[part 11 of 12: package /ComponentTypes]
AUTOSAR XML (schema 4-3-0)
package /ComponentTypes  (continued)
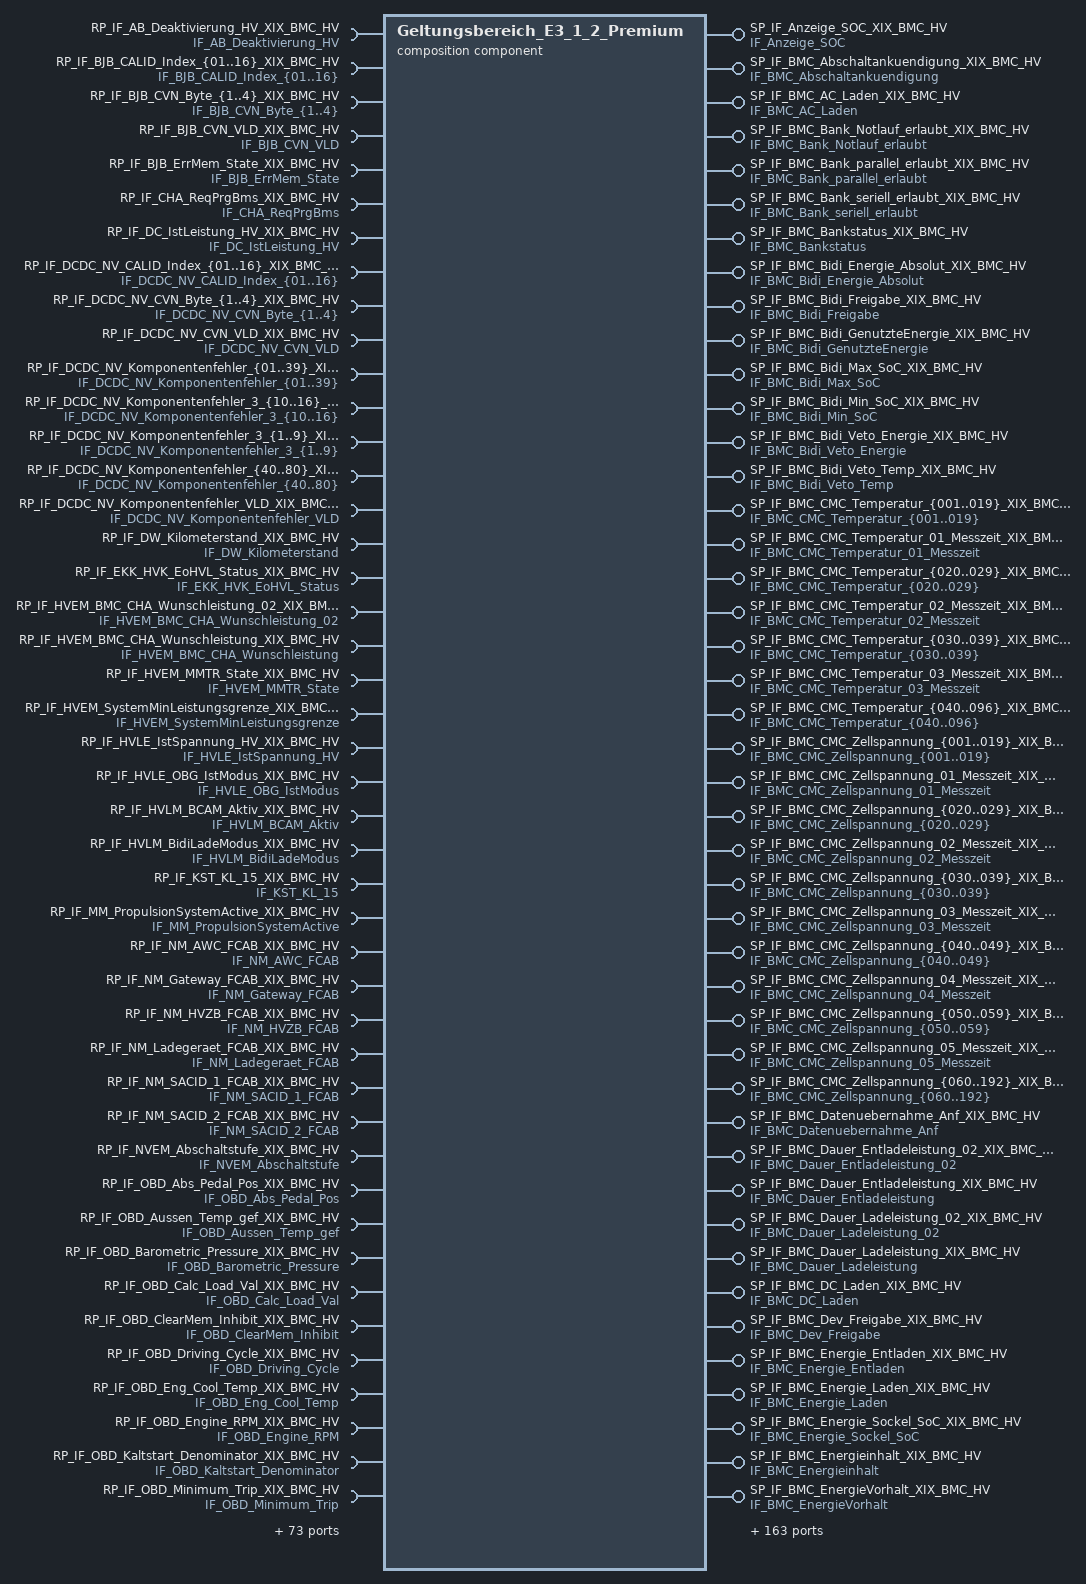
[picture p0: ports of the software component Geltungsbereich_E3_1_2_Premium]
  composition sw component type Geltungsbereich_E3_1_2_Premium
    519 x provide port:
      SP_IF_Anzeige_SOC_XIX_BMC_HV: provided-interface=IF_Anzeige_SOC
      SP_IF_BMC_Abschaltankuendigung_XIX_BMC_HV: provided-interface=IF_BMC_Abschaltankuendigung
      SP_IF_BMC_AC_Laden_XIX_BMC_HV: provided-interface=IF_BMC_AC_Laden
      SP_IF_BMC_Bank_Notlauf_erlaubt_XIX_BMC_HV: provided-interface=IF_BMC_Bank_Notlauf_erlaubt
      SP_IF_BMC_Bank_parallel_erlaubt_XIX_BMC_HV: provided-interface=IF_BMC_Bank_parallel_erlaubt
      SP_IF_BMC_Bank_seriell_erlaubt_XIX_BMC_HV: provided-interface=IF_BMC_Bank_seriell_erlaubt
      SP_IF_BMC_Bankstatus_XIX_BMC_HV: provided-interface=IF_BMC_Bankstatus
      SP_IF_BMC_Bidi_Energie_Absolut_XIX_BMC_HV: provided-interface=IF_BMC_Bidi_Energie_Absolut
      SP_IF_BMC_Bidi_Freigabe_XIX_BMC_HV: provided-interface=IF_BMC_Bidi_Freigabe
      SP_IF_BMC_Bidi_GenutzteEnergie_XIX_BMC_HV: provided-interface=IF_BMC_Bidi_GenutzteEnergie
      SP_IF_BMC_Bidi_Max_SoC_XIX_BMC_HV: provided-interface=IF_BMC_Bidi_Max_SoC
      SP_IF_BMC_Bidi_Min_SoC_XIX_BMC_HV: provided-interface=IF_BMC_Bidi_Min_SoC
      SP_IF_BMC_Bidi_Veto_Energie_XIX_BMC_HV: provided-interface=IF_BMC_Bidi_Veto_Energie
      SP_IF_BMC_Bidi_Veto_Temp_XIX_BMC_HV: provided-interface=IF_BMC_Bidi_Veto_Temp
      SP_IF_BMC_CMC_Temperatur_{001..019}_XIX_BMC_HV: provided-interface=IF_BMC_CMC_Temperatur_{001..019}
      SP_IF_BMC_CMC_Temperatur_01_Messzeit_XIX_BMC_HV: provided-interface=IF_BMC_CMC_Temperatur_01_Messzeit
      SP_IF_BMC_CMC_Temperatur_{020..029}_XIX_BMC_HV: provided-interface=IF_BMC_CMC_Temperatur_{020..029}
      SP_IF_BMC_CMC_Temperatur_02_Messzeit_XIX_BMC_HV: provided-interface=IF_BMC_CMC_Temperatur_02_Messzeit
      SP_IF_BMC_CMC_Temperatur_{030..039}_XIX_BMC_HV: provided-interface=IF_BMC_CMC_Temperatur_{030..039}
      SP_IF_BMC_CMC_Temperatur_03_Messzeit_XIX_BMC_HV: provided-interface=IF_BMC_CMC_Temperatur_03_Messzeit
      SP_IF_BMC_CMC_Temperatur_{040..096}_XIX_BMC_HV: provided-interface=IF_BMC_CMC_Temperatur_{040..096}
      SP_IF_BMC_CMC_Zellspannung_{001..019}_XIX_BMC_HV: provided-interface=IF_BMC_CMC_Zellspannung_{001..019}
      SP_IF_BMC_CMC_Zellspannung_01_Messzeit_XIX_BMC_HV: provided-interface=IF_BMC_CMC_Zellspannung_01_Messzeit
      SP_IF_BMC_CMC_Zellspannung_{020..029}_XIX_BMC_HV: provided-interface=IF_BMC_CMC_Zellspannung_{020..029}
      SP_IF_BMC_CMC_Zellspannung_02_Messzeit_XIX_BMC_HV: provided-interface=IF_BMC_CMC_Zellspannung_02_Messzeit
      SP_IF_BMC_CMC_Zellspannung_{030..039}_XIX_BMC_HV: provided-interface=IF_BMC_CMC_Zellspannung_{030..039}
      SP_IF_BMC_CMC_Zellspannung_03_Messzeit_XIX_BMC_HV: provided-interface=IF_BMC_CMC_Zellspannung_03_Messzeit
      SP_IF_BMC_CMC_Zellspannung_{040..049}_XIX_BMC_HV: provided-interface=IF_BMC_CMC_Zellspannung_{040..049}
      SP_IF_BMC_CMC_Zellspannung_04_Messzeit_XIX_BMC_HV: provided-interface=IF_BMC_CMC_Zellspannung_04_Messzeit
      SP_IF_BMC_CMC_Zellspannung_{050..059}_XIX_BMC_HV: provided-interface=IF_BMC_CMC_Zellspannung_{050..059}
      SP_IF_BMC_CMC_Zellspannung_05_Messzeit_XIX_BMC_HV: provided-interface=IF_BMC_CMC_Zellspannung_05_Messzeit
      SP_IF_BMC_CMC_Zellspannung_{060..192}_XIX_BMC_HV: provided-interface=IF_BMC_CMC_Zellspannung_{060..192}
      SP_IF_BMC_Datenuebernahme_Anf_XIX_BMC_HV: provided-interface=IF_BMC_Datenuebernahme_Anf
      SP_IF_BMC_Dauer_Entladeleistung_02_XIX_BMC_HV: provided-interface=IF_BMC_Dauer_Entladeleistung_02
      SP_IF_BMC_Dauer_Entladeleistung_XIX_BMC_HV: provided-interface=IF_BMC_Dauer_Entladeleistung
      SP_IF_BMC_Dauer_Ladeleistung_02_XIX_BMC_HV: provided-interface=IF_BMC_Dauer_Ladeleistung_02
      SP_IF_BMC_Dauer_Ladeleistung_XIX_BMC_HV: provided-interface=IF_BMC_Dauer_Ladeleistung
      SP_IF_BMC_DC_Laden_XIX_BMC_HV: provided-interface=IF_BMC_DC_Laden
      SP_IF_BMC_Dev_Freigabe_XIX_BMC_HV: provided-interface=IF_BMC_Dev_Freigabe
      SP_IF_BMC_Energie_Entladen_XIX_BMC_HV: provided-interface=IF_BMC_Energie_Entladen
      SP_IF_BMC_Energie_Laden_XIX_BMC_HV: provided-interface=IF_BMC_Energie_Laden
      SP_IF_BMC_Energie_Sockel_SoC_XIX_BMC_HV: provided-interface=IF_BMC_Energie_Sockel_SoC
      SP_IF_BMC_Energieinhalt_XIX_BMC_HV: provided-interface=IF_BMC_Energieinhalt
      SP_IF_BMC_EnergieVorhalt_XIX_BMC_HV: provided-interface=IF_BMC_EnergieVorhalt
      SP_IF_BMC_ExtLadeleistung_XIX_BMC_HV: provided-interface=IF_BMC_ExtLadeleistung
      SP_IF_BMC_Fehler_Leistungsred_XIX_BMC_HV: provided-interface=IF_BMC_Fehler_Leistungsred
      SP_IF_BMC_Fehler_Warnung_XIX_BMC_HV: provided-interface=IF_BMC_Fehler_Warnung
      SP_IF_BMC_Flash_Freigabe_XIX_BMC_HV: provided-interface=IF_BMC_Flash_Freigabe
      SP_IF_BMC_HV_01_BZ_XIX_BMC_HV: provided-interface=IF_BMC_HV_01_BZ
      SP_IF_BMC_HV_01_CRC_XIX_BMC_HV: provided-interface=IF_BMC_HV_01_CRC
      SP_IF_BMC_HV_02_BZ_XIX_BMC_HV: provided-interface=IF_BMC_HV_02_BZ
      SP_IF_BMC_HV_02_CRC_XIX_BMC_HV: provided-interface=IF_BMC_HV_02_CRC
      SP_IF_BMC_HV_04_BZ_XIX_BMC_HV: provided-interface=IF_BMC_HV_04_BZ
      SP_IF_BMC_HV_04_CRC_XIX_BMC_HV: provided-interface=IF_BMC_HV_04_CRC
      SP_IF_BMC_HV_10_BZ_XIX_BMC_HV: provided-interface=IF_BMC_HV_10_BZ
      SP_IF_BMC_HV_10_CRC_XIX_BMC_HV: provided-interface=IF_BMC_HV_10_CRC
      SP_IF_BMC_HV_11_BZ_XIX_BMC_HV: provided-interface=IF_BMC_HV_11_BZ
      SP_IF_BMC_HV_11_CRC_XIX_BMC_HV: provided-interface=IF_BMC_HV_11_CRC
      SP_IF_BMC_HV_12_BZ_XIX_BMC_HV: provided-interface=IF_BMC_HV_12_BZ
      SP_IF_BMC_HV_12_CRC_XIX_BMC_HV: provided-interface=IF_BMC_HV_12_CRC
      SP_IF_BMC_HV_13_BZ_XIX_BMC_HV: provided-interface=IF_BMC_HV_13_BZ
      SP_IF_BMC_HV_13_CRC_XIX_BMC_HV: provided-interface=IF_BMC_HV_13_CRC
      SP_IF_BMC_HVK_EoHVL_Status_XIX_BMC_HV: provided-interface=IF_BMC_HVK_EoHVL_Status
      SP_IF_BMC_HVK_Fehler_HVIL_XIX_BMC_HV: provided-interface=IF_BMC_HVK_Fehler_HVIL
      SP_IF_BMC_HVK_Fehler_Intern_XIX_BMC_HV: provided-interface=IF_BMC_HVK_Fehler_Intern
      SP_IF_BMC_HVK_Fehler_SD_XIX_BMC_HV: provided-interface=IF_BMC_HVK_Fehler_SD
      SP_IF_BMC_Iso_Mode_Anf_XIX_BMC_HV: provided-interface=IF_BMC_Iso_Mode_Anf
      SP_IF_BMC_IstTemperaturMax_Modul_ID_XIX_BMC_HV: provided-interface=IF_BMC_IstTemperaturMax_Modul_ID
      SP_IF_BMC_IstTemperaturMax_Sensor_ID_XIX_BMC_HV: provided-interface=IF_BMC_IstTemperaturMax_Sensor_ID
      SP_IF_BMC_IstTemperaturMin_Modul_ID_XIX_BMC_HV: provided-interface=IF_BMC_IstTemperaturMin_Modul_ID
      SP_IF_BMC_IstTemperaturMin_Sensor_ID_XIX_BMC_HV: provided-interface=IF_BMC_IstTemperaturMin_Sensor_ID
      SP_IF_BMC_IstZellSpannungMax_Modul_ID_XIX_BMC_HV: provided-interface=IF_BMC_IstZellSpannungMax_Modul_ID
      SP_IF_BMC_IstZellspannungMax_XIX_BMC_HV: provided-interface=IF_BMC_IstZellspannungMax
      SP_IF_BMC_IstZellSpannungMax_Zell_ID_XIX_BMC_HV: provided-interface=IF_BMC_IstZellSpannungMax_Zell_ID
      SP_IF_BMC_IstZellSpannungMin_Modul_ID_XIX_BMC_HV: provided-interface=IF_BMC_IstZellSpannungMin_Modul_ID
      SP_IF_BMC_IstZellspannungMin_XIX_BMC_HV: provided-interface=IF_BMC_IstZellspannungMin
      SP_IF_BMC_IstZellSpannungMin_Zell_ID_XIX_BMC_HV: provided-interface=IF_BMC_IstZellSpannungMin_Zell_ID
      SP_IF_BMC_IWU_Status_XIX_BMC_HV: provided-interface=IF_BMC_IWU_Status
      SP_IF_BMC_IWU_Wert_neg_XIX_BMC_HV: provided-interface=IF_BMC_IWU_Wert_neg
      SP_IF_BMC_IWU_Wert_pos_XIX_BMC_HV: provided-interface=IF_BMC_IWU_Wert_pos
      SP_IF_BMC_Konditionierung_Anf_XIX_BMC_HV: provided-interface=IF_BMC_Konditionierung_Anf
      SP_IF_BMC_KundenWarnung_XIX_BMC_HV: provided-interface=IF_BMC_KundenWarnung
      SP_IF_BMC_Lebensdauer_Trennelemente_XIX_BMC_HV: provided-interface=IF_BMC_Lebensdauer_Trennelemente
      SP_IF_BMC_Leerlaufspannung_XIX_BMC_HV: provided-interface=IF_BMC_Leerlaufspannung
      SP_IF_BMC_Max_Entladeleistung_02_XIX_BMC_HV: provided-interface=IF_BMC_Max_Entladeleistung_02
      SP_IF_BMC_Max_Entladeleistung_XIX_BMC_HV: provided-interface=IF_BMC_Max_Entladeleistung
      SP_IF_BMC_Max_Entladestrom_02_XIX_BMC_HV: provided-interface=IF_BMC_Max_Entladestrom_02
      SP_IF_BMC_Max_Entladestrom_XIX_BMC_HV: provided-interface=IF_BMC_Max_Entladestrom
      SP_IF_BMC_Max_Ladeleistung_02_XIX_BMC_HV: provided-interface=IF_BMC_Max_Ladeleistung_02
      SP_IF_BMC_Max_Ladeleistung_XIX_BMC_HV: provided-interface=IF_BMC_Max_Ladeleistung
      SP_IF_BMC_Max_Ladestrom_02_XIX_BMC_HV: provided-interface=IF_BMC_Max_Ladestrom_02
      SP_IF_BMC_Max_Ladestrom_XIX_BMC_HV: provided-interface=IF_BMC_Max_Ladestrom
      SP_IF_BMC_Max_Spannung_XIX_BMC_HV: provided-interface=IF_BMC_Max_Spannung
      SP_IF_BMC_MaxEnergieinhalt_XIX_BMC_HV: provided-interface=IF_BMC_MaxEnergieinhalt
      SP_IF_BMC_Min_Spannung_XIX_BMC_HV: provided-interface=IF_BMC_Min_Spannung
      SP_IF_BMC_MinDyn_Entladespannung_XIX_BMC_HV: provided-interface=IF_BMC_MinDyn_Entladespannung
      SP_IF_BMC_MinDyn_Ladespannung_XIX_BMC_HV: provided-interface=IF_BMC_MinDyn_Ladespannung
      SP_IF_BMC_MMTR_Status_XIX_BMC_HV: provided-interface=IF_BMC_MMTR_Status
      SP_IF_BMC_Modus_XIX_BMC_HV: provided-interface=IF_BMC_Modus
      SP_IF_BMC_NutzbareKapazitaet_XIX_BMC_HV: provided-interface=IF_BMC_NutzbareKapazitaet
      SP_IF_BMC_NutzbarerSOC_XIX_BMC_HV: provided-interface=IF_BMC_NutzbarerSOC
      SP_IF_BMC_Pack_SN_{01..26}_XIX_BMC_HV: provided-interface=IF_BMC_Pack_SN_{01..26}
      SP_IF_BMC_PCM_VTD_Freeze_Req_XIX_BMC_HV: provided-interface=IF_BMC_PCM_VTD_Freeze_Req
      SP_IF_BMC_PCM_VTD_LifeTimeReset_Req_XIX_BMC_HV: provided-interface=IF_BMC_PCM_VTD_LifeTimeReset_Req
      SP_IF_BMC_PCM_VTD_LifeTimeReset_Resp_XIX_BMC_HV: provided-interface=IF_BMC_PCM_VTD_LifeTimeReset_Resp
      SP_IF_BMC_PCM_VTD_RecentReset_Req_XIX_BMC_HV: provided-interface=IF_BMC_PCM_VTD_RecentReset_Req
      SP_IF_BMC_PerfInd_Entladen_XIX_BMC_HV: provided-interface=IF_BMC_PerfInd_Entladen
      SP_IF_BMC_PerfInd_Laden_XIX_BMC_HV: provided-interface=IF_BMC_PerfInd_Laden
      SP_IF_BMC_PredLeistung_StuetzungNV_XIX_BMC_HV: provided-interface=IF_BMC_PredLeistung_StuetzungNV
      SP_IF_BMC_Range_Indikator_XIX_BMC_HV: provided-interface=IF_BMC_Range_Indikator
      SP_IF_BMC_Rekuperation_Ueberlauf_XIX_BMC_HV: provided-interface=IF_BMC_Rekuperation_Ueberlauf
      SP_IF_BMC_Rekuperation_XIX_BMC_HV: provided-interface=IF_BMC_Rekuperation
      SP_IF_BMC_RtmWarnBattUnautorisiert_XIX_BMC_HV: provided-interface=IF_BMC_RtmWarnBattUnautorisiert
      SP_IF_BMC_RtmWarnPackKommunikation_XIX_BMC_HV: provided-interface=IF_BMC_RtmWarnPackKommunikation
      SP_IF_BMC_RtmWarnPackUeberladen_XIX_BMC_HV: provided-interface=IF_BMC_RtmWarnPackUeberladen
      SP_IF_BMC_RtmWarnSocHoch_XIX_BMC_HV: provided-interface=IF_BMC_RtmWarnSocHoch
      SP_IF_BMC_RtmWarnSocNiedrig_XIX_BMC_HV: provided-interface=IF_BMC_RtmWarnSocNiedrig
      SP_IF_BMC_RtmWarnSocSprung_XIX_BMC_HV: provided-interface=IF_BMC_RtmWarnSocSprung
      SP_IF_BMC_RtmWarnTZelleDiff_XIX_BMC_HV: provided-interface=IF_BMC_RtmWarnTZelleDiff
      SP_IF_BMC_RtmWarnTZelleMax_XIX_BMC_HV: provided-interface=IF_BMC_RtmWarnTZelleMax
      SP_IF_BMC_RtmWarnTZelleMin_XIX_BMC_HV: provided-interface=IF_BMC_RtmWarnTZelleMin
      SP_IF_BMC_RtmWarnUeberstrom_XIX_BMC_HV: provided-interface=IF_BMC_RtmWarnUeberstrom
      SP_IF_BMC_RtmWarnUPackMax_XIX_BMC_HV: provided-interface=IF_BMC_RtmWarnUPackMax
      SP_IF_BMC_RtmWarnUPackMin_XIX_BMC_HV: provided-interface=IF_BMC_RtmWarnUPackMin
      SP_IF_BMC_RtmWarnUZelleMax_XIX_BMC_HV: provided-interface=IF_BMC_RtmWarnUZelleMax
      SP_IF_BMC_RtmWarnUZelleMin_XIX_BMC_HV: provided-interface=IF_BMC_RtmWarnUZelleMin
      SP_IF_BMC_RtmWarnZelleZustand_XIX_BMC_HV: provided-interface=IF_BMC_RtmWarnZelleZustand
      SP_IF_BMC_RuecklaufTemperatur_XIX_BMC_HV: provided-interface=IF_BMC_RuecklaufTemperatur
      SP_IF_BMC_Spannung_DC_Ladesaeule_XIX_BMC_HV: provided-interface=IF_BMC_Spannung_DC_Ladesaeule
      SP_IF_BMC_Spannung_Messzeit_XIX_BMC_HV: provided-interface=IF_BMC_Spannung_Messzeit
      SP_IF_BMC_Spannung_XIX_BMC_HV: provided-interface=IF_BMC_Spannung
      SP_IF_BMC_Spannung_ZwischenKreis_2_XIX_BMC_HV: provided-interface=IF_BMC_Spannung_ZwischenKreis_2
      SP_IF_BMC_Spannung_ZwischenKreis_XIX_BMC_HV: provided-interface=IF_BMC_Spannung_ZwischenKreis
      SP_IF_BMC_Sperrung_Ueberspannung_XIX_BMC_HV: provided-interface=IF_BMC_Sperrung_Ueberspannung
      SP_IF_BMC_Sperrung_Uebertemperatur_XIX_BMC_HV: provided-interface=IF_BMC_Sperrung_Uebertemperatur
      SP_IF_BMC_Sperrung_Unterspannung_XIX_BMC_HV: provided-interface=IF_BMC_Sperrung_Unterspannung
      SP_IF_BMC_Status_DCLS_XIX_BMC_HV: provided-interface=IF_BMC_Status_DCLS
      SP_IF_BMC_Status_HV_Spannungssensorik_XIX_BMC_HV: provided-interface=IF_BMC_Status_HV_Spannungssensorik
      SP_IF_BMC_Status_Spgfreiheit_XIX_BMC_HV: provided-interface=IF_BMC_Status_Spgfreiheit
      SP_IF_BMC_Status_Trennelemente_XIX_BMC_HV: provided-interface=IF_BMC_Status_Trennelemente
      SP_IF_BMC_Strom_02_XIX_BMC_HV: provided-interface=IF_BMC_Strom_02
      SP_IF_BMC_Strom_Messzeit_XIX_BMC_HV: provided-interface=IF_BMC_Strom_Messzeit
      SP_IF_BMC_Strom_XIX_BMC_HV: provided-interface=IF_BMC_Strom
      SP_IF_BMC_TechnischerSOC_XIX_BMC_HV: provided-interface=IF_BMC_TechnischerSOC
      SP_IF_BMC_Temperatur_hoechste_XIX_BMC_HV: provided-interface=IF_BMC_Temperatur_hoechste
      SP_IF_BMC_Temperatur_niedrigste_XIX_BMC_HV: provided-interface=IF_BMC_Temperatur_niedrigste
      SP_IF_BMC_Temperatur_XIX_BMC_HV: provided-interface=IF_BMC_Temperatur
      SP_IF_BMC_ThermAuslastung_XIX_BMC_HV: provided-interface=IF_BMC_ThermAuslastung
      SP_IF_BMC_ThermSpreizung_XIX_BMC_HV: provided-interface=IF_BMC_ThermSpreizung
      SP_IF_BMC_UBE_Indik_last_update_km_XIX_BMC_HV: provided-interface=IF_BMC_UBE_Indik_last_update_km
      SP_IF_BMC_UBE_Indikator_XIX_BMC_HV: provided-interface=IF_BMC_UBE_Indikator
      SP_IF_BMC_Ueberspannungszaehler_CMC{01..04}_XIX_BMC_HV: provided-interface=IF_BMC_Ueberspannungszaehler_CMC{01..04}
      SP_IF_BMC_Uebertemperaturzaehler_CMC{01..04}_XIX_BMC_HV: provided-interface=IF_BMC_Uebertemperaturzaehler_CMC{01..04}
      SP_IF_BMC_UI1_Spannung1_Schalt_Anf_XIX_BMC_HV: provided-interface=IF_BMC_UI1_Spannung1_Schalt_Anf
      SP_IF_BMC_UI1_Spannung2_Schalt_Anf_XIX_BMC_HV: provided-interface=IF_BMC_UI1_Spannung2_Schalt_Anf
      SP_IF_BMC_UI2_Spannung1_Schalt_Anf_XIX_BMC_HV: provided-interface=IF_BMC_UI2_Spannung1_Schalt_Anf
      SP_IF_BMC_UI2_Spannung2_Schalt_Anf_XIX_BMC_HV: provided-interface=IF_BMC_UI2_Spannung2_Schalt_Anf
      SP_IF_BMC_Unterboden_Warnung_XIX_BMC_HV: provided-interface=IF_BMC_Unterboden_Warnung
      SP_IF_BMC_Unterspannungszaehler_CMC{01..04}_XIX_BMC_HV: provided-interface=IF_BMC_Unterspannungszaehler_CMC{01..04}
      SP_IF_BMC_Verbauinfo_ACSchuetz_XIX_BMC_HV: provided-interface=IF_BMC_Verbauinfo_ACSchuetz
      SP_IF_BMC_Verbauinfo_Bank_XIX_BMC_HV: provided-interface=IF_BMC_Verbauinfo_Bank
      SP_IF_BMC_Verbrauch_Ueberlauf_XIX_BMC_HV: provided-interface=IF_BMC_Verbrauch_Ueberlauf
      SP_IF_BMC_Verbrauch_XIX_BMC_HV: provided-interface=IF_BMC_Verbrauch
      SP_IF_BMC_VerlustEnergie_XIX_BMC_HV: provided-interface=IF_BMC_VerlustEnergie
      SP_IF_BMC_Vorlade_Zielspannung_XIX_BMC_HV: provided-interface=IF_BMC_Vorlade_Zielspannung
      SP_IF_BMC_VorlaufTemperatur_XIX_BMC_HV: provided-interface=IF_BMC_VorlaufTemperatur
      SP_IF_BMC_ZellTemp_virtuell_max_XIX_BMC_HV: provided-interface=IF_BMC_ZellTemp_virtuell_max
      SP_IF_BMC_ZellTemp_virtuell_min_XIX_BMC_HV: provided-interface=IF_BMC_ZellTemp_virtuell_min
      SP_IF_DS_Hybrid_01_ConfDTCChanged_XIX_BMC_HV: provided-interface=IF_DS_Hybrid_01_ConfDTCChanged
      SP_IF_DS_Hybrid_01_DiagAdr_XIX_BMC_HV: provided-interface=IF_DS_Hybrid_01_DiagAdr
      SP_IF_DS_Hybrid_01_IdentValid_XIX_BMC_HV: provided-interface=IF_DS_Hybrid_01_IdentValid
      SP_IF_DS_Hybrid_01_Lokalaktiv_XIX_BMC_HV: provided-interface=IF_DS_Hybrid_01_Lokalaktiv
      SP_IF_DS_Hybrid_01_MemSel10Changed_XIX_BMC_HV: provided-interface=IF_DS_Hybrid_01_MemSel10Changed
      SP_IF_DS_Hybrid_01_MemSelChanged_XIX_BMC_HV: provided-interface=IF_DS_Hybrid_01_MemSelChanged
      SP_IF_DS_Hybrid_01_StMemChanged_XIX_BMC_HV: provided-interface=IF_DS_Hybrid_01_StMemChanged
      SP_IF_DS_Hybrid_01_Subsystemaktiv_XIX_BMC_HV: provided-interface=IF_DS_Hybrid_01_Subsystemaktiv
      SP_IF_DS_Hybrid_01_TestFailedChanged_XIX_BMC_HV: provided-interface=IF_DS_Hybrid_01_TestFailedChanged
      SP_IF_DS_Hybrid_01_WIRChanged_XIX_BMC_HV: provided-interface=IF_DS_Hybrid_01_WIRChanged
      SP_IF_Hybrid_01_Indc_StChk_XIX_BMC_HV: provided-interface=IF_Hybrid_01_Indc_StChk
      SP_IF_Hybrid_01_Indc_StFail_XIX_BMC_HV: provided-interface=IF_Hybrid_01_Indc_StFail
      SP_IF_Hybrid_01_KD_Fehler_XIX_BMC_HV: provided-interface=IF_Hybrid_01_KD_Fehler
      SP_IF_Hybrid_01_Nachlauftyp_XIX_BMC_HV: provided-interface=IF_Hybrid_01_Nachlauftyp
      SP_IF_Hybrid_01_OBD_Lampe_Anf_XIX_BMC_HV: provided-interface=IF_Hybrid_01_OBD_Lampe_Anf
      SP_IF_Hybrid_01_SNI_10_XIX_BMC_HV: provided-interface=IF_Hybrid_01_SNI_10
      SP_IF_KN_Hybrid_01_DiagPfad_V12_XIX_BMC_HV: provided-interface=IF_KN_Hybrid_01_DiagPfad_V12
      SP_IF_KS_Hybrid_01_ChK_IKACtr_XIX_BMC_HV: provided-interface=IF_KS_Hybrid_01_ChK_IKACtr
      SP_IF_KS_Hybrid_01_ChK_SID_XIX_BMC_HV: provided-interface=IF_KS_Hybrid_01_ChK_SID
      SP_IF_KS_Hybrid_01_ChK_XIX_BMC_HV: provided-interface=IF_KS_Hybrid_01_ChK
      SP_IF_KS_Hybrid_01_ReK_IKACtr_XIX_BMC_HV: provided-interface=IF_KS_Hybrid_01_ReK_IKACtr
      SP_IF_KS_Hybrid_01_ReK_SID_XIX_BMC_HV: provided-interface=IF_KS_Hybrid_01_ReK_SID
      SP_IF_KS_Hybrid_01_ReK_XIX_BMC_HV: provided-interface=IF_KS_Hybrid_01_ReK
      SP_IF_KS_Hybrid_01_Req_ErrCtr_XIX_BMC_HV: provided-interface=IF_KS_Hybrid_01_Req_ErrCtr
      SP_IF_KS_Hybrid_01_Req_IKA_Retry_XIX_BMC_HV: provided-interface=IF_KS_Hybrid_01_Req_IKA_Retry
      SP_IF_KS_Hybrid_01_Req_Prio_XIX_BMC_HV: provided-interface=IF_KS_Hybrid_01_Req_Prio
      SP_IF_KS_Hybrid_01_Req_SID_XIX_BMC_HV: provided-interface=IF_KS_Hybrid_01_Req_SID
      SP_IF_KS_Hybrid_01_Req_SWMaj_XIX_BMC_HV: provided-interface=IF_KS_Hybrid_01_Req_SWMaj
      SP_IF_KS_Hybrid_01_Req_SWMin_XIX_BMC_HV: provided-interface=IF_KS_Hybrid_01_Req_SWMin
      SP_IF_KS_Hybrid_01_Req_SWPat_XIX_BMC_HV: provided-interface=IF_KS_Hybrid_01_Req_SWPat
      SP_IF_KS_Hybrid_01_Req_VKMS_Err_XIX_BMC_HV: provided-interface=IF_KS_Hybrid_01_Req_VKMS_Err
      SP_IF_NM_Hybrid_01_CAB_V12_XIX_BMC_HV: provided-interface=IF_NM_Hybrid_01_CAB_V12
      SP_IF_NM_Hybrid_01_CBV_AWB_XIX_BMC_HV: provided-interface=IF_NM_Hybrid_01_CBV_AWB
      SP_IF_NM_Hybrid_01_FCAB_XIX_BMC_HV: provided-interface=IF_NM_Hybrid_01_FCAB
      SP_IF_NM_Hybrid_01_FCIB_XIX_BMC_HV: provided-interface=IF_NM_Hybrid_01_FCIB
      SP_IF_NM_Hybrid_01_NM_State_XIX_BMC_HV: provided-interface=IF_NM_Hybrid_01_NM_State
      SP_IF_NM_Hybrid_01_SNI_10_XIX_BMC_HV: provided-interface=IF_NM_Hybrid_01_SNI_10
      SP_IF_OBDProtocol_Hybrid_01_XIX_BMC_HV: provided-interface=IF_OBDProtocol_Hybrid_01
      SP_IF_SOK_Zeit_Hybrid_01_Challenge_XIX_BMC_HV: provided-interface=IF_SOK_Zeit_Hybrid_01_Challenge
    383 x require port:
      RP_IF_AB_Deaktivierung_HV_XIX_BMC_HV: required-interface=IF_AB_Deaktivierung_HV
      RP_IF_BJB_CALID_Index_{01..16}_XIX_BMC_HV: required-interface=IF_BJB_CALID_Index_{01..16}
      RP_IF_BJB_CVN_Byte_{1..4}_XIX_BMC_HV: required-interface=IF_BJB_CVN_Byte_{1..4}
      RP_IF_BJB_CVN_VLD_XIX_BMC_HV: required-interface=IF_BJB_CVN_VLD
      RP_IF_BJB_ErrMem_State_XIX_BMC_HV: required-interface=IF_BJB_ErrMem_State
      RP_IF_CHA_ReqPrgBms_XIX_BMC_HV: required-interface=IF_CHA_ReqPrgBms
      RP_IF_DC_IstLeistung_HV_XIX_BMC_HV: required-interface=IF_DC_IstLeistung_HV
      RP_IF_DCDC_NV_CALID_Index_{01..16}_XIX_BMC_HV: required-interface=IF_DCDC_NV_CALID_Index_{01..16}
      RP_IF_DCDC_NV_CVN_Byte_{1..4}_XIX_BMC_HV: required-interface=IF_DCDC_NV_CVN_Byte_{1..4}
      RP_IF_DCDC_NV_CVN_VLD_XIX_BMC_HV: required-interface=IF_DCDC_NV_CVN_VLD
      RP_IF_DCDC_NV_Komponentenfehler_{01..39}_XIX_BMC_HV: required-interface=IF_DCDC_NV_Komponentenfehler_{01..39}
      RP_IF_DCDC_NV_Komponentenfehler_3_{10..16}_XIX_BMC_HV: required-interface=IF_DCDC_NV_Komponentenfehler_3_{10..16}
      RP_IF_DCDC_NV_Komponentenfehler_3_{1..9}_XIX_BMC_HV: required-interface=IF_DCDC_NV_Komponentenfehler_3_{1..9}
      RP_IF_DCDC_NV_Komponentenfehler_{40..80}_XIX_BMC_HV: required-interface=IF_DCDC_NV_Komponentenfehler_{40..80}
      RP_IF_DCDC_NV_Komponentenfehler_VLD_XIX_BMC_HV: required-interface=IF_DCDC_NV_Komponentenfehler_VLD
      RP_IF_DW_Kilometerstand_XIX_BMC_HV: required-interface=IF_DW_Kilometerstand
      RP_IF_EKK_HVK_EoHVL_Status_XIX_BMC_HV: required-interface=IF_EKK_HVK_EoHVL_Status
      RP_IF_HVEM_BMC_CHA_Wunschleistung_02_XIX_BMC_HV: required-interface=IF_HVEM_BMC_CHA_Wunschleistung_02
      RP_IF_HVEM_BMC_CHA_Wunschleistung_XIX_BMC_HV: required-interface=IF_HVEM_BMC_CHA_Wunschleistung
      RP_IF_HVEM_MMTR_State_XIX_BMC_HV: required-interface=IF_HVEM_MMTR_State
      RP_IF_HVEM_SystemMinLeistungsgrenze_XIX_BMC_HV: required-interface=IF_HVEM_SystemMinLeistungsgrenze
      RP_IF_HVLE_IstSpannung_HV_XIX_BMC_HV: required-interface=IF_HVLE_IstSpannung_HV
      RP_IF_HVLE_OBG_IstModus_XIX_BMC_HV: required-interface=IF_HVLE_OBG_IstModus
      RP_IF_HVLM_BCAM_Aktiv_XIX_BMC_HV: required-interface=IF_HVLM_BCAM_Aktiv
      RP_IF_HVLM_BidiLadeModus_XIX_BMC_HV: required-interface=IF_HVLM_BidiLadeModus
      RP_IF_KST_KL_15_XIX_BMC_HV: required-interface=IF_KST_KL_15
      RP_IF_MM_PropulsionSystemActive_XIX_BMC_HV: required-interface=IF_MM_PropulsionSystemActive
      RP_IF_NM_AWC_FCAB_XIX_BMC_HV: required-interface=IF_NM_AWC_FCAB
      RP_IF_NM_Gateway_FCAB_XIX_BMC_HV: required-interface=IF_NM_Gateway_FCAB
      RP_IF_NM_HVZB_FCAB_XIX_BMC_HV: required-interface=IF_NM_HVZB_FCAB
      RP_IF_NM_Ladegeraet_FCAB_XIX_BMC_HV: required-interface=IF_NM_Ladegeraet_FCAB
      RP_IF_NM_SACID_1_FCAB_XIX_BMC_HV: required-interface=IF_NM_SACID_1_FCAB
      RP_IF_NM_SACID_2_FCAB_XIX_BMC_HV: required-interface=IF_NM_SACID_2_FCAB
      RP_IF_NVEM_Abschaltstufe_XIX_BMC_HV: required-interface=IF_NVEM_Abschaltstufe
      RP_IF_OBD_Abs_Pedal_Pos_XIX_BMC_HV: required-interface=IF_OBD_Abs_Pedal_Pos
      RP_IF_OBD_Aussen_Temp_gef_XIX_BMC_HV: required-interface=IF_OBD_Aussen_Temp_gef
      RP_IF_OBD_Barometric_Pressure_XIX_BMC_HV: required-interface=IF_OBD_Barometric_Pressure
      RP_IF_OBD_Calc_Load_Val_XIX_BMC_HV: required-interface=IF_OBD_Calc_Load_Val
      RP_IF_OBD_ClearMem_Inhibit_XIX_BMC_HV: required-interface=IF_OBD_ClearMem_Inhibit
      RP_IF_OBD_Driving_Cycle_XIX_BMC_HV: required-interface=IF_OBD_Driving_Cycle
      RP_IF_OBD_Eng_Cool_Temp_XIX_BMC_HV: required-interface=IF_OBD_Eng_Cool_Temp
      RP_IF_OBD_Engine_RPM_XIX_BMC_HV: required-interface=IF_OBD_Engine_RPM
      RP_IF_OBD_Kaltstart_Denominator_XIX_BMC_HV: required-interface=IF_OBD_Kaltstart_Denominator
      RP_IF_OBD_Minimum_Trip_XIX_BMC_HV: required-interface=IF_OBD_Minimum_Trip
      RP_IF_OBD_Normed_Trip_XIX_BMC_HV: required-interface=IF_OBD_Normed_Trip
      RP_IF_OBD_NumDcyMilOnReq_XIX_BMC_HV: required-interface=IF_OBD_NumDcyMilOnReq
      RP_IF_OBD_QBit_Aussen_Temp_XIX_BMC_HV: required-interface=IF_OBD_QBit_Aussen_Temp
      RP_IF_OBD_Sperrung_IUMPR_XIX_BMC_HV: required-interface=IF_OBD_Sperrung_IUMPR
      RP_IF_OBD_Sperrung_Kaltstart_Denom_XIX_BMC_HV: required-interface=IF_OBD_Sperrung_Kaltstart_Denom
      RP_IF_OBD_Typ_XIX_BMC_HV: required-interface=IF_OBD_Typ
      RP_IF_OBD_Warm_Up_Cycle_XIX_BMC_HV: required-interface=IF_OBD_Warm_Up_Cycle
      RP_IF_OBDProtocol_req_XIX_BMC_HV: required-interface=IF_OBDProtocol_req
      RP_IF_ORU_Status_XIX_BMC_HV: required-interface=IF_ORU_Status
      RP_IF_OTP_Aussen_Temp_OBD_XIX_BMC_HV: required-interface=IF_OTP_Aussen_Temp_OBD
      RP_IF_OTP_Aussen_Temp_ungef_XIX_BMC_HV: required-interface=IF_OTP_Aussen_Temp_ungef
      RP_IF_PCM_BMC_VTD_Freeze_Req_XIX_BMC_HV: required-interface=IF_PCM_BMC_VTD_Freeze_Req
      RP_IF_PCM_BMC_VTD_LifeTimeReset_Req_XIX_BMC_HV: required-interface=IF_PCM_BMC_VTD_LifeTimeReset_Req
      RP_IF_PCM_BMC_VTD_LifeTimeReset_Resp_XIX_BMC_HV: required-interface=IF_PCM_BMC_VTD_LifeTimeReset_Resp
      RP_IF_PCM_BMC_VTD_RecentReset_Req_XIX_BMC_HV: required-interface=IF_PCM_BMC_VTD_RecentReset_Req
      RP_IF_SG_BJB_{10..13}_XIX_BMC_HV: required-interface=IF_SG_BJB_{10..13}
      RP_IF_SG_HVK_03_XIX_BMC_HV: required-interface=IF_SG_HVK_03
      RP_IF_SG_HVLM_14_XIX_BMC_HV: required-interface=IF_SG_HVLM_14
      RP_IF_SG_KS_Hybrid_01_Challenge_M_XIX_BMC_HV: required-interface=IF_SG_KS_Hybrid_01_Challenge_M
      RP_IF_SG_KS_Hybrid_01_Response_M_XIX_BMC_HV: required-interface=IF_SG_KS_Hybrid_01_Response_M
      RP_IF_SG_ORU_Control_A_01_XIX_BMC_HV: required-interface=IF_SG_ORU_Control_A_01
      RP_IF_SG_ORU_Control_D_01_XIX_BMC_HV: required-interface=IF_SG_ORU_Control_D_01
      RP_IF_SG_OTAMC_D_01_XIX_BMC_HV: required-interface=IF_SG_OTAMC_D_01
      RP_IF_SG_UI1_01_XIX_BMC_HV: required-interface=IF_SG_UI1_01
      RP_IF_SG_UI1_02_XIX_BMC_HV: required-interface=IF_SG_UI1_02
      RP_IF_SG_UI2_{01..03}_XIX_BMC_HV: required-interface=IF_SG_UI2_{01..03}
      RP_IF_SI_NWDF_30_XIX_BMC_HV: required-interface=IF_SI_NWDF_30
      RP_IF_SI_NWDF_XIX_BMC_HV: required-interface=IF_SI_NWDF
      RP_IF_SI_P_Mode_gueltig_XIX_BMC_HV: required-interface=IF_SI_P_Mode_gueltig
      RP_IF_SI_P_Mode_XIX_BMC_HV: required-interface=IF_SI_P_Mode
      RP_IF_SI_T_Mode_XIX_BMC_HV: required-interface=IF_SI_T_Mode
      RP_IF_SOK_ungeschuetzte_Zeit_XIX_BMC_HV: required-interface=IF_SOK_ungeschuetzte_Zeit
      RP_IF_SOK_Zeit_Hybrid_01_Zeit_XIX_BMC_HV: required-interface=IF_SOK_Zeit_Hybrid_01_Zeit
      RP_IF_TME_Batt_Kond_Verf_XIX_BMC_HV: required-interface=IF_TME_Batt_Kond_Verf
      RP_IF_TME_Therm_IstLeistung_HVBatterie_XIX_BMC_HV: required-interface=IF_TME_Therm_IstLeistung_HVBatterie
      RP_IF_UH_Jahr_XIX_BMC_HV: required-interface=IF_UH_Jahr
      RP_IF_UH_Minute_XIX_BMC_HV: required-interface=IF_UH_Minute
      RP_IF_UH_Monat_XIX_BMC_HV: required-interface=IF_UH_Monat
      RP_IF_UH_Sekunde_XIX_BMC_HV: required-interface=IF_UH_Sekunde
      RP_IF_UH_Stunde_XIX_BMC_HV: required-interface=IF_UH_Stunde
      RP_IF_UH_Tag_XIX_BMC_HV: required-interface=IF_UH_Tag
      RP_IF_UI1_Iso_Neg_XIX_BMC_HV: required-interface=IF_UI1_Iso_Neg
      RP_IF_UI1_Iso_Pos_XIX_BMC_HV: required-interface=IF_UI1_Iso_Pos
      RP_IF_UI1_Iso_Status_XIX_BMC_HV: required-interface=IF_UI1_Iso_Status
      RP_IF_UI1_KompFehlerModus2_{01..26}_XIX_BMC_HV: required-interface=IF_UI1_KompFehlerModus2_{01..26}
      RP_IF_UI1_KompFehlerModus4_{01..16}_XIX_BMC_HV: required-interface=IF_UI1_KompFehlerModus4_{01..16}
      RP_IF_UI1_Spannung{4..6}_XIX_BMC_HV: required-interface=IF_UI1_Spannung{4..6}
      RP_IF_UI1_Status_XIX_BMC_HV: required-interface=IF_UI1_Status
      RP_IF_UI1_Stromintegral_Entladen_XIX_BMC_HV: required-interface=IF_UI1_Stromintegral_Entladen
      RP_IF_UI1_Stromintegral_Laden_XIX_BMC_HV: required-interface=IF_UI1_Stromintegral_Laden
      RP_IF_UI1_Temperatur_1_XIX_BMC_HV: required-interface=IF_UI1_Temperatur_1
      RP_IF_UI1_Temperatur_2_XIX_BMC_HV: required-interface=IF_UI1_Temperatur_2
      RP_IF_UI2_KompFehlerModus2_{01..26}_XIX_BMC_HV: required-interface=IF_UI2_KompFehlerModus2_{01..26}
      RP_IF_UI2_KompFehlerModus4_{01..16}_XIX_BMC_HV: required-interface=IF_UI2_KompFehlerModus4_{01..16}
      RP_IF_UI2_Status_XIX_BMC_HV: required-interface=IF_UI2_Status
      RP_IF_UI2_Stromintegral_Entladen_XIX_BMC_HV: required-interface=IF_UI2_Stromintegral_Entladen
      RP_IF_UI2_Stromintegral_Laden_XIX_BMC_HV: required-interface=IF_UI2_Stromintegral_Laden
      RP_IF_UI2_Temperatur_1_XIX_BMC_HV: required-interface=IF_UI2_Temperatur_1
      RP_IF_UI2_Temperatur_2_XIX_BMC_HV: required-interface=IF_UI2_Temperatur_2
      RP_IF_UI2Sens01_CALID_Index_{01..16}_XIX_BMC_HV: required-interface=IF_UI2Sens01_CALID_Index_{01..16}
      RP_IF_UI2Sens01_CVN_Byte_{1..4}_XIX_BMC_HV: required-interface=IF_UI2Sens01_CVN_Byte_{1..4}
      RP_IF_UI2Sens01_CVN_VLD_XIX_BMC_HV: required-interface=IF_UI2Sens01_CVN_VLD
      RP_IF_UI2Sens01_ErrMem_State_XIX_BMC_HV: required-interface=IF_UI2Sens01_ErrMem_State
      RP_IF_UI2Sens02_CALID_Index_{01..16}_XIX_BMC_HV: required-interface=IF_UI2Sens02_CALID_Index_{01..16}
      RP_IF_UI2Sens02_CVN_Byte_{1..4}_XIX_BMC_HV: required-interface=IF_UI2Sens02_CVN_Byte_{1..4}
      RP_IF_UI2Sens02_CVN_VLD_XIX_BMC_HV: required-interface=IF_UI2Sens02_CVN_VLD
      RP_IF_UI2Sens02_ErrMem_State_XIX_BMC_HV: required-interface=IF_UI2Sens02_ErrMem_State
      RP_IF_VDSO_Vx3d_XIX_BMC_HV: required-interface=IF_VDSO_Vx3d
      RP_IF_VIN_{10..17}_XIX_BMC_HV: required-interface=IF_VIN_{10..17}
      RP_IF_VIN_{1..9}_XIX_BMC_HV: required-interface=IF_VIN_{1..9}
      RP_IF_ZM_HV_Auszeit_HiRes_XIX_BMC_HV: required-interface=IF_ZM_HV_Auszeit_HiRes
      RP_IF_ZM_HV_Auszeit_Status_XIX_BMC_HV: required-interface=IF_ZM_HV_Auszeit_Status
      RP_IF_ZM_HV_Auszeit_XIX_BMC_HV: required-interface=IF_ZM_HV_Auszeit
    15 x component:
      BMC_Berechnung_SOC_XIX_SoC_XIX_BMC_HV: type=BMC_Berechnung_SOC_XIX_SoC_XIX_BMC_HV
      BMC_HVS_Slave_XIX_SoC_XIX_BMC_HV: type=BMC_HVS_Slave_XIX_SoC_XIX_BMC_HV
      BMC_HV_Netzsteuerung_XIX_NV_SD_XIX_BMC_HV: type=BMC_HV_Netzsteuerung_XIX_NV_SD_XIX_BMC_HV
      BMC_SafetyDataStorage_XIX_SoC_XIX_BMC_HV: type=BMC_SafetyDataStorage_XIX_SoC_XIX_BMC_HV
      DaapServer_BMC_HV_XIX_GDC_DAAP_XIX_BMC_HV: type=DaapServer_BMC_HV_XIX_GDC_DAAP_XIX_BMC_HV
      HVB_Fehlerausgabe_SecondaryOBDECU_XIX_SoC_XIX_BMC_HV: type=HVB_Fehlerausgabe_SecondaryOBDECU_XIX_SoC_XIX_BMC_HV
      HV_Batterie_RTM_XIX_RTM_XIX_BMC_HV: type=HV_Batterie_RTM_XIX_RTM_XIX_BMC_HV
      HochvoltBatterieManagement_XIX_SoC_XIX_BMC_HV: type=HochvoltBatterieManagement_XIX_SoC_XIX_BMC_HV
      Infrastructure_Hybrid_01_XIX_network_infrastructure_XIX_BMC_HV: type=Infrastructure_Hybrid_01_XIX_network_infrastructure_XIX_BMC_HV
      KS_BMC_HV_XIX_KSGen3_XIX_BMC_HV: type=KS_BMC_HV_XIX_KSGen3_XIX_BMC_HV
      ORU_Infrastructure_Hybrid_01_XIX_ORU6_XIX_BMC_HV: type=ORU_Infrastructure_Hybrid_01_XIX_ORU6_XIX_BMC_HV
      OTA_Infrastructure_Hybrid_01_XIX_ORU6_XIX_BMC_HV: type=OTA_Infrastructure_Hybrid_01_XIX_ORU6_XIX_BMC_HV
      SOK_Participant_BMC_HV_XIX_SOK_XIX_BMC_HV: type=SOK_Participant_BMC_HV_XIX_SOK_XIX_BMC_HV
      VKMS_Participant_BMC_HV_XIX_VKMS_XIX_BMC_HV: type=VKMS_Participant_BMC_HV_XIX_VKMS_XIX_BMC_HV
      diagnosis_infrastructure_Hybrid_01_XIX_diagnosis_infrastructure_XIX_BMC_HV: type=diagnosis_infrastructure_Hybrid_01_XIX_diagnosis_infrastructure_XIX_BMC_HV
    delegate HochvoltBatterieManagement_XIX_SoC_XIX_BMC_HV.RP_IF_AB_Deaktivierung_HV_XIX_HochvoltBatterieManagement_XIX_SoC_XIX_BMC_HV <-> outer port RP_IF_AB_Deaktivierung_HV_XIX_BMC_HV  # _XIX_AirbagFunctions_XIX_AirbagBasisFunktionen_XIX_Airbag_6D_XIX_HochvoltBatterieManagement_XIX_SoC_XIX_BMC_HV_XIX_AB_Deaktivierung_HV
    delegate BMC_Berechnung_SOC_XIX_SoC_XIX_BMC_HV.SP_IF_Anzeige_SOC_XIX_BMC_Berechnung_SOC_XIX_SoC_XIX_BMC_HV <-> outer port SP_IF_Anzeige_SOC_XIX_BMC_HV
    delegate BMC_HVS_Slave_XIX_SoC_XIX_BMC_HV.SP_IF_BMC_HVK_EoHVL_Status_XIX_BMC_HVS_Slave_XIX_SoC_XIX_BMC_HV <-> outer port SP_IF_BMC_HVK_EoHVL_Status_XIX_BMC_HV
    delegate BMC_HVS_Slave_XIX_SoC_XIX_BMC_HV.SP_IF_BMC_HVK_Fehler_HVIL_XIX_BMC_HVS_Slave_XIX_SoC_XIX_BMC_HV <-> outer port SP_IF_BMC_HVK_Fehler_HVIL_XIX_BMC_HV
    delegate BMC_HVS_Slave_XIX_SoC_XIX_BMC_HV.SP_IF_BMC_HVK_Fehler_Intern_XIX_BMC_HVS_Slave_XIX_SoC_XIX_BMC_HV <-> outer port SP_IF_BMC_HVK_Fehler_Intern_XIX_BMC_HV
    delegate BMC_HVS_Slave_XIX_SoC_XIX_BMC_HV.SP_IF_BMC_HVK_Fehler_SD_XIX_BMC_HVS_Slave_XIX_SoC_XIX_BMC_HV <-> outer port SP_IF_BMC_HVK_Fehler_SD_XIX_BMC_HV
    delegate BMC_HVS_Slave_XIX_SoC_XIX_BMC_HV.SP_IF_BMC_IWU_Status_XIX_BMC_HVS_Slave_XIX_SoC_XIX_BMC_HV <-> outer port SP_IF_BMC_IWU_Status_XIX_BMC_HV
    delegate BMC_HVS_Slave_XIX_SoC_XIX_BMC_HV.SP_IF_BMC_IWU_Wert_neg_XIX_BMC_HVS_Slave_XIX_SoC_XIX_BMC_HV <-> outer port SP_IF_BMC_IWU_Wert_neg_XIX_BMC_HV
    delegate BMC_HVS_Slave_XIX_SoC_XIX_BMC_HV.SP_IF_BMC_IWU_Wert_pos_XIX_BMC_HVS_Slave_XIX_SoC_XIX_BMC_HV <-> outer port SP_IF_BMC_IWU_Wert_pos_XIX_BMC_HV
    delegate BMC_HVS_Slave_XIX_SoC_XIX_BMC_HV.SP_IF_BMC_Status_Spgfreiheit_XIX_BMC_HVS_Slave_XIX_SoC_XIX_BMC_HV <-> outer port SP_IF_BMC_Status_Spgfreiheit_XIX_BMC_HV
    delegate BMC_HV_Netzsteuerung_XIX_NV_SD_XIX_BMC_HV.SP_IF_BMC_Modus_XIX_BMC_HV_Netzsteuerung_XIX_NV_SD_XIX_BMC_HV <-> outer port SP_IF_BMC_Modus_XIX_BMC_HV
    delegate BMC_HV_Netzsteuerung_XIX_NV_SD_XIX_BMC_HV.SP_IF_BMC_Vorlade_Zielspannung_XIX_BMC_HV_Netzsteuerung_XIX_NV_SD_XIX_BMC_HV <-> outer port SP_IF_BMC_Vorlade_Zielspannung_XIX_BMC_HV
    delegate BMC_SafetyDataStorage_XIX_SoC_XIX_BMC_HV.SP_IF_BMC_Datenuebernahme_Anf_XIX_BMC_SafetyDataStorage_XIX_SoC_XIX_BMC_HV <-> outer port SP_IF_BMC_Datenuebernahme_Anf_XIX_BMC_HV
    delegate BMC_SafetyDataStorage_XIX_SoC_XIX_BMC_HV.SP_IF_BMC_HV_10_BZ_XIX_BMC_SafetyDataStorage_XIX_SoC_XIX_BMC_HV <-> outer port SP_IF_BMC_HV_10_BZ_XIX_BMC_HV
    delegate BMC_SafetyDataStorage_XIX_SoC_XIX_BMC_HV.SP_IF_BMC_HV_10_CRC_XIX_BMC_SafetyDataStorage_XIX_SoC_XIX_BMC_HV <-> outer port SP_IF_BMC_HV_10_CRC_XIX_BMC_HV
    delegate BMC_SafetyDataStorage_XIX_SoC_XIX_BMC_HV.SP_IF_BMC_HV_11_BZ_XIX_BMC_SafetyDataStorage_XIX_SoC_XIX_BMC_HV <-> outer port SP_IF_BMC_HV_11_BZ_XIX_BMC_HV
    delegate BMC_SafetyDataStorage_XIX_SoC_XIX_BMC_HV.SP_IF_BMC_HV_11_CRC_XIX_BMC_SafetyDataStorage_XIX_SoC_XIX_BMC_HV <-> outer port SP_IF_BMC_HV_11_CRC_XIX_BMC_HV
    delegate BMC_SafetyDataStorage_XIX_SoC_XIX_BMC_HV.SP_IF_BMC_HV_12_BZ_XIX_BMC_SafetyDataStorage_XIX_SoC_XIX_BMC_HV <-> outer port SP_IF_BMC_HV_12_BZ_XIX_BMC_HV
    delegate BMC_SafetyDataStorage_XIX_SoC_XIX_BMC_HV.SP_IF_BMC_HV_12_CRC_XIX_BMC_SafetyDataStorage_XIX_SoC_XIX_BMC_HV <-> outer port SP_IF_BMC_HV_12_CRC_XIX_BMC_HV
    delegate BMC_SafetyDataStorage_XIX_SoC_XIX_BMC_HV.SP_IF_BMC_HV_13_BZ_XIX_BMC_SafetyDataStorage_XIX_SoC_XIX_BMC_HV <-> outer port SP_IF_BMC_HV_13_BZ_XIX_BMC_HV
    delegate BMC_SafetyDataStorage_XIX_SoC_XIX_BMC_HV.SP_IF_BMC_HV_13_CRC_XIX_BMC_SafetyDataStorage_XIX_SoC_XIX_BMC_HV <-> outer port SP_IF_BMC_HV_13_CRC_XIX_BMC_HV
    delegate BMC_SafetyDataStorage_XIX_SoC_XIX_BMC_HV.SP_IF_BMC_Lebensdauer_Trennelemente_XIX_BMC_SafetyDataStorage_XIX_SoC_XIX_BMC_HV <-> outer port SP_IF_BMC_Lebensdauer_Trennelemente_XIX_BMC_HV
    delegate BMC_SafetyDataStorage_XIX_SoC_XIX_BMC_HV.SP_IF_BMC_Sperrung_Ueberspannung_XIX_BMC_SafetyDataStorage_XIX_SoC_XIX_BMC_HV <-> outer port SP_IF_BMC_Sperrung_Ueberspannung_XIX_BMC_HV
    delegate BMC_SafetyDataStorage_XIX_SoC_XIX_BMC_HV.SP_IF_BMC_Sperrung_Uebertemperatur_XIX_BMC_SafetyDataStorage_XIX_SoC_XIX_BMC_HV <-> outer port SP_IF_BMC_Sperrung_Uebertemperatur_XIX_BMC_HV
    delegate BMC_SafetyDataStorage_XIX_SoC_XIX_BMC_HV.SP_IF_BMC_Sperrung_Unterspannung_XIX_BMC_SafetyDataStorage_XIX_SoC_XIX_BMC_HV <-> outer port SP_IF_BMC_Sperrung_Unterspannung_XIX_BMC_HV
    delegate BMC_SafetyDataStorage_XIX_SoC_XIX_BMC_HV.SP_IF_BMC_Status_HV_Spannungssensorik_XIX_BMC_SafetyDataStorage_XIX_SoC_XIX_BMC_HV <-> outer port SP_IF_BMC_Status_HV_Spannungssensorik_XIX_BMC_HV
    delegate BMC_SafetyDataStorage_XIX_SoC_XIX_BMC_HV.SP_IF_BMC_Status_Trennelemente_XIX_BMC_SafetyDataStorage_XIX_SoC_XIX_BMC_HV <-> outer port SP_IF_BMC_Status_Trennelemente_XIX_BMC_HV
    delegate BMC_SafetyDataStorage_XIX_SoC_XIX_BMC_HV.SP_IF_BMC_Ueberspannungszaehler_CMC{01..04}_XIX_BMC_SafetyDataStorage_XIX_SoC_XIX_BMC_HV <-> outer port SP_IF_BMC_Ueberspannungszaehler_CMC{01..04}_XIX_BMC_HV
    delegate BMC_SafetyDataStorage_XIX_SoC_XIX_BMC_HV.SP_IF_BMC_Uebertemperaturzaehler_CMC{01..04}_XIX_BMC_SafetyDataStorage_XIX_SoC_XIX_BMC_HV <-> outer port SP_IF_BMC_Uebertemperaturzaehler_CMC{01..04}_XIX_BMC_HV
    delegate BMC_SafetyDataStorage_XIX_SoC_XIX_BMC_HV.SP_IF_BMC_Unterspannungszaehler_CMC{01..04}_XIX_BMC_SafetyDataStorage_XIX_SoC_XIX_BMC_HV <-> outer port SP_IF_BMC_Unterspannungszaehler_CMC{01..04}_XIX_BMC_HV
    delegate BMC_SafetyDataStorage_XIX_SoC_XIX_BMC_HV.RP_IF_SG_BJB_{10..13}_XIX_BMC_SafetyDataStorage_XIX_SoC_XIX_BMC_HV <-> outer port RP_IF_SG_BJB_{10..13}_XIX_BMC_HV
    delegate HochvoltBatterieManagement_XIX_SoC_XIX_BMC_HV.RP_IF_CHA_ReqPrgBms_XIX_HochvoltBatterieManagement_XIX_SoC_XIX_BMC_HV <-> outer port RP_IF_CHA_ReqPrgBms_XIX_BMC_HV
    delegate HochvoltBatterieManagement_XIX_SoC_XIX_BMC_HV.RP_IF_KST_KL_15_XIX_HochvoltBatterieManagement_XIX_SoC_XIX_BMC_HV <-> outer port RP_IF_KST_KL_15_XIX_BMC_HV
    delegate Infrastructure_Hybrid_01_XIX_network_infrastructure_XIX_BMC_HV.RP_IF_KST_KL_15_XIX_Infrastructure_Hybrid_01_XIX_network_infrastructure_XIX_BMC_HV <-> outer port RP_IF_KST_KL_15_XIX_BMC_HV  # _XIX_ClampControl_XIX_ClampControl_XIX_HCP4_uC1_1_XIX_Infrastructure_Hybrid_01_XIX_network_infrastructure_XIX_BMC_HV_XIX_KST_KL_15
    delegate KS_BMC_HV_XIX_KSGen3_XIX_BMC_HV.RP_IF_SG_KS_Hybrid_01_Challenge_M_XIX_KS_BMC_HV_XIX_KSGen3_XIX_BMC_HV <-> outer port RP_IF_SG_KS_Hybrid_01_Challenge_M_XIX_BMC_HV
    delegate KS_BMC_HV_XIX_KSGen3_XIX_BMC_HV.RP_IF_SG_KS_Hybrid_01_Response_M_XIX_KS_BMC_HV_XIX_KSGen3_XIX_BMC_HV <-> outer port RP_IF_SG_KS_Hybrid_01_Response_M_XIX_BMC_HV
    delegate HochvoltBatterieManagement_XIX_SoC_XIX_BMC_HV.RP_IF_DC_IstLeistung_HV_XIX_HochvoltBatterieManagement_XIX_SoC_XIX_BMC_HV <-> outer port RP_IF_DC_IstLeistung_HV_XIX_BMC_HV
    delegate HVB_Fehlerausgabe_SecondaryOBDECU_XIX_SoC_XIX_BMC_HV.RP_IF_DCDC_NV_Komponentenfehler_72_XIX_HVB_Fehlerausgabe_SecondaryOBDECU_XIX_SoC_XIX_BMC_HV <-> outer port RP_IF_DCDC_NV_Komponentenfehler_72_XIX_BMC_HV  # _XIX_DCDC_SystemControl_XIX_HV_Laden_XIX_DCDC_HV_XIX_HVB_Fehlerausgabe_SecondaryOBDECU_XIX_SoC_XIX_BMC_HV_XIX_DCDC_NV_Komponentenfehler_72
    delegate HVB_Fehlerausgabe_SecondaryOBDECU_XIX_SoC_XIX_BMC_HV.RP_IF_DCDC_NV_Komponentenfehler_3_13_XIX_HVB_Fehlerausgabe_SecondaryOBDECU_XIX_SoC_XIX_BMC_HV <-> outer port RP_IF_DCDC_NV_Komponentenfehler_3_13_XIX_BMC_HV  # _XIX_DCDC_SystemControl_XIX_HV_Laden_XIX_DCDC_HV_XIX_HVB_Fehlerausgabe_SecondaryOBDECU_XIX_SoC_XIX_BMC_HV_XIX_DCDC_NV_Komponentenfehler_3_13
    delegate HVB_Fehlerausgabe_SecondaryOBDECU_XIX_SoC_XIX_BMC_HV.RP_IF_DCDC_NV_Komponentenfehler_40_XIX_HVB_Fehlerausgabe_SecondaryOBDECU_XIX_SoC_XIX_BMC_HV <-> outer port RP_IF_DCDC_NV_Komponentenfehler_40_XIX_BMC_HV  # _XIX_DCDC_SystemControl_XIX_HV_Laden_XIX_DCDC_HV_XIX_HVB_Fehlerausgabe_SecondaryOBDECU_XIX_SoC_XIX_BMC_HV_XIX_DCDC_NV_Komponentenfehler_40
    delegate HVB_Fehlerausgabe_SecondaryOBDECU_XIX_SoC_XIX_BMC_HV.RP_IF_DCDC_NV_Komponentenfehler_VLD_XIX_HVB_Fehlerausgabe_SecondaryOBDECU_XIX_SoC_XIX_BMC_HV <-> outer port RP_IF_DCDC_NV_Komponentenfehler_VLD_XIX_BMC_HV  # _XIX_DCDC_SystemControl_XIX_HV_Laden_XIX_DCDC_HV_XIX_HVB_Fehlerausgabe_SecondaryOBDECU_XIX_SoC_XIX_BMC_HV_XIX_DCDC_NV_Komponentenfehler_VLD
    delegate HVB_Fehlerausgabe_SecondaryOBDECU_XIX_SoC_XIX_BMC_HV.RP_IF_DCDC_NV_Komponentenfehler_34_XIX_HVB_Fehlerausgabe_SecondaryOBDECU_XIX_SoC_XIX_BMC_HV <-> outer port RP_IF_DCDC_NV_Komponentenfehler_34_XIX_BMC_HV  # _XIX_DCDC_SystemControl_XIX_HV_Laden_XIX_DCDC_HV_XIX_HVB_Fehlerausgabe_SecondaryOBDECU_XIX_SoC_XIX_BMC_HV_XIX_DCDC_NV_Komponentenfehler_34
    delegate HVB_Fehlerausgabe_SecondaryOBDECU_XIX_SoC_XIX_BMC_HV.RP_IF_DCDC_NV_Komponentenfehler_65_XIX_HVB_Fehlerausgabe_SecondaryOBDECU_XIX_SoC_XIX_BMC_HV <-> outer port RP_IF_DCDC_NV_Komponentenfehler_65_XIX_BMC_HV  # _XIX_DCDC_SystemControl_XIX_HV_Laden_XIX_DCDC_HV_XIX_HVB_Fehlerausgabe_SecondaryOBDECU_XIX_SoC_XIX_BMC_HV_XIX_DCDC_NV_Komponentenfehler_65
    delegate HVB_Fehlerausgabe_SecondaryOBDECU_XIX_SoC_XIX_BMC_HV.RP_IF_DCDC_NV_Komponentenfehler_73_XIX_HVB_Fehlerausgabe_SecondaryOBDECU_XIX_SoC_XIX_BMC_HV <-> outer port RP_IF_DCDC_NV_Komponentenfehler_73_XIX_BMC_HV  # _XIX_DCDC_SystemControl_XIX_HV_Laden_XIX_DCDC_HV_XIX_HVB_Fehlerausgabe_SecondaryOBDECU_XIX_SoC_XIX_BMC_HV_XIX_DCDC_NV_Komponentenfehler_73
    delegate HVB_Fehlerausgabe_SecondaryOBDECU_XIX_SoC_XIX_BMC_HV.RP_IF_DCDC_NV_Komponentenfehler_3_7_XIX_HVB_Fehlerausgabe_SecondaryOBDECU_XIX_SoC_XIX_BMC_HV <-> outer port RP_IF_DCDC_NV_Komponentenfehler_3_7_XIX_BMC_HV  # _XIX_DCDC_SystemControl_XIX_HV_Laden_XIX_DCDC_HV_XIX_HVB_Fehlerausgabe_SecondaryOBDECU_XIX_SoC_XIX_BMC_HV_XIX_DCDC_NV_Komponentenfehler_3_7
    delegate HVB_Fehlerausgabe_SecondaryOBDECU_XIX_SoC_XIX_BMC_HV.RP_IF_DCDC_NV_Komponentenfehler_36_XIX_HVB_Fehlerausgabe_SecondaryOBDECU_XIX_SoC_XIX_BMC_HV <-> outer port RP_IF_DCDC_NV_Komponentenfehler_36_XIX_BMC_HV  # _XIX_DCDC_SystemControl_XIX_HV_Laden_XIX_DCDC_HV_XIX_HVB_Fehlerausgabe_SecondaryOBDECU_XIX_SoC_XIX_BMC_HV_XIX_DCDC_NV_Komponentenfehler_36
    delegate HVB_Fehlerausgabe_SecondaryOBDECU_XIX_SoC_XIX_BMC_HV.RP_IF_DCDC_NV_Komponentenfehler_3_1_XIX_HVB_Fehlerausgabe_SecondaryOBDECU_XIX_SoC_XIX_BMC_HV <-> outer port RP_IF_DCDC_NV_Komponentenfehler_3_1_XIX_BMC_HV  # _XIX_DCDC_SystemControl_XIX_HV_Laden_XIX_DCDC_HV_XIX_HVB_Fehlerausgabe_SecondaryOBDECU_XIX_SoC_XIX_BMC_HV_XIX_DCDC_NV_Komponentenfehler_3_1
    delegate HVB_Fehlerausgabe_SecondaryOBDECU_XIX_SoC_XIX_BMC_HV.RP_IF_DCDC_NV_Komponentenfehler_3_12_XIX_HVB_Fehlerausgabe_SecondaryOBDECU_XIX_SoC_XIX_BMC_HV <-> outer port RP_IF_DCDC_NV_Komponentenfehler_3_12_XIX_BMC_HV  # _XIX_DCDC_SystemControl_XIX_HV_Laden_XIX_DCDC_HV_XIX_HVB_Fehlerausgabe_SecondaryOBDECU_XIX_SoC_XIX_BMC_HV_XIX_DCDC_NV_Komponentenfehler_3_12
    delegate HVB_Fehlerausgabe_SecondaryOBDECU_XIX_SoC_XIX_BMC_HV.RP_IF_DCDC_NV_Komponentenfehler_22_XIX_HVB_Fehlerausgabe_SecondaryOBDECU_XIX_SoC_XIX_BMC_HV <-> outer port RP_IF_DCDC_NV_Komponentenfehler_22_XIX_BMC_HV  # _XIX_DCDC_SystemControl_XIX_HV_Laden_XIX_DCDC_HV_XIX_HVB_Fehlerausgabe_SecondaryOBDECU_XIX_SoC_XIX_BMC_HV_XIX_DCDC_NV_Komponentenfehler_22
    delegate HVB_Fehlerausgabe_SecondaryOBDECU_XIX_SoC_XIX_BMC_HV.RP_IF_DCDC_NV_Komponentenfehler_32_XIX_HVB_Fehlerausgabe_SecondaryOBDECU_XIX_SoC_XIX_BMC_HV <-> outer port RP_IF_DCDC_NV_Komponentenfehler_32_XIX_BMC_HV  # _XIX_DCDC_SystemControl_XIX_HV_Laden_XIX_DCDC_HV_XIX_HVB_Fehlerausgabe_SecondaryOBDECU_XIX_SoC_XIX_BMC_HV_XIX_DCDC_NV_Komponentenfehler_32
    delegate HVB_Fehlerausgabe_SecondaryOBDECU_XIX_SoC_XIX_BMC_HV.RP_IF_DCDC_NV_Komponentenfehler_47_XIX_HVB_Fehlerausgabe_SecondaryOBDECU_XIX_SoC_XIX_BMC_HV <-> outer port RP_IF_DCDC_NV_Komponentenfehler_47_XIX_BMC_HV  # _XIX_DCDC_SystemControl_XIX_HV_Laden_XIX_DCDC_HV_XIX_HVB_Fehlerausgabe_SecondaryOBDECU_XIX_SoC_XIX_BMC_HV_XIX_DCDC_NV_Komponentenfehler_47
    delegate HVB_Fehlerausgabe_SecondaryOBDECU_XIX_SoC_XIX_BMC_HV.RP_IF_DCDC_NV_Komponentenfehler_3_16_XIX_HVB_Fehlerausgabe_SecondaryOBDECU_XIX_SoC_XIX_BMC_HV <-> outer port RP_IF_DCDC_NV_Komponentenfehler_3_16_XIX_BMC_HV  # _XIX_DCDC_SystemControl_XIX_HV_Laden_XIX_DCDC_HV_XIX_HVB_Fehlerausgabe_SecondaryOBDECU_XIX_SoC_XIX_BMC_HV_XIX_DCDC_NV_Komponentenfehler_3_16
    delegate HVB_Fehlerausgabe_SecondaryOBDECU_XIX_SoC_XIX_BMC_HV.RP_IF_DCDC_NV_Komponentenfehler_38_XIX_HVB_Fehlerausgabe_SecondaryOBDECU_XIX_SoC_XIX_BMC_HV <-> outer port RP_IF_DCDC_NV_Komponentenfehler_38_XIX_BMC_HV  # _XIX_DCDC_SystemControl_XIX_HV_Laden_XIX_DCDC_HV_XIX_HVB_Fehlerausgabe_SecondaryOBDECU_XIX_SoC_XIX_BMC_HV_XIX_DCDC_NV_Komponentenfehler_38
    delegate HVB_Fehlerausgabe_SecondaryOBDECU_XIX_SoC_XIX_BMC_HV.RP_IF_DCDC_NV_Komponentenfehler_3_10_XIX_HVB_Fehlerausgabe_SecondaryOBDECU_XIX_SoC_XIX_BMC_HV <-> outer port RP_IF_DCDC_NV_Komponentenfehler_3_10_XIX_BMC_HV  # _XIX_DCDC_SystemControl_XIX_HV_Laden_XIX_DCDC_HV_XIX_HVB_Fehlerausgabe_SecondaryOBDECU_XIX_SoC_XIX_BMC_HV_XIX_DCDC_NV_Komponentenfehler_3_10
    delegate HVB_Fehlerausgabe_SecondaryOBDECU_XIX_SoC_XIX_BMC_HV.RP_IF_DCDC_NV_Komponentenfehler_55_XIX_HVB_Fehlerausgabe_SecondaryOBDECU_XIX_SoC_XIX_BMC_HV <-> outer port RP_IF_DCDC_NV_Komponentenfehler_55_XIX_BMC_HV  # _XIX_DCDC_SystemControl_XIX_HV_Laden_XIX_DCDC_HV_XIX_HVB_Fehlerausgabe_SecondaryOBDECU_XIX_SoC_XIX_BMC_HV_XIX_DCDC_NV_Komponentenfehler_55
    delegate HVB_Fehlerausgabe_SecondaryOBDECU_XIX_SoC_XIX_BMC_HV.RP_IF_DCDC_NV_Komponentenfehler_76_XIX_HVB_Fehlerausgabe_SecondaryOBDECU_XIX_SoC_XIX_BMC_HV <-> outer port RP_IF_DCDC_NV_Komponentenfehler_76_XIX_BMC_HV  # _XIX_DCDC_SystemControl_XIX_HV_Laden_XIX_DCDC_HV_XIX_HVB_Fehlerausgabe_SecondaryOBDECU_XIX_SoC_XIX_BMC_HV_XIX_DCDC_NV_Komponentenfehler_76
    delegate HVB_Fehlerausgabe_SecondaryOBDECU_XIX_SoC_XIX_BMC_HV.RP_IF_DCDC_NV_Komponentenfehler_43_XIX_HVB_Fehlerausgabe_SecondaryOBDECU_XIX_SoC_XIX_BMC_HV <-> outer port RP_IF_DCDC_NV_Komponentenfehler_43_XIX_BMC_HV  # _XIX_DCDC_SystemControl_XIX_HV_Laden_XIX_DCDC_HV_XIX_HVB_Fehlerausgabe_SecondaryOBDECU_XIX_SoC_XIX_BMC_HV_XIX_DCDC_NV_Komponentenfehler_43
    delegate HVB_Fehlerausgabe_SecondaryOBDECU_XIX_SoC_XIX_BMC_HV.RP_IF_DCDC_NV_Komponentenfehler_26_XIX_HVB_Fehlerausgabe_SecondaryOBDECU_XIX_SoC_XIX_BMC_HV <-> outer port RP_IF_DCDC_NV_Komponentenfehler_26_XIX_BMC_HV  # _XIX_DCDC_SystemControl_XIX_HV_Laden_XIX_DCDC_HV_XIX_HVB_Fehlerausgabe_SecondaryOBDECU_XIX_SoC_XIX_BMC_HV_XIX_DCDC_NV_Komponentenfehler_26
    delegate HVB_Fehlerausgabe_SecondaryOBDECU_XIX_SoC_XIX_BMC_HV.RP_IF_DCDC_NV_Komponentenfehler_05_XIX_HVB_Fehlerausgabe_SecondaryOBDECU_XIX_SoC_XIX_BMC_HV <-> outer port RP_IF_DCDC_NV_Komponentenfehler_05_XIX_BMC_HV  # _XIX_DCDC_SystemControl_XIX_HV_Laden_XIX_DCDC_HV_XIX_HVB_Fehlerausgabe_SecondaryOBDECU_XIX_SoC_XIX_BMC_HV_XIX_DCDC_NV_Komponentenfehler_05
    delegate HVB_Fehlerausgabe_SecondaryOBDECU_XIX_SoC_XIX_BMC_HV.RP_IF_DCDC_NV_Komponentenfehler_56_XIX_HVB_Fehlerausgabe_SecondaryOBDECU_XIX_SoC_XIX_BMC_HV <-> outer port RP_IF_DCDC_NV_Komponentenfehler_56_XIX_BMC_HV  # _XIX_DCDC_SystemControl_XIX_HV_Laden_XIX_DCDC_HV_XIX_HVB_Fehlerausgabe_SecondaryOBDECU_XIX_SoC_XIX_BMC_HV_XIX_DCDC_NV_Komponentenfehler_56
    delegate HVB_Fehlerausgabe_SecondaryOBDECU_XIX_SoC_XIX_BMC_HV.RP_IF_DCDC_NV_Komponentenfehler_11_XIX_HVB_Fehlerausgabe_SecondaryOBDECU_XIX_SoC_XIX_BMC_HV <-> outer port RP_IF_DCDC_NV_Komponentenfehler_11_XIX_BMC_HV  # _XIX_DCDC_SystemControl_XIX_HV_Laden_XIX_DCDC_HV_XIX_HVB_Fehlerausgabe_SecondaryOBDECU_XIX_SoC_XIX_BMC_HV_XIX_DCDC_NV_Komponentenfehler_11
    delegate HVB_Fehlerausgabe_SecondaryOBDECU_XIX_SoC_XIX_BMC_HV.RP_IF_DCDC_NV_Komponentenfehler_14_XIX_HVB_Fehlerausgabe_SecondaryOBDECU_XIX_SoC_XIX_BMC_HV <-> outer port RP_IF_DCDC_NV_Komponentenfehler_14_XIX_BMC_HV  # _XIX_DCDC_SystemControl_XIX_HV_Laden_XIX_DCDC_HV_XIX_HVB_Fehlerausgabe_SecondaryOBDECU_XIX_SoC_XIX_BMC_HV_XIX_DCDC_NV_Komponentenfehler_14
    delegate HVB_Fehlerausgabe_SecondaryOBDECU_XIX_SoC_XIX_BMC_HV.RP_IF_DCDC_NV_Komponentenfehler_77_XIX_HVB_Fehlerausgabe_SecondaryOBDECU_XIX_SoC_XIX_BMC_HV <-> outer port RP_IF_DCDC_NV_Komponentenfehler_77_XIX_BMC_HV  # _XIX_DCDC_SystemControl_XIX_HV_Laden_XIX_DCDC_HV_XIX_HVB_Fehlerausgabe_SecondaryOBDECU_XIX_SoC_XIX_BMC_HV_XIX_DCDC_NV_Komponentenfehler_77
    delegate HVB_Fehlerausgabe_SecondaryOBDECU_XIX_SoC_XIX_BMC_HV.RP_IF_DCDC_NV_Komponentenfehler_18_XIX_HVB_Fehlerausgabe_SecondaryOBDECU_XIX_SoC_XIX_BMC_HV <-> outer port RP_IF_DCDC_NV_Komponentenfehler_18_XIX_BMC_HV  # _XIX_DCDC_SystemControl_XIX_HV_Laden_XIX_DCDC_HV_XIX_HVB_Fehlerausgabe_SecondaryOBDECU_XIX_SoC_XIX_BMC_HV_XIX_DCDC_NV_Komponentenfehler_18
    delegate HVB_Fehlerausgabe_SecondaryOBDECU_XIX_SoC_XIX_BMC_HV.RP_IF_DCDC_NV_Komponentenfehler_59_XIX_HVB_Fehlerausgabe_SecondaryOBDECU_XIX_SoC_XIX_BMC_HV <-> outer port RP_IF_DCDC_NV_Komponentenfehler_59_XIX_BMC_HV  # _XIX_DCDC_SystemControl_XIX_HV_Laden_XIX_DCDC_HV_XIX_HVB_Fehlerausgabe_SecondaryOBDECU_XIX_SoC_XIX_BMC_HV_XIX_DCDC_NV_Komponentenfehler_59
    delegate HVB_Fehlerausgabe_SecondaryOBDECU_XIX_SoC_XIX_BMC_HV.RP_IF_DCDC_NV_Komponentenfehler_45_XIX_HVB_Fehlerausgabe_SecondaryOBDECU_XIX_SoC_XIX_BMC_HV <-> outer port RP_IF_DCDC_NV_Komponentenfehler_45_XIX_BMC_HV  # _XIX_DCDC_SystemControl_XIX_HV_Laden_XIX_DCDC_HV_XIX_HVB_Fehlerausgabe_SecondaryOBDECU_XIX_SoC_XIX_BMC_HV_XIX_DCDC_NV_Komponentenfehler_45
    delegate HVB_Fehlerausgabe_SecondaryOBDECU_XIX_SoC_XIX_BMC_HV.RP_IF_DCDC_NV_Komponentenfehler_30_XIX_HVB_Fehlerausgabe_SecondaryOBDECU_XIX_SoC_XIX_BMC_HV <-> outer port RP_IF_DCDC_NV_Komponentenfehler_30_XIX_BMC_HV  # _XIX_DCDC_SystemControl_XIX_HV_Laden_XIX_DCDC_HV_XIX_HVB_Fehlerausgabe_SecondaryOBDECU_XIX_SoC_XIX_BMC_HV_XIX_DCDC_NV_Komponentenfehler_30
    delegate HVB_Fehlerausgabe_SecondaryOBDECU_XIX_SoC_XIX_BMC_HV.RP_IF_DCDC_NV_Komponentenfehler_04_XIX_HVB_Fehlerausgabe_SecondaryOBDECU_XIX_SoC_XIX_BMC_HV <-> outer port RP_IF_DCDC_NV_Komponentenfehler_04_XIX_BMC_HV  # _XIX_DCDC_SystemControl_XIX_HV_Laden_XIX_DCDC_HV_XIX_HVB_Fehlerausgabe_SecondaryOBDECU_XIX_SoC_XIX_BMC_HV_XIX_DCDC_NV_Komponentenfehler_04
    delegate HVB_Fehlerausgabe_SecondaryOBDECU_XIX_SoC_XIX_BMC_HV.RP_IF_DCDC_NV_Komponentenfehler_09_XIX_HVB_Fehlerausgabe_SecondaryOBDECU_XIX_SoC_XIX_BMC_HV <-> outer port RP_IF_DCDC_NV_Komponentenfehler_09_XIX_BMC_HV  # _XIX_DCDC_SystemControl_XIX_HV_Laden_XIX_DCDC_HV_XIX_HVB_Fehlerausgabe_SecondaryOBDECU_XIX_SoC_XIX_BMC_HV_XIX_DCDC_NV_Komponentenfehler_09
    delegate HVB_Fehlerausgabe_SecondaryOBDECU_XIX_SoC_XIX_BMC_HV.RP_IF_DCDC_NV_Komponentenfehler_3_8_XIX_HVB_Fehlerausgabe_SecondaryOBDECU_XIX_SoC_XIX_BMC_HV <-> outer port RP_IF_DCDC_NV_Komponentenfehler_3_8_XIX_BMC_HV  # _XIX_DCDC_SystemControl_XIX_HV_Laden_XIX_DCDC_HV_XIX_HVB_Fehlerausgabe_SecondaryOBDECU_XIX_SoC_XIX_BMC_HV_XIX_DCDC_NV_Komponentenfehler_3_8
    delegate HVB_Fehlerausgabe_SecondaryOBDECU_XIX_SoC_XIX_BMC_HV.RP_IF_DCDC_NV_Komponentenfehler_02_XIX_HVB_Fehlerausgabe_SecondaryOBDECU_XIX_SoC_XIX_BMC_HV <-> outer port RP_IF_DCDC_NV_Komponentenfehler_02_XIX_BMC_HV  # _XIX_DCDC_SystemControl_XIX_HV_Laden_XIX_DCDC_HV_XIX_HVB_Fehlerausgabe_SecondaryOBDECU_XIX_SoC_XIX_BMC_HV_XIX_DCDC_NV_Komponentenfehler_02
    delegate HVB_Fehlerausgabe_SecondaryOBDECU_XIX_SoC_XIX_BMC_HV.RP_IF_DCDC_NV_Komponentenfehler_54_XIX_HVB_Fehlerausgabe_SecondaryOBDECU_XIX_SoC_XIX_BMC_HV <-> outer port RP_IF_DCDC_NV_Komponentenfehler_54_XIX_BMC_HV  # _XIX_DCDC_SystemControl_XIX_HV_Laden_XIX_DCDC_HV_XIX_HVB_Fehlerausgabe_SecondaryOBDECU_XIX_SoC_XIX_BMC_HV_XIX_DCDC_NV_Komponentenfehler_54
    delegate HVB_Fehlerausgabe_SecondaryOBDECU_XIX_SoC_XIX_BMC_HV.RP_IF_DCDC_NV_Komponentenfehler_53_XIX_HVB_Fehlerausgabe_SecondaryOBDECU_XIX_SoC_XIX_BMC_HV <-> outer port RP_IF_DCDC_NV_Komponentenfehler_53_XIX_BMC_HV  # _XIX_DCDC_SystemControl_XIX_HV_Laden_XIX_DCDC_HV_XIX_HVB_Fehlerausgabe_SecondaryOBDECU_XIX_SoC_XIX_BMC_HV_XIX_DCDC_NV_Komponentenfehler_53
    delegate HVB_Fehlerausgabe_SecondaryOBDECU_XIX_SoC_XIX_BMC_HV.RP_IF_DCDC_NV_Komponentenfehler_66_XIX_HVB_Fehlerausgabe_SecondaryOBDECU_XIX_SoC_XIX_BMC_HV <-> outer port RP_IF_DCDC_NV_Komponentenfehler_66_XIX_BMC_HV  # _XIX_DCDC_SystemControl_XIX_HV_Laden_XIX_DCDC_HV_XIX_HVB_Fehlerausgabe_SecondaryOBDECU_XIX_SoC_XIX_BMC_HV_XIX_DCDC_NV_Komponentenfehler_66
    delegate HVB_Fehlerausgabe_SecondaryOBDECU_XIX_SoC_XIX_BMC_HV.RP_IF_DCDC_NV_Komponentenfehler_68_XIX_HVB_Fehlerausgabe_SecondaryOBDECU_XIX_SoC_XIX_BMC_HV <-> outer port RP_IF_DCDC_NV_Komponentenfehler_68_XIX_BMC_HV  # _XIX_DCDC_SystemControl_XIX_HV_Laden_XIX_DCDC_HV_XIX_HVB_Fehlerausgabe_SecondaryOBDECU_XIX_SoC_XIX_BMC_HV_XIX_DCDC_NV_Komponentenfehler_68
    delegate HVB_Fehlerausgabe_SecondaryOBDECU_XIX_SoC_XIX_BMC_HV.RP_IF_DCDC_NV_Komponentenfehler_51_XIX_HVB_Fehlerausgabe_SecondaryOBDECU_XIX_SoC_XIX_BMC_HV <-> outer port RP_IF_DCDC_NV_Komponentenfehler_51_XIX_BMC_HV  # _XIX_DCDC_SystemControl_XIX_HV_Laden_XIX_DCDC_HV_XIX_HVB_Fehlerausgabe_SecondaryOBDECU_XIX_SoC_XIX_BMC_HV_XIX_DCDC_NV_Komponentenfehler_51
    delegate HVB_Fehlerausgabe_SecondaryOBDECU_XIX_SoC_XIX_BMC_HV.RP_IF_DCDC_NV_Komponentenfehler_35_XIX_HVB_Fehlerausgabe_SecondaryOBDECU_XIX_SoC_XIX_BMC_HV <-> outer port RP_IF_DCDC_NV_Komponentenfehler_35_XIX_BMC_HV  # _XIX_DCDC_SystemControl_XIX_HV_Laden_XIX_DCDC_HV_XIX_HVB_Fehlerausgabe_SecondaryOBDECU_XIX_SoC_XIX_BMC_HV_XIX_DCDC_NV_Komponentenfehler_35
    delegate HVB_Fehlerausgabe_SecondaryOBDECU_XIX_SoC_XIX_BMC_HV.RP_IF_DCDC_NV_Komponentenfehler_31_XIX_HVB_Fehlerausgabe_SecondaryOBDECU_XIX_SoC_XIX_BMC_HV <-> outer port RP_IF_DCDC_NV_Komponentenfehler_31_XIX_BMC_HV  # _XIX_DCDC_SystemControl_XIX_HV_Laden_XIX_DCDC_HV_XIX_HVB_Fehlerausgabe_SecondaryOBDECU_XIX_SoC_XIX_BMC_HV_XIX_DCDC_NV_Komponentenfehler_31
    delegate HVB_Fehlerausgabe_SecondaryOBDECU_XIX_SoC_XIX_BMC_HV.RP_IF_DCDC_NV_Komponentenfehler_48_XIX_HVB_Fehlerausgabe_SecondaryOBDECU_XIX_SoC_XIX_BMC_HV <-> outer port RP_IF_DCDC_NV_Komponentenfehler_48_XIX_BMC_HV  # _XIX_DCDC_SystemControl_XIX_HV_Laden_XIX_DCDC_HV_XIX_HVB_Fehlerausgabe_SecondaryOBDECU_XIX_SoC_XIX_BMC_HV_XIX_DCDC_NV_Komponentenfehler_48
    delegate HVB_Fehlerausgabe_SecondaryOBDECU_XIX_SoC_XIX_BMC_HV.RP_IF_DCDC_NV_Komponentenfehler_07_XIX_HVB_Fehlerausgabe_SecondaryOBDECU_XIX_SoC_XIX_BMC_HV <-> outer port RP_IF_DCDC_NV_Komponentenfehler_07_XIX_BMC_HV  # _XIX_DCDC_SystemControl_XIX_HV_Laden_XIX_DCDC_HV_XIX_HVB_Fehlerausgabe_SecondaryOBDECU_XIX_SoC_XIX_BMC_HV_XIX_DCDC_NV_Komponentenfehler_07
    delegate HVB_Fehlerausgabe_SecondaryOBDECU_XIX_SoC_XIX_BMC_HV.RP_IF_DCDC_NV_Komponentenfehler_67_XIX_HVB_Fehlerausgabe_SecondaryOBDECU_XIX_SoC_XIX_BMC_HV <-> outer port RP_IF_DCDC_NV_Komponentenfehler_67_XIX_BMC_HV  # _XIX_DCDC_SystemControl_XIX_HV_Laden_XIX_DCDC_HV_XIX_HVB_Fehlerausgabe_SecondaryOBDECU_XIX_SoC_XIX_BMC_HV_XIX_DCDC_NV_Komponentenfehler_67
    delegate HVB_Fehlerausgabe_SecondaryOBDECU_XIX_SoC_XIX_BMC_HV.RP_IF_DCDC_NV_Komponentenfehler_08_XIX_HVB_Fehlerausgabe_SecondaryOBDECU_XIX_SoC_XIX_BMC_HV <-> outer port RP_IF_DCDC_NV_Komponentenfehler_08_XIX_BMC_HV  # _XIX_DCDC_SystemControl_XIX_HV_Laden_XIX_DCDC_HV_XIX_HVB_Fehlerausgabe_SecondaryOBDECU_XIX_SoC_XIX_BMC_HV_XIX_DCDC_NV_Komponentenfehler_08
    delegate HVB_Fehlerausgabe_SecondaryOBDECU_XIX_SoC_XIX_BMC_HV.RP_IF_DCDC_NV_Komponentenfehler_27_XIX_HVB_Fehlerausgabe_SecondaryOBDECU_XIX_SoC_XIX_BMC_HV <-> outer port RP_IF_DCDC_NV_Komponentenfehler_27_XIX_BMC_HV  # _XIX_DCDC_SystemControl_XIX_HV_Laden_XIX_DCDC_HV_XIX_HVB_Fehlerausgabe_SecondaryOBDECU_XIX_SoC_XIX_BMC_HV_XIX_DCDC_NV_Komponentenfehler_27
    delegate HVB_Fehlerausgabe_SecondaryOBDECU_XIX_SoC_XIX_BMC_HV.RP_IF_DCDC_NV_Komponentenfehler_69_XIX_HVB_Fehlerausgabe_SecondaryOBDECU_XIX_SoC_XIX_BMC_HV <-> outer port RP_IF_DCDC_NV_Komponentenfehler_69_XIX_BMC_HV  # _XIX_DCDC_SystemControl_XIX_HV_Laden_XIX_DCDC_HV_XIX_HVB_Fehlerausgabe_SecondaryOBDECU_XIX_SoC_XIX_BMC_HV_XIX_DCDC_NV_Komponentenfehler_69
    delegate HVB_Fehlerausgabe_SecondaryOBDECU_XIX_SoC_XIX_BMC_HV.RP_IF_DCDC_NV_Komponentenfehler_13_XIX_HVB_Fehlerausgabe_SecondaryOBDECU_XIX_SoC_XIX_BMC_HV <-> outer port RP_IF_DCDC_NV_Komponentenfehler_13_XIX_BMC_HV  # _XIX_DCDC_SystemControl_XIX_HV_Laden_XIX_DCDC_HV_XIX_HVB_Fehlerausgabe_SecondaryOBDECU_XIX_SoC_XIX_BMC_HV_XIX_DCDC_NV_Komponentenfehler_13
    delegate HVB_Fehlerausgabe_SecondaryOBDECU_XIX_SoC_XIX_BMC_HV.RP_IF_DCDC_NV_Komponentenfehler_20_XIX_HVB_Fehlerausgabe_SecondaryOBDECU_XIX_SoC_XIX_BMC_HV <-> outer port RP_IF_DCDC_NV_Komponentenfehler_20_XIX_BMC_HV  # _XIX_DCDC_SystemControl_XIX_HV_Laden_XIX_DCDC_HV_XIX_HVB_Fehlerausgabe_SecondaryOBDECU_XIX_SoC_XIX_BMC_HV_XIX_DCDC_NV_Komponentenfehler_20
    delegate HVB_Fehlerausgabe_SecondaryOBDECU_XIX_SoC_XIX_BMC_HV.RP_IF_DCDC_NV_Komponentenfehler_15_XIX_HVB_Fehlerausgabe_SecondaryOBDECU_XIX_SoC_XIX_BMC_HV <-> outer port RP_IF_DCDC_NV_Komponentenfehler_15_XIX_BMC_HV  # _XIX_DCDC_SystemControl_XIX_HV_Laden_XIX_DCDC_HV_XIX_HVB_Fehlerausgabe_SecondaryOBDECU_XIX_SoC_XIX_BMC_HV_XIX_DCDC_NV_Komponentenfehler_15
    delegate HVB_Fehlerausgabe_SecondaryOBDECU_XIX_SoC_XIX_BMC_HV.RP_IF_DCDC_NV_Komponentenfehler_44_XIX_HVB_Fehlerausgabe_SecondaryOBDECU_XIX_SoC_XIX_BMC_HV <-> outer port RP_IF_DCDC_NV_Komponentenfehler_44_XIX_BMC_HV  # _XIX_DCDC_SystemControl_XIX_HV_Laden_XIX_DCDC_HV_XIX_HVB_Fehlerausgabe_SecondaryOBDECU_XIX_SoC_XIX_BMC_HV_XIX_DCDC_NV_Komponentenfehler_44
    delegate HVB_Fehlerausgabe_SecondaryOBDECU_XIX_SoC_XIX_BMC_HV.RP_IF_DCDC_NV_Komponentenfehler_03_XIX_HVB_Fehlerausgabe_SecondaryOBDECU_XIX_SoC_XIX_BMC_HV <-> outer port RP_IF_DCDC_NV_Komponentenfehler_03_XIX_BMC_HV  # _XIX_DCDC_SystemControl_XIX_HV_Laden_XIX_DCDC_HV_XIX_HVB_Fehlerausgabe_SecondaryOBDECU_XIX_SoC_XIX_BMC_HV_XIX_DCDC_NV_Komponentenfehler_03
    delegate HVB_Fehlerausgabe_SecondaryOBDECU_XIX_SoC_XIX_BMC_HV.RP_IF_DCDC_NV_Komponentenfehler_3_5_XIX_HVB_Fehlerausgabe_SecondaryOBDECU_XIX_SoC_XIX_BMC_HV <-> outer port RP_IF_DCDC_NV_Komponentenfehler_3_5_XIX_BMC_HV  # _XIX_DCDC_SystemControl_XIX_HV_Laden_XIX_DCDC_HV_XIX_HVB_Fehlerausgabe_SecondaryOBDECU_XIX_SoC_XIX_BMC_HV_XIX_DCDC_NV_Komponentenfehler_3_5
    delegate HVB_Fehlerausgabe_SecondaryOBDECU_XIX_SoC_XIX_BMC_HV.RP_IF_DCDC_NV_Komponentenfehler_79_XIX_HVB_Fehlerausgabe_SecondaryOBDECU_XIX_SoC_XIX_BMC_HV <-> outer port RP_IF_DCDC_NV_Komponentenfehler_79_XIX_BMC_HV  # _XIX_DCDC_SystemControl_XIX_HV_Laden_XIX_DCDC_HV_XIX_HVB_Fehlerausgabe_SecondaryOBDECU_XIX_SoC_XIX_BMC_HV_XIX_DCDC_NV_Komponentenfehler_79
    delegate HVB_Fehlerausgabe_SecondaryOBDECU_XIX_SoC_XIX_BMC_HV.RP_IF_DCDC_NV_Komponentenfehler_52_XIX_HVB_Fehlerausgabe_SecondaryOBDECU_XIX_SoC_XIX_BMC_HV <-> outer port RP_IF_DCDC_NV_Komponentenfehler_52_XIX_BMC_HV  # _XIX_DCDC_SystemControl_XIX_HV_Laden_XIX_DCDC_HV_XIX_HVB_Fehlerausgabe_SecondaryOBDECU_XIX_SoC_XIX_BMC_HV_XIX_DCDC_NV_Komponentenfehler_52
    delegate HVB_Fehlerausgabe_SecondaryOBDECU_XIX_SoC_XIX_BMC_HV.RP_IF_DCDC_NV_Komponentenfehler_3_14_XIX_HVB_Fehlerausgabe_SecondaryOBDECU_XIX_SoC_XIX_BMC_HV <-> outer port RP_IF_DCDC_NV_Komponentenfehler_3_14_XIX_BMC_HV  # _XIX_DCDC_SystemControl_XIX_HV_Laden_XIX_DCDC_HV_XIX_HVB_Fehlerausgabe_SecondaryOBDECU_XIX_SoC_XIX_BMC_HV_XIX_DCDC_NV_Komponentenfehler_3_14
    delegate HVB_Fehlerausgabe_SecondaryOBDECU_XIX_SoC_XIX_BMC_HV.RP_IF_DCDC_NV_Komponentenfehler_3_3_XIX_HVB_Fehlerausgabe_SecondaryOBDECU_XIX_SoC_XIX_BMC_HV <-> outer port RP_IF_DCDC_NV_Komponentenfehler_3_3_XIX_BMC_HV  # _XIX_DCDC_SystemControl_XIX_HV_Laden_XIX_DCDC_HV_XIX_HVB_Fehlerausgabe_SecondaryOBDECU_XIX_SoC_XIX_BMC_HV_XIX_DCDC_NV_Komponentenfehler_3_3
    delegate HVB_Fehlerausgabe_SecondaryOBDECU_XIX_SoC_XIX_BMC_HV.RP_IF_DCDC_NV_Komponentenfehler_58_XIX_HVB_Fehlerausgabe_SecondaryOBDECU_XIX_SoC_XIX_BMC_HV <-> outer port RP_IF_DCDC_NV_Komponentenfehler_58_XIX_BMC_HV  # _XIX_DCDC_SystemControl_XIX_HV_Laden_XIX_DCDC_HV_XIX_HVB_Fehlerausgabe_SecondaryOBDECU_XIX_SoC_XIX_BMC_HV_XIX_DCDC_NV_Komponentenfehler_58
    delegate HVB_Fehlerausgabe_SecondaryOBDECU_XIX_SoC_XIX_BMC_HV.RP_IF_DCDC_NV_Komponentenfehler_25_XIX_HVB_Fehlerausgabe_SecondaryOBDECU_XIX_SoC_XIX_BMC_HV <-> outer port RP_IF_DCDC_NV_Komponentenfehler_25_XIX_BMC_HV  # _XIX_DCDC_SystemControl_XIX_HV_Laden_XIX_DCDC_HV_XIX_HVB_Fehlerausgabe_SecondaryOBDECU_XIX_SoC_XIX_BMC_HV_XIX_DCDC_NV_Komponentenfehler_25
    delegate HVB_Fehlerausgabe_SecondaryOBDECU_XIX_SoC_XIX_BMC_HV.RP_IF_DCDC_NV_Komponentenfehler_33_XIX_HVB_Fehlerausgabe_SecondaryOBDECU_XIX_SoC_XIX_BMC_HV <-> outer port RP_IF_DCDC_NV_Komponentenfehler_33_XIX_BMC_HV  # _XIX_DCDC_SystemControl_XIX_HV_Laden_XIX_DCDC_HV_XIX_HVB_Fehlerausgabe_SecondaryOBDECU_XIX_SoC_XIX_BMC_HV_XIX_DCDC_NV_Komponentenfehler_33
    delegate HVB_Fehlerausgabe_SecondaryOBDECU_XIX_SoC_XIX_BMC_HV.RP_IF_DCDC_NV_Komponentenfehler_16_XIX_HVB_Fehlerausgabe_SecondaryOBDECU_XIX_SoC_XIX_BMC_HV <-> outer port RP_IF_DCDC_NV_Komponentenfehler_16_XIX_BMC_HV  # _XIX_DCDC_SystemControl_XIX_HV_Laden_XIX_DCDC_HV_XIX_HVB_Fehlerausgabe_SecondaryOBDECU_XIX_SoC_XIX_BMC_HV_XIX_DCDC_NV_Komponentenfehler_16
    delegate HVB_Fehlerausgabe_SecondaryOBDECU_XIX_SoC_XIX_BMC_HV.RP_IF_DCDC_NV_Komponentenfehler_74_XIX_HVB_Fehlerausgabe_SecondaryOBDECU_XIX_SoC_XIX_BMC_HV <-> outer port RP_IF_DCDC_NV_Komponentenfehler_74_XIX_BMC_HV  # _XIX_DCDC_SystemControl_XIX_HV_Laden_XIX_DCDC_HV_XIX_HVB_Fehlerausgabe_SecondaryOBDECU_XIX_SoC_XIX_BMC_HV_XIX_DCDC_NV_Komponentenfehler_74
    delegate HVB_Fehlerausgabe_SecondaryOBDECU_XIX_SoC_XIX_BMC_HV.RP_IF_DCDC_NV_Komponentenfehler_46_XIX_HVB_Fehlerausgabe_SecondaryOBDECU_XIX_SoC_XIX_BMC_HV <-> outer port RP_IF_DCDC_NV_Komponentenfehler_46_XIX_BMC_HV  # _XIX_DCDC_SystemControl_XIX_HV_Laden_XIX_DCDC_HV_XIX_HVB_Fehlerausgabe_SecondaryOBDECU_XIX_SoC_XIX_BMC_HV_XIX_DCDC_NV_Komponentenfehler_46
    delegate HVB_Fehlerausgabe_SecondaryOBDECU_XIX_SoC_XIX_BMC_HV.RP_IF_DCDC_NV_Komponentenfehler_50_XIX_HVB_Fehlerausgabe_SecondaryOBDECU_XIX_SoC_XIX_BMC_HV <-> outer port RP_IF_DCDC_NV_Komponentenfehler_50_XIX_BMC_HV  # _XIX_DCDC_SystemControl_XIX_HV_Laden_XIX_DCDC_HV_XIX_HVB_Fehlerausgabe_SecondaryOBDECU_XIX_SoC_XIX_BMC_HV_XIX_DCDC_NV_Komponentenfehler_50
    delegate HVB_Fehlerausgabe_SecondaryOBDECU_XIX_SoC_XIX_BMC_HV.RP_IF_DCDC_NV_Komponentenfehler_3_6_XIX_HVB_Fehlerausgabe_SecondaryOBDECU_XIX_SoC_XIX_BMC_HV <-> outer port RP_IF_DCDC_NV_Komponentenfehler_3_6_XIX_BMC_HV  # _XIX_DCDC_SystemControl_XIX_HV_Laden_XIX_DCDC_HV_XIX_HVB_Fehlerausgabe_SecondaryOBDECU_XIX_SoC_XIX_BMC_HV_XIX_DCDC_NV_Komponentenfehler_3_6
    delegate HVB_Fehlerausgabe_SecondaryOBDECU_XIX_SoC_XIX_BMC_HV.RP_IF_DCDC_NV_Komponentenfehler_3_2_XIX_HVB_Fehlerausgabe_SecondaryOBDECU_XIX_SoC_XIX_BMC_HV <-> outer port RP_IF_DCDC_NV_Komponentenfehler_3_2_XIX_BMC_HV  # _XIX_DCDC_SystemControl_XIX_HV_Laden_XIX_DCDC_HV_XIX_HVB_Fehlerausgabe_SecondaryOBDECU_XIX_SoC_XIX_BMC_HV_XIX_DCDC_NV_Komponentenfehler_3_2
    delegate HVB_Fehlerausgabe_SecondaryOBDECU_XIX_SoC_XIX_BMC_HV.RP_IF_DCDC_NV_Komponentenfehler_70_XIX_HVB_Fehlerausgabe_SecondaryOBDECU_XIX_SoC_XIX_BMC_HV <-> outer port RP_IF_DCDC_NV_Komponentenfehler_70_XIX_BMC_HV  # _XIX_DCDC_SystemControl_XIX_HV_Laden_XIX_DCDC_HV_XIX_HVB_Fehlerausgabe_SecondaryOBDECU_XIX_SoC_XIX_BMC_HV_XIX_DCDC_NV_Komponentenfehler_70
    delegate HVB_Fehlerausgabe_SecondaryOBDECU_XIX_SoC_XIX_BMC_HV.RP_IF_DCDC_NV_Komponentenfehler_17_XIX_HVB_Fehlerausgabe_SecondaryOBDECU_XIX_SoC_XIX_BMC_HV <-> outer port RP_IF_DCDC_NV_Komponentenfehler_17_XIX_BMC_HV  # _XIX_DCDC_SystemControl_XIX_HV_Laden_XIX_DCDC_HV_XIX_HVB_Fehlerausgabe_SecondaryOBDECU_XIX_SoC_XIX_BMC_HV_XIX_DCDC_NV_Komponentenfehler_17
    delegate HVB_Fehlerausgabe_SecondaryOBDECU_XIX_SoC_XIX_BMC_HV.RP_IF_DCDC_NV_Komponentenfehler_3_15_XIX_HVB_Fehlerausgabe_SecondaryOBDECU_XIX_SoC_XIX_BMC_HV <-> outer port RP_IF_DCDC_NV_Komponentenfehler_3_15_XIX_BMC_HV  # _XIX_DCDC_SystemControl_XIX_HV_Laden_XIX_DCDC_HV_XIX_HVB_Fehlerausgabe_SecondaryOBDECU_XIX_SoC_XIX_BMC_HV_XIX_DCDC_NV_Komponentenfehler_3_15
    delegate HVB_Fehlerausgabe_SecondaryOBDECU_XIX_SoC_XIX_BMC_HV.RP_IF_DCDC_NV_Komponentenfehler_06_XIX_HVB_Fehlerausgabe_SecondaryOBDECU_XIX_SoC_XIX_BMC_HV <-> outer port RP_IF_DCDC_NV_Komponentenfehler_06_XIX_BMC_HV  # _XIX_DCDC_SystemControl_XIX_HV_Laden_XIX_DCDC_HV_XIX_HVB_Fehlerausgabe_SecondaryOBDECU_XIX_SoC_XIX_BMC_HV_XIX_DCDC_NV_Komponentenfehler_06
    delegate HVB_Fehlerausgabe_SecondaryOBDECU_XIX_SoC_XIX_BMC_HV.RP_IF_DCDC_NV_Komponentenfehler_49_XIX_HVB_Fehlerausgabe_SecondaryOBDECU_XIX_SoC_XIX_BMC_HV <-> outer port RP_IF_DCDC_NV_Komponentenfehler_49_XIX_BMC_HV  # _XIX_DCDC_SystemControl_XIX_HV_Laden_XIX_DCDC_HV_XIX_HVB_Fehlerausgabe_SecondaryOBDECU_XIX_SoC_XIX_BMC_HV_XIX_DCDC_NV_Komponentenfehler_49
    delegate HVB_Fehlerausgabe_SecondaryOBDECU_XIX_SoC_XIX_BMC_HV.RP_IF_DCDC_NV_Komponentenfehler_12_XIX_HVB_Fehlerausgabe_SecondaryOBDECU_XIX_SoC_XIX_BMC_HV <-> outer port RP_IF_DCDC_NV_Komponentenfehler_12_XIX_BMC_HV  # _XIX_DCDC_SystemControl_XIX_HV_Laden_XIX_DCDC_HV_XIX_HVB_Fehlerausgabe_SecondaryOBDECU_XIX_SoC_XIX_BMC_HV_XIX_DCDC_NV_Komponentenfehler_12
    delegate HVB_Fehlerausgabe_SecondaryOBDECU_XIX_SoC_XIX_BMC_HV.RP_IF_DCDC_NV_Komponentenfehler_42_XIX_HVB_Fehlerausgabe_SecondaryOBDECU_XIX_SoC_XIX_BMC_HV <-> outer port RP_IF_DCDC_NV_Komponentenfehler_42_XIX_BMC_HV  # _XIX_DCDC_SystemControl_XIX_HV_Laden_XIX_DCDC_HV_XIX_HVB_Fehlerausgabe_SecondaryOBDECU_XIX_SoC_XIX_BMC_HV_XIX_DCDC_NV_Komponentenfehler_42
    delegate HVB_Fehlerausgabe_SecondaryOBDECU_XIX_SoC_XIX_BMC_HV.RP_IF_DCDC_NV_Komponentenfehler_3_4_XIX_HVB_Fehlerausgabe_SecondaryOBDECU_XIX_SoC_XIX_BMC_HV <-> outer port RP_IF_DCDC_NV_Komponentenfehler_3_4_XIX_BMC_HV  # _XIX_DCDC_SystemControl_XIX_HV_Laden_XIX_DCDC_HV_XIX_HVB_Fehlerausgabe_SecondaryOBDECU_XIX_SoC_XIX_BMC_HV_XIX_DCDC_NV_Komponentenfehler_3_4
    delegate HVB_Fehlerausgabe_SecondaryOBDECU_XIX_SoC_XIX_BMC_HV.RP_IF_DCDC_NV_Komponentenfehler_71_XIX_HVB_Fehlerausgabe_SecondaryOBDECU_XIX_SoC_XIX_BMC_HV <-> outer port RP_IF_DCDC_NV_Komponentenfehler_71_XIX_BMC_HV  # _XIX_DCDC_SystemControl_XIX_HV_Laden_XIX_DCDC_HV_XIX_HVB_Fehlerausgabe_SecondaryOBDECU_XIX_SoC_XIX_BMC_HV_XIX_DCDC_NV_Komponentenfehler_71
    delegate HVB_Fehlerausgabe_SecondaryOBDECU_XIX_SoC_XIX_BMC_HV.RP_IF_DCDC_NV_Komponentenfehler_29_XIX_HVB_Fehlerausgabe_SecondaryOBDECU_XIX_SoC_XIX_BMC_HV <-> outer port RP_IF_DCDC_NV_Komponentenfehler_29_XIX_BMC_HV  # _XIX_DCDC_SystemControl_XIX_HV_Laden_XIX_DCDC_HV_XIX_HVB_Fehlerausgabe_SecondaryOBDECU_XIX_SoC_XIX_BMC_HV_XIX_DCDC_NV_Komponentenfehler_29
    delegate HVB_Fehlerausgabe_SecondaryOBDECU_XIX_SoC_XIX_BMC_HV.RP_IF_DCDC_NV_Komponentenfehler_21_XIX_HVB_Fehlerausgabe_SecondaryOBDECU_XIX_SoC_XIX_BMC_HV <-> outer port RP_IF_DCDC_NV_Komponentenfehler_21_XIX_BMC_HV  # _XIX_DCDC_SystemControl_XIX_HV_Laden_XIX_DCDC_HV_XIX_HVB_Fehlerausgabe_SecondaryOBDECU_XIX_SoC_XIX_BMC_HV_XIX_DCDC_NV_Komponentenfehler_21
    delegate HVB_Fehlerausgabe_SecondaryOBDECU_XIX_SoC_XIX_BMC_HV.RP_IF_DCDC_NV_Komponentenfehler_78_XIX_HVB_Fehlerausgabe_SecondaryOBDECU_XIX_SoC_XIX_BMC_HV <-> outer port RP_IF_DCDC_NV_Komponentenfehler_78_XIX_BMC_HV  # _XIX_DCDC_SystemControl_XIX_HV_Laden_XIX_DCDC_HV_XIX_HVB_Fehlerausgabe_SecondaryOBDECU_XIX_SoC_XIX_BMC_HV_XIX_DCDC_NV_Komponentenfehler_78
    delegate HVB_Fehlerausgabe_SecondaryOBDECU_XIX_SoC_XIX_BMC_HV.RP_IF_DCDC_NV_Komponentenfehler_23_XIX_HVB_Fehlerausgabe_SecondaryOBDECU_XIX_SoC_XIX_BMC_HV <-> outer port RP_IF_DCDC_NV_Komponentenfehler_23_XIX_BMC_HV  # _XIX_DCDC_SystemControl_XIX_HV_Laden_XIX_DCDC_HV_XIX_HVB_Fehlerausgabe_SecondaryOBDECU_XIX_SoC_XIX_BMC_HV_XIX_DCDC_NV_Komponentenfehler_23
    delegate HVB_Fehlerausgabe_SecondaryOBDECU_XIX_SoC_XIX_BMC_HV.RP_IF_DCDC_NV_Komponentenfehler_80_XIX_HVB_Fehlerausgabe_SecondaryOBDECU_XIX_SoC_XIX_BMC_HV <-> outer port RP_IF_DCDC_NV_Komponentenfehler_80_XIX_BMC_HV  # _XIX_DCDC_SystemControl_XIX_HV_Laden_XIX_DCDC_HV_XIX_HVB_Fehlerausgabe_SecondaryOBDECU_XIX_SoC_XIX_BMC_HV_XIX_DCDC_NV_Komponentenfehler_80
    delegate HVB_Fehlerausgabe_SecondaryOBDECU_XIX_SoC_XIX_BMC_HV.RP_IF_DCDC_NV_Komponentenfehler_75_XIX_HVB_Fehlerausgabe_SecondaryOBDECU_XIX_SoC_XIX_BMC_HV <-> outer port RP_IF_DCDC_NV_Komponentenfehler_75_XIX_BMC_HV  # _XIX_DCDC_SystemControl_XIX_HV_Laden_XIX_DCDC_HV_XIX_HVB_Fehlerausgabe_SecondaryOBDECU_XIX_SoC_XIX_BMC_HV_XIX_DCDC_NV_Komponentenfehler_75
    delegate HVB_Fehlerausgabe_SecondaryOBDECU_XIX_SoC_XIX_BMC_HV.RP_IF_DCDC_NV_Komponentenfehler_57_XIX_HVB_Fehlerausgabe_SecondaryOBDECU_XIX_SoC_XIX_BMC_HV <-> outer port RP_IF_DCDC_NV_Komponentenfehler_57_XIX_BMC_HV  # _XIX_DCDC_SystemControl_XIX_HV_Laden_XIX_DCDC_HV_XIX_HVB_Fehlerausgabe_SecondaryOBDECU_XIX_SoC_XIX_BMC_HV_XIX_DCDC_NV_Komponentenfehler_57
    delegate HVB_Fehlerausgabe_SecondaryOBDECU_XIX_SoC_XIX_BMC_HV.RP_IF_DCDC_NV_Komponentenfehler_39_XIX_HVB_Fehlerausgabe_SecondaryOBDECU_XIX_SoC_XIX_BMC_HV <-> outer port RP_IF_DCDC_NV_Komponentenfehler_39_XIX_BMC_HV  # _XIX_DCDC_SystemControl_XIX_HV_Laden_XIX_DCDC_HV_XIX_HVB_Fehlerausgabe_SecondaryOBDECU_XIX_SoC_XIX_BMC_HV_XIX_DCDC_NV_Komponentenfehler_39
    delegate HVB_Fehlerausgabe_SecondaryOBDECU_XIX_SoC_XIX_BMC_HV.RP_IF_DCDC_NV_Komponentenfehler_63_XIX_HVB_Fehlerausgabe_SecondaryOBDECU_XIX_SoC_XIX_BMC_HV <-> outer port RP_IF_DCDC_NV_Komponentenfehler_63_XIX_BMC_HV  # _XIX_DCDC_SystemControl_XIX_HV_Laden_XIX_DCDC_HV_XIX_HVB_Fehlerausgabe_SecondaryOBDECU_XIX_SoC_XIX_BMC_HV_XIX_DCDC_NV_Komponentenfehler_63
    delegate HVB_Fehlerausgabe_SecondaryOBDECU_XIX_SoC_XIX_BMC_HV.RP_IF_DCDC_NV_Komponentenfehler_28_XIX_HVB_Fehlerausgabe_SecondaryOBDECU_XIX_SoC_XIX_BMC_HV <-> outer port RP_IF_DCDC_NV_Komponentenfehler_28_XIX_BMC_HV  # _XIX_DCDC_SystemControl_XIX_HV_Laden_XIX_DCDC_HV_XIX_HVB_Fehlerausgabe_SecondaryOBDECU_XIX_SoC_XIX_BMC_HV_XIX_DCDC_NV_Komponentenfehler_28
    delegate HVB_Fehlerausgabe_SecondaryOBDECU_XIX_SoC_XIX_BMC_HV.RP_IF_DCDC_NV_Komponentenfehler_19_XIX_HVB_Fehlerausgabe_SecondaryOBDECU_XIX_SoC_XIX_BMC_HV <-> outer port RP_IF_DCDC_NV_Komponentenfehler_19_XIX_BMC_HV  # _XIX_DCDC_SystemControl_XIX_HV_Laden_XIX_DCDC_HV_XIX_HVB_Fehlerausgabe_SecondaryOBDECU_XIX_SoC_XIX_BMC_HV_XIX_DCDC_NV_Komponentenfehler_19
    delegate HVB_Fehlerausgabe_SecondaryOBDECU_XIX_SoC_XIX_BMC_HV.RP_IF_DCDC_NV_Komponentenfehler_60_XIX_HVB_Fehlerausgabe_SecondaryOBDECU_XIX_SoC_XIX_BMC_HV <-> outer port RP_IF_DCDC_NV_Komponentenfehler_60_XIX_BMC_HV  # _XIX_DCDC_SystemControl_XIX_HV_Laden_XIX_DCDC_HV_XIX_HVB_Fehlerausgabe_SecondaryOBDECU_XIX_SoC_XIX_BMC_HV_XIX_DCDC_NV_Komponentenfehler_60
    delegate HVB_Fehlerausgabe_SecondaryOBDECU_XIX_SoC_XIX_BMC_HV.RP_IF_DCDC_NV_Komponentenfehler_3_11_XIX_HVB_Fehlerausgabe_SecondaryOBDECU_XIX_SoC_XIX_BMC_HV <-> outer port RP_IF_DCDC_NV_Komponentenfehler_3_11_XIX_BMC_HV  # _XIX_DCDC_SystemControl_XIX_HV_Laden_XIX_DCDC_HV_XIX_HVB_Fehlerausgabe_SecondaryOBDECU_XIX_SoC_XIX_BMC_HV_XIX_DCDC_NV_Komponentenfehler_3_11
    delegate HVB_Fehlerausgabe_SecondaryOBDECU_XIX_SoC_XIX_BMC_HV.RP_IF_DCDC_NV_Komponentenfehler_41_XIX_HVB_Fehlerausgabe_SecondaryOBDECU_XIX_SoC_XIX_BMC_HV <-> outer port RP_IF_DCDC_NV_Komponentenfehler_41_XIX_BMC_HV  # _XIX_DCDC_SystemControl_XIX_HV_Laden_XIX_DCDC_HV_XIX_HVB_Fehlerausgabe_SecondaryOBDECU_XIX_SoC_XIX_BMC_HV_XIX_DCDC_NV_Komponentenfehler_41
    delegate HVB_Fehlerausgabe_SecondaryOBDECU_XIX_SoC_XIX_BMC_HV.RP_IF_DCDC_NV_Komponentenfehler_37_XIX_HVB_Fehlerausgabe_SecondaryOBDECU_XIX_SoC_XIX_BMC_HV <-> outer port RP_IF_DCDC_NV_Komponentenfehler_37_XIX_BMC_HV  # _XIX_DCDC_SystemControl_XIX_HV_Laden_XIX_DCDC_HV_XIX_HVB_Fehlerausgabe_SecondaryOBDECU_XIX_SoC_XIX_BMC_HV_XIX_DCDC_NV_Komponentenfehler_37
    delegate HVB_Fehlerausgabe_SecondaryOBDECU_XIX_SoC_XIX_BMC_HV.RP_IF_DCDC_NV_Komponentenfehler_3_9_XIX_HVB_Fehlerausgabe_SecondaryOBDECU_XIX_SoC_XIX_BMC_HV <-> outer port RP_IF_DCDC_NV_Komponentenfehler_3_9_XIX_BMC_HV  # _XIX_DCDC_SystemControl_XIX_HV_Laden_XIX_DCDC_HV_XIX_HVB_Fehlerausgabe_SecondaryOBDECU_XIX_SoC_XIX_BMC_HV_XIX_DCDC_NV_Komponentenfehler_3_9
    delegate HVB_Fehlerausgabe_SecondaryOBDECU_XIX_SoC_XIX_BMC_HV.RP_IF_DCDC_NV_Komponentenfehler_01_XIX_HVB_Fehlerausgabe_SecondaryOBDECU_XIX_SoC_XIX_BMC_HV <-> outer port RP_IF_DCDC_NV_Komponentenfehler_01_XIX_BMC_HV  # _XIX_DCDC_SystemControl_XIX_HV_Laden_XIX_DCDC_HV_XIX_HVB_Fehlerausgabe_SecondaryOBDECU_XIX_SoC_XIX_BMC_HV_XIX_DCDC_NV_Komponentenfehler_01
    delegate HVB_Fehlerausgabe_SecondaryOBDECU_XIX_SoC_XIX_BMC_HV.RP_IF_DCDC_NV_Komponentenfehler_61_XIX_HVB_Fehlerausgabe_SecondaryOBDECU_XIX_SoC_XIX_BMC_HV <-> outer port RP_IF_DCDC_NV_Komponentenfehler_61_XIX_BMC_HV  # _XIX_DCDC_SystemControl_XIX_HV_Laden_XIX_DCDC_HV_XIX_HVB_Fehlerausgabe_SecondaryOBDECU_XIX_SoC_XIX_BMC_HV_XIX_DCDC_NV_Komponentenfehler_61
    delegate HVB_Fehlerausgabe_SecondaryOBDECU_XIX_SoC_XIX_BMC_HV.RP_IF_DCDC_NV_Komponentenfehler_64_XIX_HVB_Fehlerausgabe_SecondaryOBDECU_XIX_SoC_XIX_BMC_HV <-> outer port RP_IF_DCDC_NV_Komponentenfehler_64_XIX_BMC_HV  # _XIX_DCDC_SystemControl_XIX_HV_Laden_XIX_DCDC_HV_XIX_HVB_Fehlerausgabe_SecondaryOBDECU_XIX_SoC_XIX_BMC_HV_XIX_DCDC_NV_Komponentenfehler_64
    delegate HVB_Fehlerausgabe_SecondaryOBDECU_XIX_SoC_XIX_BMC_HV.RP_IF_DCDC_NV_Komponentenfehler_62_XIX_HVB_Fehlerausgabe_SecondaryOBDECU_XIX_SoC_XIX_BMC_HV <-> outer port RP_IF_DCDC_NV_Komponentenfehler_62_XIX_BMC_HV  # _XIX_DCDC_SystemControl_XIX_HV_Laden_XIX_DCDC_HV_XIX_HVB_Fehlerausgabe_SecondaryOBDECU_XIX_SoC_XIX_BMC_HV_XIX_DCDC_NV_Komponentenfehler_62
    delegate HVB_Fehlerausgabe_SecondaryOBDECU_XIX_SoC_XIX_BMC_HV.RP_IF_DCDC_NV_Komponentenfehler_10_XIX_HVB_Fehlerausgabe_SecondaryOBDECU_XIX_SoC_XIX_BMC_HV <-> outer port RP_IF_DCDC_NV_Komponentenfehler_10_XIX_BMC_HV  # _XIX_DCDC_SystemControl_XIX_HV_Laden_XIX_DCDC_HV_XIX_HVB_Fehlerausgabe_SecondaryOBDECU_XIX_SoC_XIX_BMC_HV_XIX_DCDC_NV_Komponentenfehler_10
    delegate HVB_Fehlerausgabe_SecondaryOBDECU_XIX_SoC_XIX_BMC_HV.RP_IF_DCDC_NV_Komponentenfehler_24_XIX_HVB_Fehlerausgabe_SecondaryOBDECU_XIX_SoC_XIX_BMC_HV <-> outer port RP_IF_DCDC_NV_Komponentenfehler_24_XIX_BMC_HV  # _XIX_DCDC_SystemControl_XIX_HV_Laden_XIX_DCDC_HV_XIX_HVB_Fehlerausgabe_SecondaryOBDECU_XIX_SoC_XIX_BMC_HV_XIX_DCDC_NV_Komponentenfehler_24
    delegate diagnosis_infrastructure_Hybrid_01_XIX_diagnosis_infrastructure_XIX_BMC_HV.RP_IF_DW_Kilometerstand_XIX_diagnosis_infrastructure_Hybrid_01_XIX_diagnosis_infrastructure_XIX_BMC_HV <-> outer port RP_IF_DW_Kilometerstand_XIX_BMC_HV  # _XIX_DiagnoseWegstrecke_XIX_DiagBasis_XIX_HCP5_P1_Gateway_XIX_diagnosis_infrastructure_Hybrid_01_XIX_diagnosis_infrastructure_XIX_BMC_HV_XIX_DW_Kilometerstand
    delegate HochvoltBatterieManagement_XIX_SoC_XIX_BMC_HV.RP_IF_SG_HVLM_14_XIX_HochvoltBatterieManagement_XIX_SoC_XIX_BMC_HV <-> outer port RP_IF_SG_HVLM_14_XIX_BMC_HV
    delegate HochvoltBatterieManagement_XIX_SoC_XIX_BMC_HV.RP_IF_HVLM_BCAM_Aktiv_XIX_HochvoltBatterieManagement_XIX_SoC_XIX_BMC_HV <-> outer port RP_IF_HVLM_BCAM_Aktiv_XIX_BMC_HV
    delegate HochvoltBatterieManagement_XIX_SoC_XIX_BMC_HV.RP_IF_HVLM_BidiLadeModus_XIX_HochvoltBatterieManagement_XIX_SoC_XIX_BMC_HV <-> outer port RP_IF_HVLM_BidiLadeModus_XIX_BMC_HV
    delegate HV_Batterie_RTM_XIX_RTM_XIX_BMC_HV.SP_IF_BMC_CMC_Temperatur_{001..019}_XIX_HV_Batterie_RTM_XIX_RTM_XIX_BMC_HV <-> outer port SP_IF_BMC_CMC_Temperatur_{001..019}_XIX_BMC_HV
    delegate HV_Batterie_RTM_XIX_RTM_XIX_BMC_HV.SP_IF_BMC_CMC_Temperatur_01_Messzeit_XIX_HV_Batterie_RTM_XIX_RTM_XIX_BMC_HV <-> outer port SP_IF_BMC_CMC_Temperatur_01_Messzeit_XIX_BMC_HV
    delegate HV_Batterie_RTM_XIX_RTM_XIX_BMC_HV.SP_IF_BMC_CMC_Temperatur_{020..029}_XIX_HV_Batterie_RTM_XIX_RTM_XIX_BMC_HV <-> outer port SP_IF_BMC_CMC_Temperatur_{020..029}_XIX_BMC_HV
    delegate HV_Batterie_RTM_XIX_RTM_XIX_BMC_HV.SP_IF_BMC_CMC_Temperatur_02_Messzeit_XIX_HV_Batterie_RTM_XIX_RTM_XIX_BMC_HV <-> outer port SP_IF_BMC_CMC_Temperatur_02_Messzeit_XIX_BMC_HV
    delegate HV_Batterie_RTM_XIX_RTM_XIX_BMC_HV.SP_IF_BMC_CMC_Temperatur_{030..039}_XIX_HV_Batterie_RTM_XIX_RTM_XIX_BMC_HV <-> outer port SP_IF_BMC_CMC_Temperatur_{030..039}_XIX_BMC_HV
    delegate HV_Batterie_RTM_XIX_RTM_XIX_BMC_HV.SP_IF_BMC_CMC_Temperatur_03_Messzeit_XIX_HV_Batterie_RTM_XIX_RTM_XIX_BMC_HV <-> outer port SP_IF_BMC_CMC_Temperatur_03_Messzeit_XIX_BMC_HV
    delegate HV_Batterie_RTM_XIX_RTM_XIX_BMC_HV.SP_IF_BMC_CMC_Temperatur_{040..096}_XIX_HV_Batterie_RTM_XIX_RTM_XIX_BMC_HV <-> outer port SP_IF_BMC_CMC_Temperatur_{040..096}_XIX_BMC_HV
    delegate HV_Batterie_RTM_XIX_RTM_XIX_BMC_HV.SP_IF_BMC_CMC_Zellspannung_{001..019}_XIX_HV_Batterie_RTM_XIX_RTM_XIX_BMC_HV <-> outer port SP_IF_BMC_CMC_Zellspannung_{001..019}_XIX_BMC_HV
    delegate HV_Batterie_RTM_XIX_RTM_XIX_BMC_HV.SP_IF_BMC_CMC_Zellspannung_01_Messzeit_XIX_HV_Batterie_RTM_XIX_RTM_XIX_BMC_HV <-> outer port SP_IF_BMC_CMC_Zellspannung_01_Messzeit_XIX_BMC_HV
    delegate HV_Batterie_RTM_XIX_RTM_XIX_BMC_HV.SP_IF_BMC_CMC_Zellspannung_{020..029}_XIX_HV_Batterie_RTM_XIX_RTM_XIX_BMC_HV <-> outer port SP_IF_BMC_CMC_Zellspannung_{020..029}_XIX_BMC_HV
    delegate HV_Batterie_RTM_XIX_RTM_XIX_BMC_HV.SP_IF_BMC_CMC_Zellspannung_02_Messzeit_XIX_HV_Batterie_RTM_XIX_RTM_XIX_BMC_HV <-> outer port SP_IF_BMC_CMC_Zellspannung_02_Messzeit_XIX_BMC_HV
    delegate HV_Batterie_RTM_XIX_RTM_XIX_BMC_HV.SP_IF_BMC_CMC_Zellspannung_{030..039}_XIX_HV_Batterie_RTM_XIX_RTM_XIX_BMC_HV <-> outer port SP_IF_BMC_CMC_Zellspannung_{030..039}_XIX_BMC_HV
    delegate HV_Batterie_RTM_XIX_RTM_XIX_BMC_HV.SP_IF_BMC_CMC_Zellspannung_03_Messzeit_XIX_HV_Batterie_RTM_XIX_RTM_XIX_BMC_HV <-> outer port SP_IF_BMC_CMC_Zellspannung_03_Messzeit_XIX_BMC_HV
    delegate HV_Batterie_RTM_XIX_RTM_XIX_BMC_HV.SP_IF_BMC_CMC_Zellspannung_{040..049}_XIX_HV_Batterie_RTM_XIX_RTM_XIX_BMC_HV <-> outer port SP_IF_BMC_CMC_Zellspannung_{040..049}_XIX_BMC_HV
    delegate HV_Batterie_RTM_XIX_RTM_XIX_BMC_HV.SP_IF_BMC_CMC_Zellspannung_04_Messzeit_XIX_HV_Batterie_RTM_XIX_RTM_XIX_BMC_HV <-> outer port SP_IF_BMC_CMC_Zellspannung_04_Messzeit_XIX_BMC_HV
    delegate HV_Batterie_RTM_XIX_RTM_XIX_BMC_HV.SP_IF_BMC_CMC_Zellspannung_{050..059}_XIX_HV_Batterie_RTM_XIX_RTM_XIX_BMC_HV <-> outer port SP_IF_BMC_CMC_Zellspannung_{050..059}_XIX_BMC_HV
    delegate HV_Batterie_RTM_XIX_RTM_XIX_BMC_HV.SP_IF_BMC_CMC_Zellspannung_05_Messzeit_XIX_HV_Batterie_RTM_XIX_RTM_XIX_BMC_HV <-> outer port SP_IF_BMC_CMC_Zellspannung_05_Messzeit_XIX_BMC_HV
    delegate HV_Batterie_RTM_XIX_RTM_XIX_BMC_HV.SP_IF_BMC_CMC_Zellspannung_{060..192}_XIX_HV_Batterie_RTM_XIX_RTM_XIX_BMC_HV <-> outer port SP_IF_BMC_CMC_Zellspannung_{060..192}_XIX_BMC_HV
    delegate HV_Batterie_RTM_XIX_RTM_XIX_BMC_HV.SP_IF_BMC_IstTemperaturMax_Modul_ID_XIX_HV_Batterie_RTM_XIX_RTM_XIX_BMC_HV <-> outer port SP_IF_BMC_IstTemperaturMax_Modul_ID_XIX_BMC_HV
    delegate HV_Batterie_RTM_XIX_RTM_XIX_BMC_HV.SP_IF_BMC_IstTemperaturMax_Sensor_ID_XIX_HV_Batterie_RTM_XIX_RTM_XIX_BMC_HV <-> outer port SP_IF_BMC_IstTemperaturMax_Sensor_ID_XIX_BMC_HV
    delegate HV_Batterie_RTM_XIX_RTM_XIX_BMC_HV.SP_IF_BMC_IstTemperaturMin_Modul_ID_XIX_HV_Batterie_RTM_XIX_RTM_XIX_BMC_HV <-> outer port SP_IF_BMC_IstTemperaturMin_Modul_ID_XIX_BMC_HV
    delegate HV_Batterie_RTM_XIX_RTM_XIX_BMC_HV.SP_IF_BMC_IstTemperaturMin_Sensor_ID_XIX_HV_Batterie_RTM_XIX_RTM_XIX_BMC_HV <-> outer port SP_IF_BMC_IstTemperaturMin_Sensor_ID_XIX_BMC_HV
    delegate HV_Batterie_RTM_XIX_RTM_XIX_BMC_HV.SP_IF_BMC_IstZellSpannungMax_Modul_ID_XIX_HV_Batterie_RTM_XIX_RTM_XIX_BMC_HV <-> outer port SP_IF_BMC_IstZellSpannungMax_Modul_ID_XIX_BMC_HV
    delegate HV_Batterie_RTM_XIX_RTM_XIX_BMC_HV.SP_IF_BMC_IstZellSpannungMax_Zell_ID_XIX_HV_Batterie_RTM_XIX_RTM_XIX_BMC_HV <-> outer port SP_IF_BMC_IstZellSpannungMax_Zell_ID_XIX_BMC_HV
    delegate HV_Batterie_RTM_XIX_RTM_XIX_BMC_HV.SP_IF_BMC_IstZellSpannungMin_Modul_ID_XIX_HV_Batterie_RTM_XIX_RTM_XIX_BMC_HV <-> outer port SP_IF_BMC_IstZellSpannungMin_Modul_ID_XIX_BMC_HV
    delegate HV_Batterie_RTM_XIX_RTM_XIX_BMC_HV.SP_IF_BMC_IstZellSpannungMin_Zell_ID_XIX_HV_Batterie_RTM_XIX_RTM_XIX_BMC_HV <-> outer port SP_IF_BMC_IstZellSpannungMin_Zell_ID_XIX_BMC_HV
    delegate HV_Batterie_RTM_XIX_RTM_XIX_BMC_HV.SP_IF_BMC_IstZellspannungMax_XIX_HV_Batterie_RTM_XIX_RTM_XIX_BMC_HV <-> outer port SP_IF_BMC_IstZellspannungMax_XIX_BMC_HV
    delegate HV_Batterie_RTM_XIX_RTM_XIX_BMC_HV.SP_IF_BMC_IstZellspannungMin_XIX_HV_Batterie_RTM_XIX_RTM_XIX_BMC_HV <-> outer port SP_IF_BMC_IstZellspannungMin_XIX_BMC_HV
    delegate HV_Batterie_RTM_XIX_RTM_XIX_BMC_HV.SP_IF_BMC_Pack_SN_{01..26}_XIX_HV_Batterie_RTM_XIX_RTM_XIX_BMC_HV <-> outer port SP_IF_BMC_Pack_SN_{01..26}_XIX_BMC_HV
    delegate HV_Batterie_RTM_XIX_RTM_XIX_BMC_HV.SP_IF_BMC_RtmWarnBattUnautorisiert_XIX_HV_Batterie_RTM_XIX_RTM_XIX_BMC_HV <-> outer port SP_IF_BMC_RtmWarnBattUnautorisiert_XIX_BMC_HV
    delegate HV_Batterie_RTM_XIX_RTM_XIX_BMC_HV.SP_IF_BMC_RtmWarnPackKommunikation_XIX_HV_Batterie_RTM_XIX_RTM_XIX_BMC_HV <-> outer port SP_IF_BMC_RtmWarnPackKommunikation_XIX_BMC_HV
    delegate HV_Batterie_RTM_XIX_RTM_XIX_BMC_HV.SP_IF_BMC_RtmWarnPackUeberladen_XIX_HV_Batterie_RTM_XIX_RTM_XIX_BMC_HV <-> outer port SP_IF_BMC_RtmWarnPackUeberladen_XIX_BMC_HV
    delegate HV_Batterie_RTM_XIX_RTM_XIX_BMC_HV.SP_IF_BMC_RtmWarnSocHoch_XIX_HV_Batterie_RTM_XIX_RTM_XIX_BMC_HV <-> outer port SP_IF_BMC_RtmWarnSocHoch_XIX_BMC_HV
    delegate HV_Batterie_RTM_XIX_RTM_XIX_BMC_HV.SP_IF_BMC_RtmWarnSocNiedrig_XIX_HV_Batterie_RTM_XIX_RTM_XIX_BMC_HV <-> outer port SP_IF_BMC_RtmWarnSocNiedrig_XIX_BMC_HV
    delegate HV_Batterie_RTM_XIX_RTM_XIX_BMC_HV.SP_IF_BMC_RtmWarnSocSprung_XIX_HV_Batterie_RTM_XIX_RTM_XIX_BMC_HV <-> outer port SP_IF_BMC_RtmWarnSocSprung_XIX_BMC_HV
    delegate HV_Batterie_RTM_XIX_RTM_XIX_BMC_HV.SP_IF_BMC_RtmWarnTZelleDiff_XIX_HV_Batterie_RTM_XIX_RTM_XIX_BMC_HV <-> outer port SP_IF_BMC_RtmWarnTZelleDiff_XIX_BMC_HV
    delegate HV_Batterie_RTM_XIX_RTM_XIX_BMC_HV.SP_IF_BMC_RtmWarnTZelleMax_XIX_HV_Batterie_RTM_XIX_RTM_XIX_BMC_HV <-> outer port SP_IF_BMC_RtmWarnTZelleMax_XIX_BMC_HV
    delegate HV_Batterie_RTM_XIX_RTM_XIX_BMC_HV.SP_IF_BMC_RtmWarnTZelleMin_XIX_HV_Batterie_RTM_XIX_RTM_XIX_BMC_HV <-> outer port SP_IF_BMC_RtmWarnTZelleMin_XIX_BMC_HV
    delegate HV_Batterie_RTM_XIX_RTM_XIX_BMC_HV.SP_IF_BMC_RtmWarnUPackMax_XIX_HV_Batterie_RTM_XIX_RTM_XIX_BMC_HV <-> outer port SP_IF_BMC_RtmWarnUPackMax_XIX_BMC_HV
    delegate HV_Batterie_RTM_XIX_RTM_XIX_BMC_HV.SP_IF_BMC_RtmWarnUPackMin_XIX_HV_Batterie_RTM_XIX_RTM_XIX_BMC_HV <-> outer port SP_IF_BMC_RtmWarnUPackMin_XIX_BMC_HV
    delegate HV_Batterie_RTM_XIX_RTM_XIX_BMC_HV.SP_IF_BMC_RtmWarnUZelleMax_XIX_HV_Batterie_RTM_XIX_RTM_XIX_BMC_HV <-> outer port SP_IF_BMC_RtmWarnUZelleMax_XIX_BMC_HV
    delegate HV_Batterie_RTM_XIX_RTM_XIX_BMC_HV.SP_IF_BMC_RtmWarnUZelleMin_XIX_HV_Batterie_RTM_XIX_RTM_XIX_BMC_HV <-> outer port SP_IF_BMC_RtmWarnUZelleMin_XIX_BMC_HV
    delegate HV_Batterie_RTM_XIX_RTM_XIX_BMC_HV.SP_IF_BMC_RtmWarnUeberstrom_XIX_HV_Batterie_RTM_XIX_RTM_XIX_BMC_HV <-> outer port SP_IF_BMC_RtmWarnUeberstrom_XIX_BMC_HV
    delegate HV_Batterie_RTM_XIX_RTM_XIX_BMC_HV.SP_IF_BMC_RtmWarnZelleZustand_XIX_HV_Batterie_RTM_XIX_RTM_XIX_BMC_HV <-> outer port SP_IF_BMC_RtmWarnZelleZustand_XIX_BMC_HV
    delegate HV_Batterie_RTM_XIX_RTM_XIX_BMC_HV.SP_IF_BMC_Spannung_Messzeit_XIX_HV_Batterie_RTM_XIX_RTM_XIX_BMC_HV <-> outer port SP_IF_BMC_Spannung_Messzeit_XIX_BMC_HV
    delegate HV_Batterie_RTM_XIX_RTM_XIX_BMC_HV.SP_IF_BMC_Strom_Messzeit_XIX_HV_Batterie_RTM_XIX_RTM_XIX_BMC_HV <-> outer port SP_IF_BMC_Strom_Messzeit_XIX_BMC_HV
    delegate HV_Batterie_RTM_XIX_RTM_XIX_BMC_HV.SP_IF_BMC_Temperatur_hoechste_XIX_HV_Batterie_RTM_XIX_RTM_XIX_BMC_HV <-> outer port SP_IF_BMC_Temperatur_hoechste_XIX_BMC_HV
    delegate HV_Batterie_RTM_XIX_RTM_XIX_BMC_HV.SP_IF_BMC_Temperatur_niedrigste_XIX_HV_Batterie_RTM_XIX_RTM_XIX_BMC_HV <-> outer port SP_IF_BMC_Temperatur_niedrigste_XIX_BMC_HV
    delegate BMC_HV_Netzsteuerung_XIX_NV_SD_XIX_BMC_HV.RP_IF_SG_HVK_03_XIX_BMC_HV_Netzsteuerung_XIX_NV_SD_XIX_BMC_HV <-> outer port RP_IF_SG_HVK_03_XIX_BMC_HV
    delegate HochvoltBatterieManagement_XIX_SoC_XIX_BMC_HV.RP_IF_SG_HVK_03_XIX_HochvoltBatterieManagement_XIX_SoC_XIX_BMC_HV <-> outer port RP_IF_SG_HVK_03_XIX_BMC_HV  # DCon_XIX_HighVoltageCoordinatorControl_XIX_HVK_XIX_HCP5_P2_OBD_Safety_XIX_HochvoltBatterieManagement_XIX_SoC_XIX_BMC_HV_XIX_SG_HVK_03
    delegate HochvoltBatterieManagement_XIX_SoC_XIX_BMC_HV.SP_IF_BMC_AC_Laden_XIX_HochvoltBatterieManagement_XIX_SoC_XIX_BMC_HV <-> outer port SP_IF_BMC_AC_Laden_XIX_BMC_HV
    delegate HochvoltBatterieManagement_XIX_SoC_XIX_BMC_HV.SP_IF_BMC_Abschaltankuendigung_XIX_HochvoltBatterieManagement_XIX_SoC_XIX_BMC_HV <-> outer port SP_IF_BMC_Abschaltankuendigung_XIX_BMC_HV
    delegate HochvoltBatterieManagement_XIX_SoC_XIX_BMC_HV.SP_IF_BMC_Bank_Notlauf_erlaubt_XIX_HochvoltBatterieManagement_XIX_SoC_XIX_BMC_HV <-> outer port SP_IF_BMC_Bank_Notlauf_erlaubt_XIX_BMC_HV  # _XIX_HochvoltBatterieManagement_XIX_SoC_XIX_BMC_HV_XIX_HighVoltageCoordinatorControl_XIX_HVK_XIX_HCP5_P2_OBD_Safety_XIX_BMC_Bank_Notlauf_erlaubt
    delegate HochvoltBatterieManagement_XIX_SoC_XIX_BMC_HV.SP_IF_BMC_Bank_parallel_erlaubt_XIX_HochvoltBatterieManagement_XIX_SoC_XIX_BMC_HV <-> outer port SP_IF_BMC_Bank_parallel_erlaubt_XIX_BMC_HV  # _XIX_HochvoltBatterieManagement_XIX_SoC_XIX_BMC_HV_XIX_HighVoltageCoordinatorControl_XIX_HVK_XIX_HCP5_P2_OBD_Safety_XIX_BMC_Bank_parallel_erlaubt
    delegate HochvoltBatterieManagement_XIX_SoC_XIX_BMC_HV.SP_IF_BMC_Bank_seriell_erlaubt_XIX_HochvoltBatterieManagement_XIX_SoC_XIX_BMC_HV <-> outer port SP_IF_BMC_Bank_seriell_erlaubt_XIX_BMC_HV  # _XIX_HochvoltBatterieManagement_XIX_SoC_XIX_BMC_HV_XIX_HighVoltageCoordinatorControl_XIX_HVK_XIX_HCP5_P2_OBD_Safety_XIX_BMC_Bank_seriell_erlaubt
    delegate HochvoltBatterieManagement_XIX_SoC_XIX_BMC_HV.SP_IF_BMC_Bankstatus_XIX_HochvoltBatterieManagement_XIX_SoC_XIX_BMC_HV <-> outer port SP_IF_BMC_Bankstatus_XIX_BMC_HV
    delegate HochvoltBatterieManagement_XIX_SoC_XIX_BMC_HV.SP_IF_BMC_Bidi_Energie_Absolut_XIX_HochvoltBatterieManagement_XIX_SoC_XIX_BMC_HV <-> outer port SP_IF_BMC_Bidi_Energie_Absolut_XIX_BMC_HV
    delegate HochvoltBatterieManagement_XIX_SoC_XIX_BMC_HV.SP_IF_BMC_Bidi_Freigabe_XIX_HochvoltBatterieManagement_XIX_SoC_XIX_BMC_HV <-> outer port SP_IF_BMC_Bidi_Freigabe_XIX_BMC_HV
    delegate HochvoltBatterieManagement_XIX_SoC_XIX_BMC_HV.SP_IF_BMC_Bidi_GenutzteEnergie_XIX_HochvoltBatterieManagement_XIX_SoC_XIX_BMC_HV <-> outer port SP_IF_BMC_Bidi_GenutzteEnergie_XIX_BMC_HV
    delegate HochvoltBatterieManagement_XIX_SoC_XIX_BMC_HV.SP_IF_BMC_Bidi_Max_SoC_XIX_HochvoltBatterieManagement_XIX_SoC_XIX_BMC_HV <-> outer port SP_IF_BMC_Bidi_Max_SoC_XIX_BMC_HV
    delegate HochvoltBatterieManagement_XIX_SoC_XIX_BMC_HV.SP_IF_BMC_Bidi_Min_SoC_XIX_HochvoltBatterieManagement_XIX_SoC_XIX_BMC_HV <-> outer port SP_IF_BMC_Bidi_Min_SoC_XIX_BMC_HV
    delegate HochvoltBatterieManagement_XIX_SoC_XIX_BMC_HV.SP_IF_BMC_Bidi_Veto_Energie_XIX_HochvoltBatterieManagement_XIX_SoC_XIX_BMC_HV <-> outer port SP_IF_BMC_Bidi_Veto_Energie_XIX_BMC_HV
    delegate HochvoltBatterieManagement_XIX_SoC_XIX_BMC_HV.SP_IF_BMC_Bidi_Veto_Temp_XIX_HochvoltBatterieManagement_XIX_SoC_XIX_BMC_HV <-> outer port SP_IF_BMC_Bidi_Veto_Temp_XIX_BMC_HV
    delegate HochvoltBatterieManagement_XIX_SoC_XIX_BMC_HV.SP_IF_BMC_DC_Laden_XIX_HochvoltBatterieManagement_XIX_SoC_XIX_BMC_HV <-> outer port SP_IF_BMC_DC_Laden_XIX_BMC_HV
    delegate HochvoltBatterieManagement_XIX_SoC_XIX_BMC_HV.SP_IF_BMC_Dauer_Entladeleistung_XIX_HochvoltBatterieManagement_XIX_SoC_XIX_BMC_HV <-> outer port SP_IF_BMC_Dauer_Entladeleistung_XIX_BMC_HV  # _XIX_HochvoltBatterieManagement_XIX_SoC_XIX_BMC_HV_XIX_ElectricTractionManagerReceive_XIX_FahrenBEV_XIX_HCP1_XIX_BMC_Dauer_Entladeleistung
    delegate HochvoltBatterieManagement_XIX_SoC_XIX_BMC_HV.SP_IF_BMC_Dauer_Entladeleistung_02_XIX_HochvoltBatterieManagement_XIX_SoC_XIX_BMC_HV <-> outer port SP_IF_BMC_Dauer_Entladeleistung_02_XIX_BMC_HV  # _XIX_HochvoltBatterieManagement_XIX_SoC_XIX_BMC_HV_XIX_ElectricTractionManagerReceive_XIX_FahrenBEV_XIX_HCP1_XIX_BMC_Dauer_Entladeleistung_02
    delegate HochvoltBatterieManagement_XIX_SoC_XIX_BMC_HV.SP_IF_BMC_Dauer_Ladeleistung_XIX_HochvoltBatterieManagement_XIX_SoC_XIX_BMC_HV <-> outer port SP_IF_BMC_Dauer_Ladeleistung_XIX_BMC_HV  # _XIX_HochvoltBatterieManagement_XIX_SoC_XIX_BMC_HV_XIX_ElectricTractionManagerReceive_XIX_FahrenBEV_XIX_HCP1_XIX_BMC_Dauer_Ladeleistung
    delegate HochvoltBatterieManagement_XIX_SoC_XIX_BMC_HV.SP_IF_BMC_Dauer_Ladeleistung_02_XIX_HochvoltBatterieManagement_XIX_SoC_XIX_BMC_HV <-> outer port SP_IF_BMC_Dauer_Ladeleistung_02_XIX_BMC_HV  # _XIX_HochvoltBatterieManagement_XIX_SoC_XIX_BMC_HV_XIX_ElectricTractionManagerReceive_XIX_FahrenBEV_XIX_HCP1_XIX_BMC_Dauer_Ladeleistung_02
    delegate HochvoltBatterieManagement_XIX_SoC_XIX_BMC_HV.SP_IF_BMC_Dev_Freigabe_XIX_HochvoltBatterieManagement_XIX_SoC_XIX_BMC_HV <-> outer port SP_IF_BMC_Dev_Freigabe_XIX_BMC_HV
    delegate HochvoltBatterieManagement_XIX_SoC_XIX_BMC_HV.SP_IF_BMC_EnergieVorhalt_XIX_HochvoltBatterieManagement_XIX_SoC_XIX_BMC_HV <-> outer port SP_IF_BMC_EnergieVorhalt_XIX_BMC_HV  # _XIX_HochvoltBatterieManagement_XIX_SoC_XIX_BMC_HV_XIX_CarMenues_XIX_UserInterface_XIX_HCP3_CN1_Systempartition_XIX_BMC_EnergieVorhalt
    delegate HochvoltBatterieManagement_XIX_SoC_XIX_BMC_HV.SP_IF_BMC_Energie_Entladen_XIX_HochvoltBatterieManagement_XIX_SoC_XIX_BMC_HV <-> outer port SP_IF_BMC_Energie_Entladen_XIX_BMC_HV
    delegate HochvoltBatterieManagement_XIX_SoC_XIX_BMC_HV.SP_IF_BMC_Energie_Laden_XIX_HochvoltBatterieManagement_XIX_SoC_XIX_BMC_HV <-> outer port SP_IF_BMC_Energie_Laden_XIX_BMC_HV
    delegate HochvoltBatterieManagement_XIX_SoC_XIX_BMC_HV.SP_IF_BMC_Energie_Sockel_SoC_XIX_HochvoltBatterieManagement_XIX_SoC_XIX_BMC_HV <-> outer port SP_IF_BMC_Energie_Sockel_SoC_XIX_BMC_HV  # _XIX_HochvoltBatterieManagement_XIX_SoC_XIX_BMC_HV_XIX_Reichweitenberechnung_XIX_RWB_30_XIX_HCP5_P1_Gateway_XIX_BMC_Energie_Sockel_SoC
    delegate HochvoltBatterieManagement_XIX_SoC_XIX_BMC_HV.SP_IF_BMC_Energieinhalt_XIX_HochvoltBatterieManagement_XIX_SoC_XIX_BMC_HV <-> outer port SP_IF_BMC_Energieinhalt_XIX_BMC_HV  # _XIX_HochvoltBatterieManagement_XIX_SoC_XIX_BMC_HV_XIX_ElectricTractionManagerReceive_XIX_FahrenBEV_XIX_HCP1_XIX_BMC_Energieinhalt
    delegate HochvoltBatterieManagement_XIX_SoC_XIX_BMC_HV.SP_IF_BMC_ExtLadeleistung_XIX_HochvoltBatterieManagement_XIX_SoC_XIX_BMC_HV <-> outer port SP_IF_BMC_ExtLadeleistung_XIX_BMC_HV
    delegate HochvoltBatterieManagement_XIX_SoC_XIX_BMC_HV.SP_IF_BMC_Fehler_Leistungsred_XIX_HochvoltBatterieManagement_XIX_SoC_XIX_BMC_HV <-> outer port SP_IF_BMC_Fehler_Leistungsred_XIX_BMC_HV  # _XIX_HochvoltBatterieManagement_XIX_SoC_XIX_BMC_HV_XIX_ElectricTractionManagerReceive_XIX_FahrenBEV_XIX_HCP1_XIX_BMC_Fehler_Leistungsred
    delegate HochvoltBatterieManagement_XIX_SoC_XIX_BMC_HV.SP_IF_BMC_Fehler_Warnung_XIX_HochvoltBatterieManagement_XIX_SoC_XIX_BMC_HV <-> outer port SP_IF_BMC_Fehler_Warnung_XIX_BMC_HV  # _XIX_HochvoltBatterieManagement_XIX_SoC_XIX_BMC_HV_XIX_HochvoltEnergiemanagement_XIX_HVEM_XIX_HCP5_P2_OBD_Safety_XIX_BMC_Fehler_Warnung
    delegate HochvoltBatterieManagement_XIX_SoC_XIX_BMC_HV.SP_IF_BMC_Flash_Freigabe_XIX_HochvoltBatterieManagement_XIX_SoC_XIX_BMC_HV <-> outer port SP_IF_BMC_Flash_Freigabe_XIX_BMC_HV
    delegate HochvoltBatterieManagement_XIX_SoC_XIX_BMC_HV.SP_IF_BMC_HV_01_BZ_XIX_HochvoltBatterieManagement_XIX_SoC_XIX_BMC_HV <-> outer port SP_IF_BMC_HV_01_BZ_XIX_BMC_HV
    delegate HochvoltBatterieManagement_XIX_SoC_XIX_BMC_HV.SP_IF_BMC_HV_01_CRC_XIX_HochvoltBatterieManagement_XIX_SoC_XIX_BMC_HV <-> outer port SP_IF_BMC_HV_01_CRC_XIX_BMC_HV
    delegate HochvoltBatterieManagement_XIX_SoC_XIX_BMC_HV.SP_IF_BMC_HV_02_BZ_XIX_HochvoltBatterieManagement_XIX_SoC_XIX_BMC_HV <-> outer port SP_IF_BMC_HV_02_BZ_XIX_BMC_HV
    delegate HochvoltBatterieManagement_XIX_SoC_XIX_BMC_HV.SP_IF_BMC_HV_02_CRC_XIX_HochvoltBatterieManagement_XIX_SoC_XIX_BMC_HV <-> outer port SP_IF_BMC_HV_02_CRC_XIX_BMC_HV  # _XIX_HochvoltBatterieManagement_XIX_SoC_XIX_BMC_HV_XIX_AnsteuerungSteckerverriegelung_VAS_XIX_HV_Laden_XIX_SACID_1_XIX_BMC_HV_02_CRC
    delegate HochvoltBatterieManagement_XIX_SoC_XIX_BMC_HV.SP_IF_BMC_HV_04_BZ_XIX_HochvoltBatterieManagement_XIX_SoC_XIX_BMC_HV <-> outer port SP_IF_BMC_HV_04_BZ_XIX_BMC_HV
    delegate HochvoltBatterieManagement_XIX_SoC_XIX_BMC_HV.SP_IF_BMC_HV_04_CRC_XIX_HochvoltBatterieManagement_XIX_SoC_XIX_BMC_HV <-> outer port SP_IF_BMC_HV_04_CRC_XIX_BMC_HV
    delegate HochvoltBatterieManagement_XIX_SoC_XIX_BMC_HV.SP_IF_BMC_Iso_Mode_Anf_XIX_HochvoltBatterieManagement_XIX_SoC_XIX_BMC_HV <-> outer port SP_IF_BMC_Iso_Mode_Anf_XIX_BMC_HV
    delegate HochvoltBatterieManagement_XIX_SoC_XIX_BMC_HV.SP_IF_BMC_Konditionierung_Anf_XIX_HochvoltBatterieManagement_XIX_SoC_XIX_BMC_HV <-> outer port SP_IF_BMC_Konditionierung_Anf_XIX_BMC_HV
    delegate HochvoltBatterieManagement_XIX_SoC_XIX_BMC_HV.SP_IF_BMC_KundenWarnung_XIX_HochvoltBatterieManagement_XIX_SoC_XIX_BMC_HV <-> outer port SP_IF_BMC_KundenWarnung_XIX_BMC_HV
    delegate HochvoltBatterieManagement_XIX_SoC_XIX_BMC_HV.SP_IF_BMC_Leerlaufspannung_XIX_HochvoltBatterieManagement_XIX_SoC_XIX_BMC_HV <-> outer port SP_IF_BMC_Leerlaufspannung_XIX_BMC_HV  # _XIX_HochvoltBatterieManagement_XIX_SoC_XIX_BMC_HV_XIX_ElectricTractionManagerReceive_XIX_FahrenBEV_XIX_HCP1_XIX_BMC_Leerlaufspannung
    delegate HochvoltBatterieManagement_XIX_SoC_XIX_BMC_HV.SP_IF_BMC_MMTR_Status_XIX_HochvoltBatterieManagement_XIX_SoC_XIX_BMC_HV <-> outer port SP_IF_BMC_MMTR_Status_XIX_BMC_HV  # _XIX_HochvoltBatterieManagement_XIX_SoC_XIX_BMC_HV_XIX_HochvoltEnergiemanagement_XIX_HVEM_XIX_HCP5_P2_OBD_Safety_XIX_BMC_MMTR_Status
    delegate HochvoltBatterieManagement_XIX_SoC_XIX_BMC_HV.SP_IF_BMC_MaxEnergieinhalt_XIX_HochvoltBatterieManagement_XIX_SoC_XIX_BMC_HV <-> outer port SP_IF_BMC_MaxEnergieinhalt_XIX_BMC_HV  # _XIX_HochvoltBatterieManagement_XIX_SoC_XIX_BMC_HV_XIX_ElectricTractionManagerReceive_XIX_FahrenBEV_XIX_HCP1_XIX_BMC_MaxEnergieinhalt
    delegate HochvoltBatterieManagement_XIX_SoC_XIX_BMC_HV.SP_IF_BMC_Max_Entladeleistung_XIX_HochvoltBatterieManagement_XIX_SoC_XIX_BMC_HV <-> outer port SP_IF_BMC_Max_Entladeleistung_XIX_BMC_HV  # _XIX_HochvoltBatterieManagement_XIX_SoC_XIX_BMC_HV_XIX_ElectricTractionManagerReceive_XIX_FahrenBEV_XIX_HCP1_XIX_BMC_Max_Entladeleistung
    delegate HochvoltBatterieManagement_XIX_SoC_XIX_BMC_HV.SP_IF_BMC_Max_Entladeleistung_02_XIX_HochvoltBatterieManagement_XIX_SoC_XIX_BMC_HV <-> outer port SP_IF_BMC_Max_Entladeleistung_02_XIX_BMC_HV  # _XIX_HochvoltBatterieManagement_XIX_SoC_XIX_BMC_HV_XIX_ElectricTractionManagerReceive_XIX_FahrenBEV_XIX_HCP1_XIX_BMC_Max_Entladeleistung_02
    delegate HochvoltBatterieManagement_XIX_SoC_XIX_BMC_HV.SP_IF_BMC_Max_Entladestrom_XIX_HochvoltBatterieManagement_XIX_SoC_XIX_BMC_HV <-> outer port SP_IF_BMC_Max_Entladestrom_XIX_BMC_HV  # _XIX_HochvoltBatterieManagement_XIX_SoC_XIX_BMC_HV_XIX_ElectricTractionManagerReceive_XIX_FahrenBEV_XIX_HCP1_XIX_BMC_Max_Entladestrom
    delegate HochvoltBatterieManagement_XIX_SoC_XIX_BMC_HV.SP_IF_BMC_Max_Entladestrom_02_XIX_HochvoltBatterieManagement_XIX_SoC_XIX_BMC_HV <-> outer port SP_IF_BMC_Max_Entladestrom_02_XIX_BMC_HV  # _XIX_HochvoltBatterieManagement_XIX_SoC_XIX_BMC_HV_XIX_ElectricTractionManagerReceive_XIX_FahrenBEV_XIX_HCP1_XIX_BMC_Max_Entladestrom_02
    delegate HochvoltBatterieManagement_XIX_SoC_XIX_BMC_HV.SP_IF_BMC_Max_Ladeleistung_XIX_HochvoltBatterieManagement_XIX_SoC_XIX_BMC_HV <-> outer port SP_IF_BMC_Max_Ladeleistung_XIX_BMC_HV  # _XIX_HochvoltBatterieManagement_XIX_SoC_XIX_BMC_HV_XIX_ElectricTractionManagerReceive_XIX_FahrenBEV_XIX_HCP1_XIX_BMC_Max_Ladeleistung
    delegate HochvoltBatterieManagement_XIX_SoC_XIX_BMC_HV.SP_IF_BMC_Max_Ladeleistung_02_XIX_HochvoltBatterieManagement_XIX_SoC_XIX_BMC_HV <-> outer port SP_IF_BMC_Max_Ladeleistung_02_XIX_BMC_HV  # _XIX_HochvoltBatterieManagement_XIX_SoC_XIX_BMC_HV_XIX_ElectricTractionManagerReceive_XIX_FahrenBEV_XIX_HCP1_XIX_BMC_Max_Ladeleistung_02
    delegate HochvoltBatterieManagement_XIX_SoC_XIX_BMC_HV.SP_IF_BMC_Max_Ladestrom_XIX_HochvoltBatterieManagement_XIX_SoC_XIX_BMC_HV <-> outer port SP_IF_BMC_Max_Ladestrom_XIX_BMC_HV  # _XIX_HochvoltBatterieManagement_XIX_SoC_XIX_BMC_HV_XIX_ElectricTractionManagerReceive_XIX_FahrenBEV_XIX_HCP1_XIX_BMC_Max_Ladestrom
    delegate HochvoltBatterieManagement_XIX_SoC_XIX_BMC_HV.SP_IF_BMC_Max_Ladestrom_02_XIX_HochvoltBatterieManagement_XIX_SoC_XIX_BMC_HV <-> outer port SP_IF_BMC_Max_Ladestrom_02_XIX_BMC_HV  # _XIX_HochvoltBatterieManagement_XIX_SoC_XIX_BMC_HV_XIX_ElectricTractionManagerReceive_XIX_FahrenBEV_XIX_HCP1_XIX_BMC_Max_Ladestrom_02
    delegate HochvoltBatterieManagement_XIX_SoC_XIX_BMC_HV.SP_IF_BMC_Max_Spannung_XIX_HochvoltBatterieManagement_XIX_SoC_XIX_BMC_HV <-> outer port SP_IF_BMC_Max_Spannung_XIX_BMC_HV  # _XIX_HochvoltBatterieManagement_XIX_SoC_XIX_BMC_HV_XIX_ElectricTractionManagerReceive_XIX_FahrenBEV_XIX_HCP1_XIX_BMC_Max_Spannung
    delegate HochvoltBatterieManagement_XIX_SoC_XIX_BMC_HV.SP_IF_BMC_MinDyn_Entladespannung_XIX_HochvoltBatterieManagement_XIX_SoC_XIX_BMC_HV <-> outer port SP_IF_BMC_MinDyn_Entladespannung_XIX_BMC_HV  # _XIX_HochvoltBatterieManagement_XIX_SoC_XIX_BMC_HV_XIX_ElectricTractionManagerReceive_XIX_FahrenBEV_XIX_HCP1_XIX_BMC_MinDyn_Entladespannung
    delegate HochvoltBatterieManagement_XIX_SoC_XIX_BMC_HV.SP_IF_BMC_MinDyn_Ladespannung_XIX_HochvoltBatterieManagement_XIX_SoC_XIX_BMC_HV <-> outer port SP_IF_BMC_MinDyn_Ladespannung_XIX_BMC_HV  # _XIX_HochvoltBatterieManagement_XIX_SoC_XIX_BMC_HV_XIX_ElectricTractionManagerReceive_XIX_FahrenBEV_XIX_HCP1_XIX_BMC_MinDyn_Ladespannung
    delegate HochvoltBatterieManagement_XIX_SoC_XIX_BMC_HV.SP_IF_BMC_Min_Spannung_XIX_HochvoltBatterieManagement_XIX_SoC_XIX_BMC_HV <-> outer port SP_IF_BMC_Min_Spannung_XIX_BMC_HV  # _XIX_HochvoltBatterieManagement_XIX_SoC_XIX_BMC_HV_XIX_ElectricTractionManagerReceive_XIX_FahrenBEV_XIX_HCP1_XIX_BMC_Min_Spannung
    delegate HochvoltBatterieManagement_XIX_SoC_XIX_BMC_HV.SP_IF_BMC_NutzbareKapazitaet_XIX_HochvoltBatterieManagement_XIX_SoC_XIX_BMC_HV <-> outer port SP_IF_BMC_NutzbareKapazitaet_XIX_BMC_HV  # _XIX_HochvoltBatterieManagement_XIX_SoC_XIX_BMC_HV_XIX_DrivingReflectionModule3p0_XIX_DRM_2_0_XIX_HCP5_P4_E3SWPAC_XIX_BMC_NutzbareKapazitaet
    delegate HochvoltBatterieManagement_XIX_SoC_XIX_BMC_HV.SP_IF_BMC_NutzbarerSOC_XIX_HochvoltBatterieManagement_XIX_SoC_XIX_BMC_HV <-> outer port SP_IF_BMC_NutzbarerSOC_XIX_BMC_HV
    delegate HochvoltBatterieManagement_XIX_SoC_XIX_BMC_HV.SP_IF_BMC_PCM_VTD_Freeze_Req_XIX_HochvoltBatterieManagement_XIX_SoC_XIX_BMC_HV <-> outer port SP_IF_BMC_PCM_VTD_Freeze_Req_XIX_BMC_HV
    delegate HochvoltBatterieManagement_XIX_SoC_XIX_BMC_HV.SP_IF_BMC_PCM_VTD_LifeTimeReset_Req_XIX_HochvoltBatterieManagement_XIX_SoC_XIX_BMC_HV <-> outer port SP_IF_BMC_PCM_VTD_LifeTimeReset_Req_XIX_BMC_HV
    delegate HochvoltBatterieManagement_XIX_SoC_XIX_BMC_HV.SP_IF_BMC_PCM_VTD_LifeTimeReset_Resp_XIX_HochvoltBatterieManagement_XIX_SoC_XIX_BMC_HV <-> outer port SP_IF_BMC_PCM_VTD_LifeTimeReset_Resp_XIX_BMC_HV
    delegate HochvoltBatterieManagement_XIX_SoC_XIX_BMC_HV.SP_IF_BMC_PCM_VTD_RecentReset_Req_XIX_HochvoltBatterieManagement_XIX_SoC_XIX_BMC_HV <-> outer port SP_IF_BMC_PCM_VTD_RecentReset_Req_XIX_BMC_HV
    delegate HochvoltBatterieManagement_XIX_SoC_XIX_BMC_HV.SP_IF_BMC_PerfInd_Entladen_XIX_HochvoltBatterieManagement_XIX_SoC_XIX_BMC_HV <-> outer port SP_IF_BMC_PerfInd_Entladen_XIX_BMC_HV  # _XIX_HochvoltBatterieManagement_XIX_SoC_XIX_BMC_HV_XIX_ElectricTractionManagerReceive_XIX_FahrenBEV_XIX_HCP1_XIX_BMC_PerfInd_Entladen
    delegate HochvoltBatterieManagement_XIX_SoC_XIX_BMC_HV.SP_IF_BMC_PerfInd_Laden_XIX_HochvoltBatterieManagement_XIX_SoC_XIX_BMC_HV <-> outer port SP_IF_BMC_PerfInd_Laden_XIX_BMC_HV  # _XIX_HochvoltBatterieManagement_XIX_SoC_XIX_BMC_HV_XIX_ElectricTractionManagerReceive_XIX_FahrenBEV_XIX_HCP1_XIX_BMC_PerfInd_Laden
    delegate HochvoltBatterieManagement_XIX_SoC_XIX_BMC_HV.SP_IF_BMC_PredLeistung_StuetzungNV_XIX_HochvoltBatterieManagement_XIX_SoC_XIX_BMC_HV <-> outer port SP_IF_BMC_PredLeistung_StuetzungNV_XIX_BMC_HV  # _XIX_HochvoltBatterieManagement_XIX_SoC_XIX_BMC_HV_XIX_HochvoltEnergiemanagement_XIX_HVEM_XIX_HCP5_P2_OBD_Safety_XIX_BMC_PredLeistung_StuetzungNV
    delegate HochvoltBatterieManagement_XIX_SoC_XIX_BMC_HV.SP_IF_BMC_Range_Indikator_XIX_HochvoltBatterieManagement_XIX_SoC_XIX_BMC_HV <-> outer port SP_IF_BMC_Range_Indikator_XIX_BMC_HV  # _XIX_HochvoltBatterieManagement_XIX_SoC_XIX_BMC_HV_XIX_CarMenues_XIX_UserInterface_XIX_HCP3_CN1_Systempartition_XIX_BMC_Range_Indikator
    delegate HochvoltBatterieManagement_XIX_SoC_XIX_BMC_HV.SP_IF_BMC_Rekuperation_XIX_HochvoltBatterieManagement_XIX_SoC_XIX_BMC_HV <-> outer port SP_IF_BMC_Rekuperation_XIX_BMC_HV  # _XIX_HochvoltBatterieManagement_XIX_SoC_XIX_BMC_HV_XIX_OnBoardComputerCalc_XIX_Bordcomputer_XIX_HCP3_CN1_Cluster_XIX_BMC_Rekuperation
    delegate HochvoltBatterieManagement_XIX_SoC_XIX_BMC_HV.SP_IF_BMC_Rekuperation_Ueberlauf_XIX_HochvoltBatterieManagement_XIX_SoC_XIX_BMC_HV <-> outer port SP_IF_BMC_Rekuperation_Ueberlauf_XIX_BMC_HV  # _XIX_HochvoltBatterieManagement_XIX_SoC_XIX_BMC_HV_XIX_OnBoardComputerCalc_XIX_Bordcomputer_XIX_HCP3_CN1_Cluster_XIX_BMC_Rekuperation_Ueberlauf
    delegate HochvoltBatterieManagement_XIX_SoC_XIX_BMC_HV.SP_IF_BMC_RuecklaufTemperatur_XIX_HochvoltBatterieManagement_XIX_SoC_XIX_BMC_HV <-> outer port SP_IF_BMC_RuecklaufTemperatur_XIX_BMC_HV
    delegate HochvoltBatterieManagement_XIX_SoC_XIX_BMC_HV.SP_IF_BMC_Spannung_XIX_HochvoltBatterieManagement_XIX_SoC_XIX_BMC_HV <-> outer port SP_IF_BMC_Spannung_XIX_BMC_HV
    delegate HochvoltBatterieManagement_XIX_SoC_XIX_BMC_HV.SP_IF_BMC_Spannung_DC_Ladesaeule_XIX_HochvoltBatterieManagement_XIX_SoC_XIX_BMC_HV <-> outer port SP_IF_BMC_Spannung_DC_Ladesaeule_XIX_BMC_HV
    delegate HochvoltBatterieManagement_XIX_SoC_XIX_BMC_HV.SP_IF_BMC_Spannung_ZwischenKreis_XIX_HochvoltBatterieManagement_XIX_SoC_XIX_BMC_HV <-> outer port SP_IF_BMC_Spannung_ZwischenKreis_XIX_BMC_HV  # _XIX_HochvoltBatterieManagement_XIX_SoC_XIX_BMC_HV_XIX_ElectricTractionManagerReceive_XIX_FahrenBEV_XIX_HCP1_XIX_BMC_Spannung_ZwischenKreis
    delegate HochvoltBatterieManagement_XIX_SoC_XIX_BMC_HV.SP_IF_BMC_Spannung_ZwischenKreis_2_XIX_HochvoltBatterieManagement_XIX_SoC_XIX_BMC_HV <-> outer port SP_IF_BMC_Spannung_ZwischenKreis_2_XIX_BMC_HV  # _XIX_HochvoltBatterieManagement_XIX_SoC_XIX_BMC_HV_XIX_ElectricTractionManagerReceive_XIX_FahrenBEV_XIX_HCP1_XIX_BMC_Spannung_ZwischenKreis_2
    delegate HochvoltBatterieManagement_XIX_SoC_XIX_BMC_HV.SP_IF_BMC_Status_DCLS_XIX_HochvoltBatterieManagement_XIX_SoC_XIX_BMC_HV <-> outer port SP_IF_BMC_Status_DCLS_XIX_BMC_HV
    delegate HochvoltBatterieManagement_XIX_SoC_XIX_BMC_HV.SP_IF_BMC_Strom_XIX_HochvoltBatterieManagement_XIX_SoC_XIX_BMC_HV <-> outer port SP_IF_BMC_Strom_XIX_BMC_HV
    delegate HochvoltBatterieManagement_XIX_SoC_XIX_BMC_HV.SP_IF_BMC_Strom_02_XIX_HochvoltBatterieManagement_XIX_SoC_XIX_BMC_HV <-> outer port SP_IF_BMC_Strom_02_XIX_BMC_HV
    delegate HochvoltBatterieManagement_XIX_SoC_XIX_BMC_HV.SP_IF_BMC_TechnischerSOC_XIX_HochvoltBatterieManagement_XIX_SoC_XIX_BMC_HV <-> outer port SP_IF_BMC_TechnischerSOC_XIX_BMC_HV
    delegate HochvoltBatterieManagement_XIX_SoC_XIX_BMC_HV.SP_IF_BMC_Temperatur_XIX_HochvoltBatterieManagement_XIX_SoC_XIX_BMC_HV <-> outer port SP_IF_BMC_Temperatur_XIX_BMC_HV  # _XIX_HochvoltBatterieManagement_XIX_SoC_XIX_BMC_HV_XIX_ChassisModeManager_XIX_Vertikaldynamikfunktionen_XIX_HCP1_XIX_BMC_Temperatur
    delegate HochvoltBatterieManagement_XIX_SoC_XIX_BMC_HV.SP_IF_BMC_ThermAuslastung_XIX_HochvoltBatterieManagement_XIX_SoC_XIX_BMC_HV <-> outer port SP_IF_BMC_ThermAuslastung_XIX_BMC_HV  # _XIX_HochvoltBatterieManagement_XIX_SoC_XIX_BMC_HV_XIX_ChassisModeManager_XIX_Vertikaldynamikfunktionen_XIX_HCP1_XIX_BMC_ThermAuslastung
    delegate HochvoltBatterieManagement_XIX_SoC_XIX_BMC_HV.SP_IF_BMC_ThermSpreizung_XIX_HochvoltBatterieManagement_XIX_SoC_XIX_BMC_HV <-> outer port SP_IF_BMC_ThermSpreizung_XIX_BMC_HV
    delegate HochvoltBatterieManagement_XIX_SoC_XIX_BMC_HV.SP_IF_BMC_UBE_Indik_last_update_km_XIX_HochvoltBatterieManagement_XIX_SoC_XIX_BMC_HV <-> outer port SP_IF_BMC_UBE_Indik_last_update_km_XIX_BMC_HV  # _XIX_HochvoltBatterieManagement_XIX_SoC_XIX_BMC_HV_XIX_CarMenues_XIX_UserInterface_XIX_HCP3_CN1_Systempartition_XIX_BMC_UBE_Indik_last_update_km
    delegate HochvoltBatterieManagement_XIX_SoC_XIX_BMC_HV.SP_IF_BMC_UBE_Indikator_XIX_HochvoltBatterieManagement_XIX_SoC_XIX_BMC_HV <-> outer port SP_IF_BMC_UBE_Indikator_XIX_BMC_HV  # _XIX_HochvoltBatterieManagement_XIX_SoC_XIX_BMC_HV_XIX_CarMenues_XIX_UserInterface_XIX_HCP3_CN1_Systempartition_XIX_BMC_UBE_Indikator
    delegate HochvoltBatterieManagement_XIX_SoC_XIX_BMC_HV.SP_IF_BMC_UI1_Spannung1_Schalt_Anf_XIX_HochvoltBatterieManagement_XIX_SoC_XIX_BMC_HV <-> outer port SP_IF_BMC_UI1_Spannung1_Schalt_Anf_XIX_BMC_HV
    delegate HochvoltBatterieManagement_XIX_SoC_XIX_BMC_HV.SP_IF_BMC_UI1_Spannung2_Schalt_Anf_XIX_HochvoltBatterieManagement_XIX_SoC_XIX_BMC_HV <-> outer port SP_IF_BMC_UI1_Spannung2_Schalt_Anf_XIX_BMC_HV
    delegate HochvoltBatterieManagement_XIX_SoC_XIX_BMC_HV.SP_IF_BMC_UI2_Spannung1_Schalt_Anf_XIX_HochvoltBatterieManagement_XIX_SoC_XIX_BMC_HV <-> outer port SP_IF_BMC_UI2_Spannung1_Schalt_Anf_XIX_BMC_HV
    delegate HochvoltBatterieManagement_XIX_SoC_XIX_BMC_HV.SP_IF_BMC_UI2_Spannung2_Schalt_Anf_XIX_HochvoltBatterieManagement_XIX_SoC_XIX_BMC_HV <-> outer port SP_IF_BMC_UI2_Spannung2_Schalt_Anf_XIX_BMC_HV
    delegate HochvoltBatterieManagement_XIX_SoC_XIX_BMC_HV.SP_IF_BMC_Unterboden_Warnung_XIX_HochvoltBatterieManagement_XIX_SoC_XIX_BMC_HV <-> outer port SP_IF_BMC_Unterboden_Warnung_XIX_BMC_HV  # _XIX_HochvoltBatterieManagement_XIX_SoC_XIX_BMC_HV_XIX_HighVoltageCoordinatorDiagnosis_XIX_HVFER_XIX_HCP5_P2_OBD_Safety_XIX_BMC_Unterboden_Warnung
    delegate HochvoltBatterieManagement_XIX_SoC_XIX_BMC_HV.SP_IF_BMC_Verbauinfo_ACSchuetz_XIX_HochvoltBatterieManagement_XIX_SoC_XIX_BMC_HV <-> outer port SP_IF_BMC_Verbauinfo_ACSchuetz_XIX_BMC_HV  # _XIX_HochvoltBatterieManagement_XIX_SoC_XIX_BMC_HV_XIX_HighVoltageCoordinatorControl_XIX_HVK_XIX_HCP5_P2_OBD_Safety_XIX_BMC_Verbauinfo_ACSchuetz
    delegate HochvoltBatterieManagement_XIX_SoC_XIX_BMC_HV.SP_IF_BMC_Verbauinfo_Bank_XIX_HochvoltBatterieManagement_XIX_SoC_XIX_BMC_HV <-> outer port SP_IF_BMC_Verbauinfo_Bank_XIX_BMC_HV  # _XIX_HochvoltBatterieManagement_XIX_SoC_XIX_BMC_HV_XIX_HighVoltageCoordinatorControl_XIX_HVK_XIX_HCP5_P2_OBD_Safety_XIX_BMC_Verbauinfo_Bank
    delegate HochvoltBatterieManagement_XIX_SoC_XIX_BMC_HV.SP_IF_BMC_Verbrauch_XIX_HochvoltBatterieManagement_XIX_SoC_XIX_BMC_HV <-> outer port SP_IF_BMC_Verbrauch_XIX_BMC_HV  # _XIX_HochvoltBatterieManagement_XIX_SoC_XIX_BMC_HV_XIX_OnBoardComputerCalc_XIX_Bordcomputer_XIX_HCP3_CN1_Cluster_XIX_BMC_Verbrauch
    delegate HochvoltBatterieManagement_XIX_SoC_XIX_BMC_HV.SP_IF_BMC_Verbrauch_Ueberlauf_XIX_HochvoltBatterieManagement_XIX_SoC_XIX_BMC_HV <-> outer port SP_IF_BMC_Verbrauch_Ueberlauf_XIX_BMC_HV  # _XIX_HochvoltBatterieManagement_XIX_SoC_XIX_BMC_HV_XIX_OnBoardComputerCalc_XIX_Bordcomputer_XIX_HCP3_CN1_Cluster_XIX_BMC_Verbrauch_Ueberlauf
    delegate HochvoltBatterieManagement_XIX_SoC_XIX_BMC_HV.SP_IF_BMC_VerlustEnergie_XIX_HochvoltBatterieManagement_XIX_SoC_XIX_BMC_HV <-> outer port SP_IF_BMC_VerlustEnergie_XIX_BMC_HV  # _XIX_HochvoltBatterieManagement_XIX_SoC_XIX_BMC_HV_XIX_ElectricTractionManagerReceive_XIX_FahrenBEV_XIX_HCP1_XIX_BMC_VerlustEnergie
    delegate HochvoltBatterieManagement_XIX_SoC_XIX_BMC_HV.SP_IF_BMC_VorlaufTemperatur_XIX_HochvoltBatterieManagement_XIX_SoC_XIX_BMC_HV <-> outer port SP_IF_BMC_VorlaufTemperatur_XIX_BMC_HV
    delegate HochvoltBatterieManagement_XIX_SoC_XIX_BMC_HV.SP_IF_BMC_ZellTemp_virtuell_max_XIX_HochvoltBatterieManagement_XIX_SoC_XIX_BMC_HV <-> outer port SP_IF_BMC_ZellTemp_virtuell_max_XIX_BMC_HV  # _XIX_HochvoltBatterieManagement_XIX_SoC_XIX_BMC_HV_XIX_HochvoltEnergiemanagement_XIX_HVEM_XIX_HCP5_P2_OBD_Safety_XIX_BMC_ZellTemp_virtuell_max
    delegate HochvoltBatterieManagement_XIX_SoC_XIX_BMC_HV.SP_IF_BMC_ZellTemp_virtuell_min_XIX_HochvoltBatterieManagement_XIX_SoC_XIX_BMC_HV <-> outer port SP_IF_BMC_ZellTemp_virtuell_min_XIX_BMC_HV  # _XIX_HochvoltBatterieManagement_XIX_SoC_XIX_BMC_HV_XIX_HochvoltEnergiemanagement_XIX_HVEM_XIX_HCP5_P2_OBD_Safety_XIX_BMC_ZellTemp_virtuell_min
    delegate HochvoltBatterieManagement_XIX_SoC_XIX_BMC_HV.RP_IF_HVEM_MMTR_State_XIX_HochvoltBatterieManagement_XIX_SoC_XIX_BMC_HV <-> outer port RP_IF_HVEM_MMTR_State_XIX_BMC_HV  # _XIX_HochvoltEnergiemanagement_XIX_HVEM_XIX_HCP5_P2_OBD_Safety_XIX_HochvoltBatterieManagement_XIX_SoC_XIX_BMC_HV_XIX_HVEM_MMTR_State
    delegate HochvoltBatterieManagement_XIX_SoC_XIX_BMC_HV.RP_IF_HVEM_BMC_CHA_Wunschleistung_XIX_HochvoltBatterieManagement_XIX_SoC_XIX_BMC_HV <-> outer port RP_IF_HVEM_BMC_CHA_Wunschleistung_XIX_BMC_HV  # _XIX_HochvoltEnergiemanagement_XIX_HVEM_XIX_HCP5_P2_OBD_Safety_XIX_HochvoltBatterieManagement_XIX_SoC_XIX_BMC_HV_XIX_HVEM_BMC_CHA_Wunschleistung
    delegate HochvoltBatterieManagement_XIX_SoC_XIX_BMC_HV.RP_IF_HVEM_BMC_CHA_Wunschleistung_02_XIX_HochvoltBatterieManagement_XIX_SoC_XIX_BMC_HV <-> outer port RP_IF_HVEM_BMC_CHA_Wunschleistung_02_XIX_BMC_HV  # _XIX_HochvoltEnergiemanagement_XIX_HVEM_XIX_HCP5_P2_OBD_Safety_XIX_HochvoltBatterieManagement_XIX_SoC_XIX_BMC_HV_XIX_HVEM_BMC_CHA_Wunschleistung_02
    delegate HochvoltBatterieManagement_XIX_SoC_XIX_BMC_HV.RP_IF_HVEM_SystemMinLeistungsgrenze_XIX_HochvoltBatterieManagement_XIX_SoC_XIX_BMC_HV <-> outer port RP_IF_HVEM_SystemMinLeistungsgrenze_XIX_BMC_HV  # _XIX_HochvoltEnergiemanagement_XIX_HVEM_XIX_HCP5_P2_OBD_Safety_XIX_HochvoltBatterieManagement_XIX_SoC_XIX_BMC_HV_XIX_HVEM_SystemMinLeistungsgrenze
    delegate BMC_HVS_Slave_XIX_SoC_XIX_BMC_HV.RP_IF_SG_HVK_03_XIX_BMC_HVS_Slave_XIX_SoC_XIX_BMC_HV <-> outer port RP_IF_SG_HVK_03_XIX_BMC_HV
    delegate HochvoltBatterieManagement_XIX_SoC_XIX_BMC_HV.RP_IF_SG_UI1_01_XIX_HochvoltBatterieManagement_XIX_SoC_XIX_BMC_HV <-> outer port RP_IF_SG_UI1_01_XIX_BMC_HV
    delegate HochvoltBatterieManagement_XIX_SoC_XIX_BMC_HV.RP_IF_SG_UI1_02_XIX_HochvoltBatterieManagement_XIX_SoC_XIX_BMC_HV <-> outer port RP_IF_SG_UI1_02_XIX_BMC_HV
    delegate HochvoltBatterieManagement_XIX_SoC_XIX_BMC_HV.RP_IF_UI1_Spannung{4..6}_XIX_HochvoltBatterieManagement_XIX_SoC_XIX_BMC_HV <-> outer port RP_IF_UI1_Spannung{4..6}_XIX_BMC_HV
    delegate HochvoltBatterieManagement_XIX_SoC_XIX_BMC_HV.RP_IF_UI1_Status_XIX_HochvoltBatterieManagement_XIX_SoC_XIX_BMC_HV <-> outer port RP_IF_UI1_Status_XIX_BMC_HV
    delegate HochvoltBatterieManagement_XIX_SoC_XIX_BMC_HV.RP_IF_UI1_Iso_Neg_XIX_HochvoltBatterieManagement_XIX_SoC_XIX_BMC_HV <-> outer port RP_IF_UI1_Iso_Neg_XIX_BMC_HV
    delegate HochvoltBatterieManagement_XIX_SoC_XIX_BMC_HV.RP_IF_UI1_Iso_Pos_XIX_HochvoltBatterieManagement_XIX_SoC_XIX_BMC_HV <-> outer port RP_IF_UI1_Iso_Pos_XIX_BMC_HV
    delegate HochvoltBatterieManagement_XIX_SoC_XIX_BMC_HV.RP_IF_UI1_Iso_Status_XIX_HochvoltBatterieManagement_XIX_SoC_XIX_BMC_HV <-> outer port RP_IF_UI1_Iso_Status_XIX_BMC_HV
    delegate HochvoltBatterieManagement_XIX_SoC_XIX_BMC_HV.RP_IF_UI1_KompFehlerModus2_{01..26}_XIX_HochvoltBatterieManagement_XIX_SoC_XIX_BMC_HV <-> outer port RP_IF_UI1_KompFehlerModus2_{01..26}_XIX_BMC_HV
    delegate HochvoltBatterieManagement_XIX_SoC_XIX_BMC_HV.RP_IF_UI1_KompFehlerModus4_{01..16}_XIX_HochvoltBatterieManagement_XIX_SoC_XIX_BMC_HV <-> outer port RP_IF_UI1_KompFehlerModus4_{01..16}_XIX_BMC_HV
    delegate HochvoltBatterieManagement_XIX_SoC_XIX_BMC_HV.RP_IF_UI1_Stromintegral_Entladen_XIX_HochvoltBatterieManagement_XIX_SoC_XIX_BMC_HV <-> outer port RP_IF_UI1_Stromintegral_Entladen_XIX_BMC_HV
    delegate HochvoltBatterieManagement_XIX_SoC_XIX_BMC_HV.RP_IF_UI1_Stromintegral_Laden_XIX_HochvoltBatterieManagement_XIX_SoC_XIX_BMC_HV <-> outer port RP_IF_UI1_Stromintegral_Laden_XIX_BMC_HV
    delegate HochvoltBatterieManagement_XIX_SoC_XIX_BMC_HV.RP_IF_UI1_Temperatur_1_XIX_HochvoltBatterieManagement_XIX_SoC_XIX_BMC_HV <-> outer port RP_IF_UI1_Temperatur_1_XIX_BMC_HV
    delegate HochvoltBatterieManagement_XIX_SoC_XIX_BMC_HV.RP_IF_UI1_Temperatur_2_XIX_HochvoltBatterieManagement_XIX_SoC_XIX_BMC_HV <-> outer port RP_IF_UI1_Temperatur_2_XIX_BMC_HV
    delegate HochvoltBatterieManagement_XIX_SoC_XIX_BMC_HV.RP_IF_SG_UI2_03_XIX_HochvoltBatterieManagement_XIX_SoC_XIX_BMC_HV <-> outer port RP_IF_SG_UI2_03_XIX_BMC_HV
    delegate HochvoltBatterieManagement_XIX_SoC_XIX_BMC_HV.RP_IF_SG_UI2_01_XIX_HochvoltBatterieManagement_XIX_SoC_XIX_BMC_HV <-> outer port RP_IF_SG_UI2_01_XIX_BMC_HV
    delegate HochvoltBatterieManagement_XIX_SoC_XIX_BMC_HV.RP_IF_UI2_KompFehlerModus2_{01..26}_XIX_HochvoltBatterieManagement_XIX_SoC_XIX_BMC_HV <-> outer port RP_IF_UI2_KompFehlerModus2_{01..26}_XIX_BMC_HV
    delegate HochvoltBatterieManagement_XIX_SoC_XIX_BMC_HV.RP_IF_UI2_KompFehlerModus4_{01..16}_XIX_HochvoltBatterieManagement_XIX_SoC_XIX_BMC_HV <-> outer port RP_IF_UI2_KompFehlerModus4_{01..16}_XIX_BMC_HV
    delegate HochvoltBatterieManagement_XIX_SoC_XIX_BMC_HV.RP_IF_SG_UI2_02_XIX_HochvoltBatterieManagement_XIX_SoC_XIX_BMC_HV <-> outer port RP_IF_SG_UI2_02_XIX_BMC_HV
    delegate HochvoltBatterieManagement_XIX_SoC_XIX_BMC_HV.RP_IF_UI2_Status_XIX_HochvoltBatterieManagement_XIX_SoC_XIX_BMC_HV <-> outer port RP_IF_UI2_Status_XIX_BMC_HV
    delegate HochvoltBatterieManagement_XIX_SoC_XIX_BMC_HV.RP_IF_UI2_Stromintegral_Entladen_XIX_HochvoltBatterieManagement_XIX_SoC_XIX_BMC_HV <-> outer port RP_IF_UI2_Stromintegral_Entladen_XIX_BMC_HV
    delegate HochvoltBatterieManagement_XIX_SoC_XIX_BMC_HV.RP_IF_UI2_Stromintegral_Laden_XIX_HochvoltBatterieManagement_XIX_SoC_XIX_BMC_HV <-> outer port RP_IF_UI2_Stromintegral_Laden_XIX_BMC_HV
    delegate HochvoltBatterieManagement_XIX_SoC_XIX_BMC_HV.RP_IF_UI2_Temperatur_1_XIX_HochvoltBatterieManagement_XIX_SoC_XIX_BMC_HV <-> outer port RP_IF_UI2_Temperatur_1_XIX_BMC_HV
    delegate HochvoltBatterieManagement_XIX_SoC_XIX_BMC_HV.RP_IF_UI2_Temperatur_2_XIX_HochvoltBatterieManagement_XIX_SoC_XIX_BMC_HV <-> outer port RP_IF_UI2_Temperatur_2_XIX_BMC_HV
    delegate VKMS_Participant_BMC_HV_XIX_VKMS_XIX_BMC_HV.RP_IF_VIN_1_XIX_VKMS_Participant_BMC_HV_XIX_VKMS_XIX_BMC_HV <-> outer port RP_IF_VIN_1_XIX_BMC_HV
    delegate VKMS_Participant_BMC_HV_XIX_VKMS_XIX_BMC_HV.RP_IF_VIN_{10..17}_XIX_VKMS_Participant_BMC_HV_XIX_VKMS_XIX_BMC_HV <-> outer port RP_IF_VIN_{10..17}_XIX_BMC_HV
    delegate VKMS_Participant_BMC_HV_XIX_VKMS_XIX_BMC_HV.RP_IF_VIN_{2..9}_XIX_VKMS_Participant_BMC_HV_XIX_VKMS_XIX_BMC_HV <-> outer port RP_IF_VIN_{2..9}_XIX_BMC_HV
    delegate Infrastructure_Hybrid_01_XIX_network_infrastructure_XIX_BMC_HV.RP_IF_NM_AWC_FCAB_XIX_Infrastructure_Hybrid_01_XIX_network_infrastructure_XIX_BMC_HV <-> outer port RP_IF_NM_AWC_FCAB_XIX_BMC_HV  # _XIX_Infrastructure_AWC_XIX_network_infrastructure_XIX_AWC_XIX_Infrastructure_Hybrid_01_XIX_network_infrastructure_XIX_BMC_HV_XIX_NM_AWC_FCAB
    delegate Infrastructure_Hybrid_01_XIX_network_infrastructure_XIX_BMC_HV.RP_IF_NM_Gateway_FCAB_XIX_Infrastructure_Hybrid_01_XIX_network_infrastructure_XIX_BMC_HV <-> outer port RP_IF_NM_Gateway_FCAB_XIX_BMC_HV  # _XIX_Infrastructure_Gateway_XIX_network_infrastructure_XIX_HCP5_P1_Gateway_XIX_Infrastructure_Hybrid_01_XIX_network_infrastructure_XIX_BMC_HV_XIX_NM_Gateway_FCAB
    delegate Infrastructure_Hybrid_01_XIX_network_infrastructure_XIX_BMC_HV.RP_IF_NM_HVZB_FCAB_XIX_Infrastructure_Hybrid_01_XIX_network_infrastructure_XIX_BMC_HV <-> outer port RP_IF_NM_HVZB_FCAB_XIX_BMC_HV  # _XIX_Infrastructure_HVZB_XIX_network_infrastructure_XIX_IPB_XIX_Infrastructure_Hybrid_01_XIX_network_infrastructure_XIX_BMC_HV_XIX_NM_HVZB_FCAB
    delegate Infrastructure_Hybrid_01_XIX_network_infrastructure_XIX_BMC_HV.SP_IF_DS_Hybrid_01_Lokalaktiv_XIX_Infrastructure_Hybrid_01_XIX_network_infrastructure_XIX_BMC_HV <-> outer port SP_IF_DS_Hybrid_01_Lokalaktiv_XIX_BMC_HV  # _XIX_Infrastructure_Hybrid_01_XIX_network_infrastructure_XIX_BMC_HV_XIX_RSM_Generierung_XIX_NVEV_Basis_XIX_HCP5_P2_OBD_Safety_XIX_DS_Hybrid_01_Lokalaktiv
    delegate Infrastructure_Hybrid_01_XIX_network_infrastructure_XIX_BMC_HV.SP_IF_DS_Hybrid_01_Subsystemaktiv_XIX_Infrastructure_Hybrid_01_XIX_network_infrastructure_XIX_BMC_HV <-> outer port SP_IF_DS_Hybrid_01_Subsystemaktiv_XIX_BMC_HV  # _XIX_Infrastructure_Hybrid_01_XIX_network_infrastructure_XIX_BMC_HV_XIX_RSM_Generierung_XIX_NVEV_Basis_XIX_HCP5_P2_OBD_Safety_XIX_DS_Hybrid_01_Subsystemaktiv
    delegate Infrastructure_Hybrid_01_XIX_network_infrastructure_XIX_BMC_HV.SP_IF_Hybrid_01_Nachlauftyp_XIX_Infrastructure_Hybrid_01_XIX_network_infrastructure_XIX_BMC_HV <-> outer port SP_IF_Hybrid_01_Nachlauftyp_XIX_BMC_HV  # _XIX_Infrastructure_Hybrid_01_XIX_network_infrastructure_XIX_BMC_HV_XIX_Infrastructure_Gateway_XIX_network_infrastructure_XIX_HCP5_P1_Gateway_XIX_Hybrid_01_Nachlauftyp
    delegate Infrastructure_Hybrid_01_XIX_network_infrastructure_XIX_BMC_HV.SP_IF_NM_Hybrid_01_CAB_V12_XIX_Infrastructure_Hybrid_01_XIX_network_infrastructure_XIX_BMC_HV <-> outer port SP_IF_NM_Hybrid_01_CAB_V12_XIX_BMC_HV  # _XIX_Infrastructure_Hybrid_01_XIX_network_infrastructure_XIX_BMC_HV_XIX_Infrastructure_BJB_XIX_network_infrastructure_XIX_BJB_2_XIX_NM_Hybrid_01_CAB_V12
    delegate Infrastructure_Hybrid_01_XIX_network_infrastructure_XIX_BMC_HV.SP_IF_NM_Hybrid_01_CBV_AWB_XIX_Infrastructure_Hybrid_01_XIX_network_infrastructure_XIX_BMC_HV <-> outer port SP_IF_NM_Hybrid_01_CBV_AWB_XIX_BMC_HV  # _XIX_Infrastructure_Hybrid_01_XIX_network_infrastructure_XIX_BMC_HV_XIX_WUM_Client5_XIX_WUM_XIX_HCP5_P1_Gateway_XIX_NM_Hybrid_01_CBV_AWB
    delegate Infrastructure_Hybrid_01_XIX_network_infrastructure_XIX_BMC_HV.SP_IF_NM_Hybrid_01_FCAB_XIX_Infrastructure_Hybrid_01_XIX_network_infrastructure_XIX_BMC_HV <-> outer port SP_IF_NM_Hybrid_01_FCAB_XIX_BMC_HV  # _XIX_Infrastructure_Hybrid_01_XIX_network_infrastructure_XIX_BMC_HV_XIX_Infrastructure_AWC_XIX_network_infrastructure_XIX_AWC_XIX_NM_Hybrid_01_FCAB
    delegate Infrastructure_Hybrid_01_XIX_network_infrastructure_XIX_BMC_HV.SP_IF_NM_Hybrid_01_FCIB_XIX_Infrastructure_Hybrid_01_XIX_network_infrastructure_XIX_BMC_HV <-> outer port SP_IF_NM_Hybrid_01_FCIB_XIX_BMC_HV  # _XIX_Infrastructure_Hybrid_01_XIX_network_infrastructure_XIX_BMC_HV_XIX_VNSM5_1_XIX_WUSL_XIX_HCP5_P1_Gateway_XIX_NM_Hybrid_01_FCIB
    delegate Infrastructure_Hybrid_01_XIX_network_infrastructure_XIX_BMC_HV.SP_IF_NM_Hybrid_01_NM_State_XIX_Infrastructure_Hybrid_01_XIX_network_infrastructure_XIX_BMC_HV <-> outer port SP_IF_NM_Hybrid_01_NM_State_XIX_BMC_HV  # _XIX_Infrastructure_Hybrid_01_XIX_network_infrastructure_XIX_BMC_HV_XIX_Infrastructure_BJB_XIX_network_infrastructure_XIX_BJB_2_XIX_NM_Hybrid_01_NM_State
    delegate Infrastructure_Hybrid_01_XIX_network_infrastructure_XIX_BMC_HV.SP_IF_NM_Hybrid_01_SNI_10_XIX_Infrastructure_Hybrid_01_XIX_network_infrastructure_XIX_BMC_HV <-> outer port SP_IF_NM_Hybrid_01_SNI_10_XIX_BMC_HV  # _XIX_Infrastructure_Hybrid_01_XIX_network_infrastructure_XIX_BMC_HV_XIX_WUM_Client5_XIX_WUM_XIX_HCP5_P1_Gateway_XIX_NM_Hybrid_01_SNI_10
    delegate Infrastructure_Hybrid_01_XIX_network_infrastructure_XIX_BMC_HV.RP_IF_NM_Ladegeraet_FCAB_XIX_Infrastructure_Hybrid_01_XIX_network_infrastructure_XIX_BMC_HV <-> outer port RP_IF_NM_Ladegeraet_FCAB_XIX_BMC_HV  # _XIX_Infrastructure_Ladegeraet_XIX_network_infrastructure_XIX_SAC_XIX_Infrastructure_Hybrid_01_XIX_network_infrastructure_XIX_BMC_HV_XIX_NM_Ladegeraet_FCAB
    delegate Infrastructure_Hybrid_01_XIX_network_infrastructure_XIX_BMC_HV.RP_IF_NM_SACID_1_FCAB_XIX_Infrastructure_Hybrid_01_XIX_network_infrastructure_XIX_BMC_HV <-> outer port RP_IF_NM_SACID_1_FCAB_XIX_BMC_HV  # _XIX_Infrastructure_SACID_1_XIX_network_infrastructure_XIX_SACID_1_Primary_XIX_Infrastructure_Hybrid_01_XIX_network_infrastructure_XIX_BMC_HV_XIX_NM_SACID_1_FCAB
    delegate Infrastructure_Hybrid_01_XIX_network_infrastructure_XIX_BMC_HV.RP_IF_NM_SACID_2_FCAB_XIX_Infrastructure_Hybrid_01_XIX_network_infrastructure_XIX_BMC_HV <-> outer port RP_IF_NM_SACID_2_FCAB_XIX_BMC_HV  # _XIX_Infrastructure_SACID_2_XIX_network_infrastructure_XIX_SACID_2_Primary_XIX_Infrastructure_Hybrid_01_XIX_network_infrastructure_XIX_BMC_HV_XIX_NM_SACID_2_FCAB
    delegate KS_BMC_HV_XIX_KSGen3_XIX_BMC_HV.SP_IF_KS_Hybrid_01_ChK_XIX_KS_BMC_HV_XIX_KSGen3_XIX_BMC_HV <-> outer port SP_IF_KS_Hybrid_01_ChK_XIX_BMC_HV
    delegate KS_BMC_HV_XIX_KSGen3_XIX_BMC_HV.SP_IF_KS_Hybrid_01_ChK_IKACtr_XIX_KS_BMC_HV_XIX_KSGen3_XIX_BMC_HV <-> outer port SP_IF_KS_Hybrid_01_ChK_IKACtr_XIX_BMC_HV
    delegate KS_BMC_HV_XIX_KSGen3_XIX_BMC_HV.SP_IF_KS_Hybrid_01_ChK_SID_XIX_KS_BMC_HV_XIX_KSGen3_XIX_BMC_HV <-> outer port SP_IF_KS_Hybrid_01_ChK_SID_XIX_BMC_HV
    delegate KS_BMC_HV_XIX_KSGen3_XIX_BMC_HV.SP_IF_KS_Hybrid_01_ReK_XIX_KS_BMC_HV_XIX_KSGen3_XIX_BMC_HV <-> outer port SP_IF_KS_Hybrid_01_ReK_XIX_BMC_HV
    delegate KS_BMC_HV_XIX_KSGen3_XIX_BMC_HV.SP_IF_KS_Hybrid_01_ReK_IKACtr_XIX_KS_BMC_HV_XIX_KSGen3_XIX_BMC_HV <-> outer port SP_IF_KS_Hybrid_01_ReK_IKACtr_XIX_BMC_HV
    delegate KS_BMC_HV_XIX_KSGen3_XIX_BMC_HV.SP_IF_KS_Hybrid_01_ReK_SID_XIX_KS_BMC_HV_XIX_KSGen3_XIX_BMC_HV <-> outer port SP_IF_KS_Hybrid_01_ReK_SID_XIX_BMC_HV
    delegate KS_BMC_HV_XIX_KSGen3_XIX_BMC_HV.SP_IF_KS_Hybrid_01_Req_ErrCtr_XIX_KS_BMC_HV_XIX_KSGen3_XIX_BMC_HV <-> outer port SP_IF_KS_Hybrid_01_Req_ErrCtr_XIX_BMC_HV
    delegate KS_BMC_HV_XIX_KSGen3_XIX_BMC_HV.SP_IF_KS_Hybrid_01_Req_IKA_Retry_XIX_KS_BMC_HV_XIX_KSGen3_XIX_BMC_HV <-> outer port SP_IF_KS_Hybrid_01_Req_IKA_Retry_XIX_BMC_HV
    delegate KS_BMC_HV_XIX_KSGen3_XIX_BMC_HV.SP_IF_KS_Hybrid_01_Req_Prio_XIX_KS_BMC_HV_XIX_KSGen3_XIX_BMC_HV <-> outer port SP_IF_KS_Hybrid_01_Req_Prio_XIX_BMC_HV
    delegate KS_BMC_HV_XIX_KSGen3_XIX_BMC_HV.SP_IF_KS_Hybrid_01_Req_SID_XIX_KS_BMC_HV_XIX_KSGen3_XIX_BMC_HV <-> outer port SP_IF_KS_Hybrid_01_Req_SID_XIX_BMC_HV
    delegate KS_BMC_HV_XIX_KSGen3_XIX_BMC_HV.SP_IF_KS_Hybrid_01_Req_SWMaj_XIX_KS_BMC_HV_XIX_KSGen3_XIX_BMC_HV <-> outer port SP_IF_KS_Hybrid_01_Req_SWMaj_XIX_BMC_HV
    delegate KS_BMC_HV_XIX_KSGen3_XIX_BMC_HV.SP_IF_KS_Hybrid_01_Req_SWMin_XIX_KS_BMC_HV_XIX_KSGen3_XIX_BMC_HV <-> outer port SP_IF_KS_Hybrid_01_Req_SWMin_XIX_BMC_HV
    delegate KS_BMC_HV_XIX_KSGen3_XIX_BMC_HV.SP_IF_KS_Hybrid_01_Req_SWPat_XIX_KS_BMC_HV_XIX_KSGen3_XIX_BMC_HV <-> outer port SP_IF_KS_Hybrid_01_Req_SWPat_XIX_BMC_HV
    delegate KS_BMC_HV_XIX_KSGen3_XIX_BMC_HV.SP_IF_KS_Hybrid_01_Req_VKMS_Err_XIX_KS_BMC_HV_XIX_KSGen3_XIX_BMC_HV <-> outer port SP_IF_KS_Hybrid_01_Req_VKMS_Err_XIX_BMC_HV
    delegate HochvoltBatterieManagement_XIX_SoC_XIX_BMC_HV.RP_IF_PCM_BMC_VTD_Freeze_Req_XIX_HochvoltBatterieManagement_XIX_SoC_XIX_BMC_HV <-> outer port RP_IF_PCM_BMC_VTD_Freeze_Req_XIX_BMC_HV
    delegate HochvoltBatterieManagement_XIX_SoC_XIX_BMC_HV.RP_IF_PCM_BMC_VTD_LifeTimeReset_Req_XIX_HochvoltBatterieManagement_XIX_SoC_XIX_BMC_HV <-> outer port RP_IF_PCM_BMC_VTD_LifeTimeReset_Req_XIX_BMC_HV
    delegate HochvoltBatterieManagement_XIX_SoC_XIX_BMC_HV.RP_IF_PCM_BMC_VTD_LifeTimeReset_Resp_XIX_HochvoltBatterieManagement_XIX_SoC_XIX_BMC_HV <-> outer port RP_IF_PCM_BMC_VTD_LifeTimeReset_Resp_XIX_BMC_HV
    delegate HochvoltBatterieManagement_XIX_SoC_XIX_BMC_HV.RP_IF_PCM_BMC_VTD_RecentReset_Req_XIX_HochvoltBatterieManagement_XIX_SoC_XIX_BMC_HV <-> outer port RP_IF_PCM_BMC_VTD_RecentReset_Req_XIX_BMC_HV
    delegate diagnosis_infrastructure_Hybrid_01_XIX_diagnosis_infrastructure_XIX_BMC_HV.RP_IF_OBDProtocol_req_XIX_diagnosis_infrastructure_Hybrid_01_XIX_diagnosis_infrastructure_XIX_BMC_HV <-> outer port RP_IF_OBDProtocol_req_XIX_BMC_HV  # _XIX_MIL_Master_XIX_OBD_XIX_HCP1_XIX_diagnosis_infrastructure_Hybrid_01_XIX_diagnosis_infrastructure_XIX_BMC_HV_XIX_OBDProtocol_req
    delegate diagnosis_infrastructure_Hybrid_01_XIX_diagnosis_infrastructure_XIX_BMC_HV.RP_IF_OBD_Engine_RPM_XIX_diagnosis_infrastructure_Hybrid_01_XIX_diagnosis_infrastructure_XIX_BMC_HV <-> outer port RP_IF_OBD_Engine_RPM_XIX_BMC_HV  # _XIX_MIL_Master_XIX_OBD_XIX_HCP1_XIX_diagnosis_infrastructure_Hybrid_01_XIX_diagnosis_infrastructure_XIX_BMC_HV_XIX_OBD_Engine_RPM
    delegate diagnosis_infrastructure_Hybrid_01_XIX_diagnosis_infrastructure_XIX_BMC_HV.RP_IF_OBD_Calc_Load_Val_XIX_diagnosis_infrastructure_Hybrid_01_XIX_diagnosis_infrastructure_XIX_BMC_HV <-> outer port RP_IF_OBD_Calc_Load_Val_XIX_BMC_HV  # _XIX_MIL_Master_XIX_OBD_XIX_HCP1_XIX_diagnosis_infrastructure_Hybrid_01_XIX_diagnosis_infrastructure_XIX_BMC_HV_XIX_OBD_Calc_Load_Val
    delegate diagnosis_infrastructure_Hybrid_01_XIX_diagnosis_infrastructure_XIX_BMC_HV.RP_IF_OBD_NumDcyMilOnReq_XIX_diagnosis_infrastructure_Hybrid_01_XIX_diagnosis_infrastructure_XIX_BMC_HV <-> outer port RP_IF_OBD_NumDcyMilOnReq_XIX_BMC_HV  # _XIX_MIL_Master_XIX_OBD_XIX_HCP1_XIX_diagnosis_infrastructure_Hybrid_01_XIX_diagnosis_infrastructure_XIX_BMC_HV_XIX_OBD_NumDcyMilOnReq
    delegate diagnosis_infrastructure_Hybrid_01_XIX_diagnosis_infrastructure_XIX_BMC_HV.RP_IF_OBD_Driving_Cycle_XIX_diagnosis_infrastructure_Hybrid_01_XIX_diagnosis_infrastructure_XIX_BMC_HV <-> outer port RP_IF_OBD_Driving_Cycle_XIX_BMC_HV  # _XIX_MIL_Master_XIX_OBD_XIX_HCP1_XIX_diagnosis_infrastructure_Hybrid_01_XIX_diagnosis_infrastructure_XIX_BMC_HV_XIX_OBD_Driving_Cycle
    delegate diagnosis_infrastructure_Hybrid_01_XIX_diagnosis_infrastructure_XIX_BMC_HV.RP_IF_OBD_QBit_Aussen_Temp_XIX_diagnosis_infrastructure_Hybrid_01_XIX_diagnosis_infrastructure_XIX_BMC_HV <-> outer port RP_IF_OBD_QBit_Aussen_Temp_XIX_BMC_HV  # _XIX_MIL_Master_XIX_OBD_XIX_HCP1_XIX_diagnosis_infrastructure_Hybrid_01_XIX_diagnosis_infrastructure_XIX_BMC_HV_XIX_OBD_QBit_Aussen_Temp
    delegate diagnosis_infrastructure_Hybrid_01_XIX_diagnosis_infrastructure_XIX_BMC_HV.RP_IF_MM_PropulsionSystemActive_XIX_diagnosis_infrastructure_Hybrid_01_XIX_diagnosis_infrastructure_XIX_BMC_HV <-> outer port RP_IF_MM_PropulsionSystemActive_XIX_BMC_HV  # _XIX_MIL_Master_XIX_OBD_XIX_HCP1_XIX_diagnosis_infrastructure_Hybrid_01_XIX_diagnosis_infrastructure_XIX_BMC_HV_XIX_MM_PropulsionSystemActive
    delegate diagnosis_infrastructure_Hybrid_01_XIX_diagnosis_infrastructure_XIX_BMC_HV.RP_IF_OBD_Minimum_Trip_XIX_diagnosis_infrastructure_Hybrid_01_XIX_diagnosis_infrastructure_XIX_BMC_HV <-> outer port RP_IF_OBD_Minimum_Trip_XIX_BMC_HV  # _XIX_MIL_Master_XIX_OBD_XIX_HCP1_XIX_diagnosis_infrastructure_Hybrid_01_XIX_diagnosis_infrastructure_XIX_BMC_HV_XIX_OBD_Minimum_Trip
    delegate diagnosis_infrastructure_Hybrid_01_XIX_diagnosis_infrastructure_XIX_BMC_HV.RP_IF_OBD_Normed_Trip_XIX_diagnosis_infrastructure_Hybrid_01_XIX_diagnosis_infrastructure_XIX_BMC_HV <-> outer port RP_IF_OBD_Normed_Trip_XIX_BMC_HV  # _XIX_MIL_Master_XIX_OBD_XIX_HCP1_XIX_diagnosis_infrastructure_Hybrid_01_XIX_diagnosis_infrastructure_XIX_BMC_HV_XIX_OBD_Normed_Trip
    delegate diagnosis_infrastructure_Hybrid_01_XIX_diagnosis_infrastructure_XIX_BMC_HV.RP_IF_OBD_Sperrung_Kaltstart_Denom_XIX_diagnosis_infrastructure_Hybrid_01_XIX_diagnosis_infrastructure_XIX_BMC_HV <-> outer port RP_IF_OBD_Sperrung_Kaltstart_Denom_XIX_BMC_HV  # _XIX_MIL_Master_XIX_OBD_XIX_HCP1_XIX_diagnosis_infrastructure_Hybrid_01_XIX_diagnosis_infrastructure_XIX_BMC_HV_XIX_OBD_Sperrung_Kaltstart_Denom
    delegate diagnosis_infrastructure_Hybrid_01_XIX_diagnosis_infrastructure_XIX_BMC_HV.RP_IF_OBD_Warm_Up_Cycle_XIX_diagnosis_infrastructure_Hybrid_01_XIX_diagnosis_infrastructure_XIX_BMC_HV <-> outer port RP_IF_OBD_Warm_Up_Cycle_XIX_BMC_HV  # _XIX_MIL_Master_XIX_OBD_XIX_HCP1_XIX_diagnosis_infrastructure_Hybrid_01_XIX_diagnosis_infrastructure_XIX_BMC_HV_XIX_OBD_Warm_Up_Cycle
    delegate diagnosis_infrastructure_Hybrid_01_XIX_diagnosis_infrastructure_XIX_BMC_HV.RP_IF_OBD_Eng_Cool_Temp_XIX_diagnosis_infrastructure_Hybrid_01_XIX_diagnosis_infrastructure_XIX_BMC_HV <-> outer port RP_IF_OBD_Eng_Cool_Temp_XIX_BMC_HV  # _XIX_MIL_Master_XIX_OBD_XIX_HCP1_XIX_diagnosis_infrastructure_Hybrid_01_XIX_diagnosis_infrastructure_XIX_BMC_HV_XIX_OBD_Eng_Cool_Temp
    delegate diagnosis_infrastructure_Hybrid_01_XIX_diagnosis_infrastructure_XIX_BMC_HV.RP_IF_OBD_Abs_Pedal_Pos_XIX_diagnosis_infrastructure_Hybrid_01_XIX_diagnosis_infrastructure_XIX_BMC_HV <-> outer port RP_IF_OBD_Abs_Pedal_Pos_XIX_BMC_HV  # _XIX_MIL_Master_XIX_OBD_XIX_HCP1_XIX_diagnosis_infrastructure_Hybrid_01_XIX_diagnosis_infrastructure_XIX_BMC_HV_XIX_OBD_Abs_Pedal_Pos
    delegate diagnosis_infrastructure_Hybrid_01_XIX_diagnosis_infrastructure_XIX_BMC_HV.RP_IF_OBD_Barometric_Pressure_XIX_diagnosis_infrastructure_Hybrid_01_XIX_diagnosis_infrastructure_XIX_BMC_HV <-> outer port RP_IF_OBD_Barometric_Pressure_XIX_BMC_HV  # _XIX_MIL_Master_XIX_OBD_XIX_HCP1_XIX_diagnosis_infrastructure_Hybrid_01_XIX_diagnosis_infrastructure_XIX_BMC_HV_XIX_OBD_Barometric_Pressure
    delegate diagnosis_infrastructure_Hybrid_01_XIX_diagnosis_infrastructure_XIX_BMC_HV.RP_IF_OBD_Aussen_Temp_gef_XIX_diagnosis_infrastructure_Hybrid_01_XIX_diagnosis_infrastructure_XIX_BMC_HV <-> outer port RP_IF_OBD_Aussen_Temp_gef_XIX_BMC_HV  # _XIX_MIL_Master_XIX_OBD_XIX_HCP1_XIX_diagnosis_infrastructure_Hybrid_01_XIX_diagnosis_infrastructure_XIX_BMC_HV_XIX_OBD_Aussen_Temp_gef
    delegate diagnosis_infrastructure_Hybrid_01_XIX_diagnosis_infrastructure_XIX_BMC_HV.RP_IF_OBD_Sperrung_IUMPR_XIX_diagnosis_infrastructure_Hybrid_01_XIX_diagnosis_infrastructure_XIX_BMC_HV <-> outer port RP_IF_OBD_Sperrung_IUMPR_XIX_BMC_HV  # _XIX_MIL_Master_XIX_OBD_XIX_HCP1_XIX_diagnosis_infrastructure_Hybrid_01_XIX_diagnosis_infrastructure_XIX_BMC_HV_XIX_OBD_Sperrung_IUMPR
    delegate diagnosis_infrastructure_Hybrid_01_XIX_diagnosis_infrastructure_XIX_BMC_HV.RP_IF_OBD_ClearMem_Inhibit_XIX_diagnosis_infrastructure_Hybrid_01_XIX_diagnosis_infrastructure_XIX_BMC_HV <-> outer port RP_IF_OBD_ClearMem_Inhibit_XIX_BMC_HV  # _XIX_MIL_Master_XIX_OBD_XIX_HCP1_XIX_diagnosis_infrastructure_Hybrid_01_XIX_diagnosis_infrastructure_XIX_BMC_HV_XIX_OBD_ClearMem_Inhibit
    delegate diagnosis_infrastructure_Hybrid_01_XIX_diagnosis_infrastructure_XIX_BMC_HV.RP_IF_OBD_Kaltstart_Denominator_XIX_diagnosis_infrastructure_Hybrid_01_XIX_diagnosis_infrastructure_XIX_BMC_HV <-> outer port RP_IF_OBD_Kaltstart_Denominator_XIX_BMC_HV  # _XIX_MIL_Master_XIX_OBD_XIX_HCP1_XIX_diagnosis_infrastructure_Hybrid_01_XIX_diagnosis_infrastructure_XIX_BMC_HV_XIX_OBD_Kaltstart_Denominator
    delegate diagnosis_infrastructure_Hybrid_01_XIX_diagnosis_infrastructure_XIX_BMC_HV.RP_IF_OBD_Typ_XIX_diagnosis_infrastructure_Hybrid_01_XIX_diagnosis_infrastructure_XIX_BMC_HV <-> outer port RP_IF_OBD_Typ_XIX_BMC_HV
    delegate HochvoltBatterieManagement_XIX_SoC_XIX_BMC_HV.RP_IF_HVLE_IstSpannung_HV_XIX_HochvoltBatterieManagement_XIX_SoC_XIX_BMC_HV <-> outer port RP_IF_HVLE_IstSpannung_HV_XIX_BMC_HV  # _XIX_MesswerteOnboardGleichrichter_MOBG_XIX_HV_Laden_XIX_IPB_XIX_HochvoltBatterieManagement_XIX_SoC_XIX_BMC_HV_XIX_HVLE_IstSpannung_HV
    delegate Infrastructure_Hybrid_01_XIX_network_infrastructure_XIX_BMC_HV.RP_IF_NVEM_Abschaltstufe_XIX_Infrastructure_Hybrid_01_XIX_network_infrastructure_XIX_BMC_HV <-> outer port RP_IF_NVEM_Abschaltstufe_XIX_BMC_HV  # _XIX_NiedervoltEnergiemanagement_XIX_NVEV_Basis_XIX_HCP5_P2_OBD_Safety_XIX_Infrastructure_Hybrid_01_XIX_network_infrastructure_XIX_BMC_HV_XIX_NVEM_Abschaltstufe
    delegate OTA_Infrastructure_Hybrid_01_XIX_ORU6_XIX_BMC_HV.RP_IF_SG_ORU_Control_A_01_XIX_OTA_Infrastructure_Hybrid_01_XIX_ORU6_XIX_BMC_HV <-> outer port RP_IF_SG_ORU_Control_A_01_XIX_BMC_HV
    delegate OTA_Infrastructure_Hybrid_01_XIX_ORU6_XIX_BMC_HV.RP_IF_SG_ORU_Control_D_01_XIX_OTA_Infrastructure_Hybrid_01_XIX_ORU6_XIX_BMC_HV <-> outer port RP_IF_SG_ORU_Control_D_01_XIX_BMC_HV
    delegate OTA_Infrastructure_Hybrid_01_XIX_ORU6_XIX_BMC_HV.RP_IF_SG_OTAMC_D_01_XIX_OTA_Infrastructure_Hybrid_01_XIX_ORU6_XIX_BMC_HV <-> outer port RP_IF_SG_OTAMC_D_01_XIX_BMC_HV  # DCon_XIX_OTAMC_VehicleStateManager_Safety_D_XIX_OTAMC_XIX_HCP1_XIX_OTA_Infrastructure_Hybrid_01_XIX_ORU6_XIX_BMC_HV_XIX_SG_OTAMC_D_01
    delegate ORU_Infrastructure_Hybrid_01_XIX_ORU6_XIX_BMC_HV.RP_IF_ORU_Status_XIX_ORU_Infrastructure_Hybrid_01_XIX_ORU6_XIX_BMC_HV <-> outer port RP_IF_ORU_Status_XIX_BMC_HV  # _XIX_OTA_MasterCapability_SCILib_XIX_OTAMC_XIX_HCP5_P4_E3SWPAC_XIX_ORU_Infrastructure_Hybrid_01_XIX_ORU6_XIX_BMC_HV_XIX_ORU_Status
    delegate HochvoltBatterieManagement_XIX_SoC_XIX_BMC_HV.RP_IF_HVLE_OBG_IstModus_XIX_HochvoltBatterieManagement_XIX_SoC_XIX_BMC_HV <-> outer port RP_IF_HVLE_OBG_IstModus_XIX_BMC_HV
    delegate HochvoltBatterieManagement_XIX_SoC_XIX_BMC_HV.RP_IF_OTP_Aussen_Temp_ungef_XIX_HochvoltBatterieManagement_XIX_SoC_XIX_BMC_HV <-> outer port RP_IF_OTP_Aussen_Temp_ungef_XIX_BMC_HV  # _XIX_OutsideTemperatureProvider_XIX_Temperature_XIX_HCP4_uC2_1_XIX_HochvoltBatterieManagement_XIX_SoC_XIX_BMC_HV_XIX_OTP_Aussen_Temp_ungef
    delegate HochvoltBatterieManagement_XIX_SoC_XIX_BMC_HV.RP_IF_OTP_Aussen_Temp_OBD_XIX_HochvoltBatterieManagement_XIX_SoC_XIX_BMC_HV <-> outer port RP_IF_OTP_Aussen_Temp_OBD_XIX_BMC_HV  # _XIX_OutsideTemperatureProvider_XIX_Temperature_XIX_HCP4_uC2_1_XIX_HochvoltBatterieManagement_XIX_SoC_XIX_BMC_HV_XIX_OTP_Aussen_Temp_OBD
    delegate SOK_Participant_BMC_HV_XIX_SOK_XIX_BMC_HV.SP_IF_SOK_Zeit_Hybrid_01_Challenge_XIX_SOK_Participant_BMC_HV_XIX_SOK_XIX_BMC_HV <-> outer port SP_IF_SOK_Zeit_Hybrid_01_Challenge_XIX_BMC_HV
    delegate SOK_Participant_BMC_HV_XIX_SOK_XIX_BMC_HV.RP_IF_SOK_Zeit_Hybrid_01_Zeit_XIX_SOK_Participant_BMC_HV_XIX_SOK_XIX_BMC_HV <-> outer port RP_IF_SOK_Zeit_Hybrid_01_Zeit_XIX_BMC_HV
    delegate SOK_Participant_BMC_HV_XIX_SOK_XIX_BMC_HV.RP_IF_SOK_ungeschuetzte_Zeit_XIX_SOK_Participant_BMC_HV_XIX_SOK_XIX_BMC_HV <-> outer port RP_IF_SOK_ungeschuetzte_Zeit_XIX_BMC_HV
    delegate HochvoltBatterieManagement_XIX_SoC_XIX_BMC_HV.RP_IF_TME_Therm_IstLeistung_HVBatterie_XIX_HochvoltBatterieManagement_XIX_SoC_XIX_BMC_HV <-> outer port RP_IF_TME_Therm_IstLeistung_HVBatterie_XIX_BMC_HV  # _XIX_Thermomanagement_XIX_TME_XIX_HCP4_uC2_1_XIX_HochvoltBatterieManagement_XIX_SoC_XIX_BMC_HV_XIX_TME_Therm_IstLeistung_HVBatterie
    delegate HochvoltBatterieManagement_XIX_SoC_XIX_BMC_HV.RP_IF_EKK_HVK_EoHVL_Status_XIX_HochvoltBatterieManagement_XIX_SoC_XIX_BMC_HV <-> outer port RP_IF_EKK_HVK_EoHVL_Status_XIX_BMC_HV
    delegate HochvoltBatterieManagement_XIX_SoC_XIX_BMC_HV.RP_IF_TME_Batt_Kond_Verf_XIX_HochvoltBatterieManagement_XIX_SoC_XIX_BMC_HV <-> outer port RP_IF_TME_Batt_Kond_Verf_XIX_BMC_HV
    delegate DaapServer_BMC_HV_XIX_GDC_DAAP_XIX_BMC_HV.RP_IF_UH_Jahr_XIX_DaapServer_BMC_HV_XIX_GDC_DAAP_XIX_BMC_HV <-> outer port RP_IF_UH_Jahr_XIX_BMC_HV
    delegate DaapServer_BMC_HV_XIX_GDC_DAAP_XIX_BMC_HV.RP_IF_UH_Minute_XIX_DaapServer_BMC_HV_XIX_GDC_DAAP_XIX_BMC_HV <-> outer port RP_IF_UH_Minute_XIX_BMC_HV
    delegate DaapServer_BMC_HV_XIX_GDC_DAAP_XIX_BMC_HV.RP_IF_UH_Monat_XIX_DaapServer_BMC_HV_XIX_GDC_DAAP_XIX_BMC_HV <-> outer port RP_IF_UH_Monat_XIX_BMC_HV
    delegate DaapServer_BMC_HV_XIX_GDC_DAAP_XIX_BMC_HV.RP_IF_UH_Sekunde_XIX_DaapServer_BMC_HV_XIX_GDC_DAAP_XIX_BMC_HV <-> outer port RP_IF_UH_Sekunde_XIX_BMC_HV
    delegate DaapServer_BMC_HV_XIX_GDC_DAAP_XIX_BMC_HV.RP_IF_UH_Stunde_XIX_DaapServer_BMC_HV_XIX_GDC_DAAP_XIX_BMC_HV <-> outer port RP_IF_UH_Stunde_XIX_BMC_HV
    delegate DaapServer_BMC_HV_XIX_GDC_DAAP_XIX_BMC_HV.RP_IF_UH_Tag_XIX_DaapServer_BMC_HV_XIX_GDC_DAAP_XIX_BMC_HV <-> outer port RP_IF_UH_Tag_XIX_BMC_HV
    delegate HochvoltBatterieManagement_XIX_SoC_XIX_BMC_HV.RP_IF_UH_Jahr_XIX_HochvoltBatterieManagement_XIX_SoC_XIX_BMC_HV <-> outer port RP_IF_UH_Jahr_XIX_BMC_HV
    delegate HochvoltBatterieManagement_XIX_SoC_XIX_BMC_HV.RP_IF_UH_Minute_XIX_HochvoltBatterieManagement_XIX_SoC_XIX_BMC_HV <-> outer port RP_IF_UH_Minute_XIX_BMC_HV
    delegate HochvoltBatterieManagement_XIX_SoC_XIX_BMC_HV.RP_IF_UH_Monat_XIX_HochvoltBatterieManagement_XIX_SoC_XIX_BMC_HV <-> outer port RP_IF_UH_Monat_XIX_BMC_HV
    delegate HochvoltBatterieManagement_XIX_SoC_XIX_BMC_HV.RP_IF_UH_Sekunde_XIX_HochvoltBatterieManagement_XIX_SoC_XIX_BMC_HV <-> outer port RP_IF_UH_Sekunde_XIX_BMC_HV
    delegate HochvoltBatterieManagement_XIX_SoC_XIX_BMC_HV.RP_IF_UH_Stunde_XIX_HochvoltBatterieManagement_XIX_SoC_XIX_BMC_HV <-> outer port RP_IF_UH_Stunde_XIX_BMC_HV
    delegate HochvoltBatterieManagement_XIX_SoC_XIX_BMC_HV.RP_IF_UH_Tag_XIX_HochvoltBatterieManagement_XIX_SoC_XIX_BMC_HV <-> outer port RP_IF_UH_Tag_XIX_BMC_HV
    delegate diagnosis_infrastructure_Hybrid_01_XIX_diagnosis_infrastructure_XIX_BMC_HV.RP_IF_UH_Stunde_XIX_diagnosis_infrastructure_Hybrid_01_XIX_diagnosis_infrastructure_XIX_BMC_HV <-> outer port RP_IF_UH_Stunde_XIX_BMC_HV  # _XIX_TimeMaster_Base_XIX_ZM_XIX_HCP5_P1_Gateway_XIX_diagnosis_infrastructure_Hybrid_01_XIX_diagnosis_infrastructure_XIX_BMC_HV_XIX_UH_Stunde
    delegate diagnosis_infrastructure_Hybrid_01_XIX_diagnosis_infrastructure_XIX_BMC_HV.RP_IF_UH_Sekunde_XIX_diagnosis_infrastructure_Hybrid_01_XIX_diagnosis_infrastructure_XIX_BMC_HV <-> outer port RP_IF_UH_Sekunde_XIX_BMC_HV  # _XIX_TimeMaster_Base_XIX_ZM_XIX_HCP5_P1_Gateway_XIX_diagnosis_infrastructure_Hybrid_01_XIX_diagnosis_infrastructure_XIX_BMC_HV_XIX_UH_Sekunde
    delegate diagnosis_infrastructure_Hybrid_01_XIX_diagnosis_infrastructure_XIX_BMC_HV.RP_IF_UH_Tag_XIX_diagnosis_infrastructure_Hybrid_01_XIX_diagnosis_infrastructure_XIX_BMC_HV <-> outer port RP_IF_UH_Tag_XIX_BMC_HV  # _XIX_TimeMaster_Base_XIX_ZM_XIX_HCP5_P1_Gateway_XIX_diagnosis_infrastructure_Hybrid_01_XIX_diagnosis_infrastructure_XIX_BMC_HV_XIX_UH_Tag
    delegate diagnosis_infrastructure_Hybrid_01_XIX_diagnosis_infrastructure_XIX_BMC_HV.RP_IF_UH_Monat_XIX_diagnosis_infrastructure_Hybrid_01_XIX_diagnosis_infrastructure_XIX_BMC_HV <-> outer port RP_IF_UH_Monat_XIX_BMC_HV  # _XIX_TimeMaster_Base_XIX_ZM_XIX_HCP5_P1_Gateway_XIX_diagnosis_infrastructure_Hybrid_01_XIX_diagnosis_infrastructure_XIX_BMC_HV_XIX_UH_Monat
    delegate diagnosis_infrastructure_Hybrid_01_XIX_diagnosis_infrastructure_XIX_BMC_HV.RP_IF_UH_Jahr_XIX_diagnosis_infrastructure_Hybrid_01_XIX_diagnosis_infrastructure_XIX_BMC_HV <-> outer port RP_IF_UH_Jahr_XIX_BMC_HV  # _XIX_TimeMaster_Base_XIX_ZM_XIX_HCP5_P1_Gateway_XIX_diagnosis_infrastructure_Hybrid_01_XIX_diagnosis_infrastructure_XIX_BMC_HV_XIX_UH_Jahr
    delegate diagnosis_infrastructure_Hybrid_01_XIX_diagnosis_infrastructure_XIX_BMC_HV.RP_IF_UH_Minute_XIX_diagnosis_infrastructure_Hybrid_01_XIX_diagnosis_infrastructure_XIX_BMC_HV <-> outer port RP_IF_UH_Minute_XIX_BMC_HV  # _XIX_TimeMaster_Base_XIX_ZM_XIX_HCP5_P1_Gateway_XIX_diagnosis_infrastructure_Hybrid_01_XIX_diagnosis_infrastructure_XIX_BMC_HV_XIX_UH_Minute
    delegate HochvoltBatterieManagement_XIX_SoC_XIX_BMC_HV.RP_IF_ZM_HV_Auszeit_XIX_HochvoltBatterieManagement_XIX_SoC_XIX_BMC_HV <-> outer port RP_IF_ZM_HV_Auszeit_XIX_BMC_HV
    delegate HochvoltBatterieManagement_XIX_SoC_XIX_BMC_HV.RP_IF_ZM_HV_Auszeit_HiRes_XIX_HochvoltBatterieManagement_XIX_SoC_XIX_BMC_HV <-> outer port RP_IF_ZM_HV_Auszeit_HiRes_XIX_BMC_HV
    delegate HochvoltBatterieManagement_XIX_SoC_XIX_BMC_HV.RP_IF_ZM_HV_Auszeit_Status_XIX_HochvoltBatterieManagement_XIX_SoC_XIX_BMC_HV <-> outer port RP_IF_ZM_HV_Auszeit_Status_XIX_BMC_HV
    delegate diagnosis_infrastructure_Hybrid_01_XIX_diagnosis_infrastructure_XIX_BMC_HV.RP_IF_VDSO_Vx3d_XIX_diagnosis_infrastructure_Hybrid_01_XIX_diagnosis_infrastructure_XIX_BMC_HV <-> outer port RP_IF_VDSO_Vx3d_XIX_BMC_HV  # _XIX_VehicleDrivingStateObserver_XIX_AntriebsMom_Regelung_und_Verteilung_XIX_HCP1_XIX_diagnosis_infrastructure_Hybrid_01_XIX_diagnosis_infrastructure_XIX_BMC_HV_XIX_VDSO_Vx3d
    delegate diagnosis_infrastructure_Hybrid_01_XIX_diagnosis_infrastructure_XIX_BMC_HV.RP_IF_BJB_CALID_Index_13_XIX_diagnosis_infrastructure_Hybrid_01_XIX_diagnosis_infrastructure_XIX_BMC_HV <-> outer port RP_IF_BJB_CALID_Index_13_XIX_BMC_HV  # _XIX_diagnosis_infrastructure_BJB_XIX_diagnosis_infrastructure_XIX_BJB_2_XIX_diagnosis_infrastructure_Hybrid_01_XIX_diagnosis_infrastructure_XIX_BMC_HV_XIX_BJB_CALID_Index_13
    delegate diagnosis_infrastructure_Hybrid_01_XIX_diagnosis_infrastructure_XIX_BMC_HV.RP_IF_BJB_CVN_Byte_3_XIX_diagnosis_infrastructure_Hybrid_01_XIX_diagnosis_infrastructure_XIX_BMC_HV <-> outer port RP_IF_BJB_CVN_Byte_3_XIX_BMC_HV  # _XIX_diagnosis_infrastructure_BJB_XIX_diagnosis_infrastructure_XIX_BJB_2_XIX_diagnosis_infrastructure_Hybrid_01_XIX_diagnosis_infrastructure_XIX_BMC_HV_XIX_BJB_CVN_Byte_3
    delegate diagnosis_infrastructure_Hybrid_01_XIX_diagnosis_infrastructure_XIX_BMC_HV.RP_IF_BJB_CALID_Index_05_XIX_diagnosis_infrastructure_Hybrid_01_XIX_diagnosis_infrastructure_XIX_BMC_HV <-> outer port RP_IF_BJB_CALID_Index_05_XIX_BMC_HV  # _XIX_diagnosis_infrastructure_BJB_XIX_diagnosis_infrastructure_XIX_BJB_2_XIX_diagnosis_infrastructure_Hybrid_01_XIX_diagnosis_infrastructure_XIX_BMC_HV_XIX_BJB_CALID_Index_05
    delegate diagnosis_infrastructure_Hybrid_01_XIX_diagnosis_infrastructure_XIX_BMC_HV.RP_IF_BJB_CALID_Index_12_XIX_diagnosis_infrastructure_Hybrid_01_XIX_diagnosis_infrastructure_XIX_BMC_HV <-> outer port RP_IF_BJB_CALID_Index_12_XIX_BMC_HV  # _XIX_diagnosis_infrastructure_BJB_XIX_diagnosis_infrastructure_XIX_BJB_2_XIX_diagnosis_infrastructure_Hybrid_01_XIX_diagnosis_infrastructure_XIX_BMC_HV_XIX_BJB_CALID_Index_12
    delegate diagnosis_infrastructure_Hybrid_01_XIX_diagnosis_infrastructure_XIX_BMC_HV.RP_IF_BJB_CALID_Index_15_XIX_diagnosis_infrastructure_Hybrid_01_XIX_diagnosis_infrastructure_XIX_BMC_HV <-> outer port RP_IF_BJB_CALID_Index_15_XIX_BMC_HV  # _XIX_diagnosis_infrastructure_BJB_XIX_diagnosis_infrastructure_XIX_BJB_2_XIX_diagnosis_infrastructure_Hybrid_01_XIX_diagnosis_infrastructure_XIX_BMC_HV_XIX_BJB_CALID_Index_15
    delegate diagnosis_infrastructure_Hybrid_01_XIX_diagnosis_infrastructure_XIX_BMC_HV.RP_IF_BJB_CALID_Index_10_XIX_diagnosis_infrastructure_Hybrid_01_XIX_diagnosis_infrastructure_XIX_BMC_HV <-> outer port RP_IF_BJB_CALID_Index_10_XIX_BMC_HV  # _XIX_diagnosis_infrastructure_BJB_XIX_diagnosis_infrastructure_XIX_BJB_2_XIX_diagnosis_infrastructure_Hybrid_01_XIX_diagnosis_infrastructure_XIX_BMC_HV_XIX_BJB_CALID_Index_10
    delegate diagnosis_infrastructure_Hybrid_01_XIX_diagnosis_infrastructure_XIX_BMC_HV.RP_IF_BJB_CALID_Index_11_XIX_diagnosis_infrastructure_Hybrid_01_XIX_diagnosis_infrastructure_XIX_BMC_HV <-> outer port RP_IF_BJB_CALID_Index_11_XIX_BMC_HV  # _XIX_diagnosis_infrastructure_BJB_XIX_diagnosis_infrastructure_XIX_BJB_2_XIX_diagnosis_infrastructure_Hybrid_01_XIX_diagnosis_infrastructure_XIX_BMC_HV_XIX_BJB_CALID_Index_11
    delegate diagnosis_infrastructure_Hybrid_01_XIX_diagnosis_infrastructure_XIX_BMC_HV.RP_IF_BJB_CALID_Index_04_XIX_diagnosis_infrastructure_Hybrid_01_XIX_diagnosis_infrastructure_XIX_BMC_HV <-> outer port RP_IF_BJB_CALID_Index_04_XIX_BMC_HV  # _XIX_diagnosis_infrastructure_BJB_XIX_diagnosis_infrastructure_XIX_BJB_2_XIX_diagnosis_infrastructure_Hybrid_01_XIX_diagnosis_infrastructure_XIX_BMC_HV_XIX_BJB_CALID_Index_04
    delegate diagnosis_infrastructure_Hybrid_01_XIX_diagnosis_infrastructure_XIX_BMC_HV.RP_IF_BJB_ErrMem_State_XIX_diagnosis_infrastructure_Hybrid_01_XIX_diagnosis_infrastructure_XIX_BMC_HV <-> outer port RP_IF_BJB_ErrMem_State_XIX_BMC_HV  # _XIX_diagnosis_infrastructure_BJB_XIX_diagnosis_infrastructure_XIX_BJB_2_XIX_diagnosis_infrastructure_Hybrid_01_XIX_diagnosis_infrastructure_XIX_BMC_HV_XIX_BJB_ErrMem_State
    delegate diagnosis_infrastructure_Hybrid_01_XIX_diagnosis_infrastructure_XIX_BMC_HV.RP_IF_BJB_CALID_Index_03_XIX_diagnosis_infrastructure_Hybrid_01_XIX_diagnosis_infrastructure_XIX_BMC_HV <-> outer port RP_IF_BJB_CALID_Index_03_XIX_BMC_HV  # _XIX_diagnosis_infrastructure_BJB_XIX_diagnosis_infrastructure_XIX_BJB_2_XIX_diagnosis_infrastructure_Hybrid_01_XIX_diagnosis_infrastructure_XIX_BMC_HV_XIX_BJB_CALID_Index_03
    delegate diagnosis_infrastructure_Hybrid_01_XIX_diagnosis_infrastructure_XIX_BMC_HV.RP_IF_BJB_CALID_Index_06_XIX_diagnosis_infrastructure_Hybrid_01_XIX_diagnosis_infrastructure_XIX_BMC_HV <-> outer port RP_IF_BJB_CALID_Index_06_XIX_BMC_HV  # _XIX_diagnosis_infrastructure_BJB_XIX_diagnosis_infrastructure_XIX_BJB_2_XIX_diagnosis_infrastructure_Hybrid_01_XIX_diagnosis_infrastructure_XIX_BMC_HV_XIX_BJB_CALID_Index_06
    delegate diagnosis_infrastructure_Hybrid_01_XIX_diagnosis_infrastructure_XIX_BMC_HV.RP_IF_BJB_CVN_Byte_1_XIX_diagnosis_infrastructure_Hybrid_01_XIX_diagnosis_infrastructure_XIX_BMC_HV <-> outer port RP_IF_BJB_CVN_Byte_1_XIX_BMC_HV  # _XIX_diagnosis_infrastructure_BJB_XIX_diagnosis_infrastructure_XIX_BJB_2_XIX_diagnosis_infrastructure_Hybrid_01_XIX_diagnosis_infrastructure_XIX_BMC_HV_XIX_BJB_CVN_Byte_1
    delegate diagnosis_infrastructure_Hybrid_01_XIX_diagnosis_infrastructure_XIX_BMC_HV.RP_IF_BJB_CALID_Index_02_XIX_diagnosis_infrastructure_Hybrid_01_XIX_diagnosis_infrastructure_XIX_BMC_HV <-> outer port RP_IF_BJB_CALID_Index_02_XIX_BMC_HV  # _XIX_diagnosis_infrastructure_BJB_XIX_diagnosis_infrastructure_XIX_BJB_2_XIX_diagnosis_infrastructure_Hybrid_01_XIX_diagnosis_infrastructure_XIX_BMC_HV_XIX_BJB_CALID_Index_02
    delegate diagnosis_infrastructure_Hybrid_01_XIX_diagnosis_infrastructure_XIX_BMC_HV.RP_IF_BJB_CALID_Index_14_XIX_diagnosis_infrastructure_Hybrid_01_XIX_diagnosis_infrastructure_XIX_BMC_HV <-> outer port RP_IF_BJB_CALID_Index_14_XIX_BMC_HV  # _XIX_diagnosis_infrastructure_BJB_XIX_diagnosis_infrastructure_XIX_BJB_2_XIX_diagnosis_infrastructure_Hybrid_01_XIX_diagnosis_infrastructure_XIX_BMC_HV_XIX_BJB_CALID_Index_14
    delegate diagnosis_infrastructure_Hybrid_01_XIX_diagnosis_infrastructure_XIX_BMC_HV.RP_IF_BJB_CALID_Index_08_XIX_diagnosis_infrastructure_Hybrid_01_XIX_diagnosis_infrastructure_XIX_BMC_HV <-> outer port RP_IF_BJB_CALID_Index_08_XIX_BMC_HV  # _XIX_diagnosis_infrastructure_BJB_XIX_diagnosis_infrastructure_XIX_BJB_2_XIX_diagnosis_infrastructure_Hybrid_01_XIX_diagnosis_infrastructure_XIX_BMC_HV_XIX_BJB_CALID_Index_08
    delegate diagnosis_infrastructure_Hybrid_01_XIX_diagnosis_infrastructure_XIX_BMC_HV.RP_IF_BJB_CALID_Index_07_XIX_diagnosis_infrastructure_Hybrid_01_XIX_diagnosis_infrastructure_XIX_BMC_HV <-> outer port RP_IF_BJB_CALID_Index_07_XIX_BMC_HV  # _XIX_diagnosis_infrastructure_BJB_XIX_diagnosis_infrastructure_XIX_BJB_2_XIX_diagnosis_infrastructure_Hybrid_01_XIX_diagnosis_infrastructure_XIX_BMC_HV_XIX_BJB_CALID_Index_07
    delegate diagnosis_infrastructure_Hybrid_01_XIX_diagnosis_infrastructure_XIX_BMC_HV.RP_IF_BJB_CVN_VLD_XIX_diagnosis_infrastructure_Hybrid_01_XIX_diagnosis_infrastructure_XIX_BMC_HV <-> outer port RP_IF_BJB_CVN_VLD_XIX_BMC_HV  # _XIX_diagnosis_infrastructure_BJB_XIX_diagnosis_infrastructure_XIX_BJB_2_XIX_diagnosis_infrastructure_Hybrid_01_XIX_diagnosis_infrastructure_XIX_BMC_HV_XIX_BJB_CVN_VLD
    delegate diagnosis_infrastructure_Hybrid_01_XIX_diagnosis_infrastructure_XIX_BMC_HV.RP_IF_BJB_CALID_Index_16_XIX_diagnosis_infrastructure_Hybrid_01_XIX_diagnosis_infrastructure_XIX_BMC_HV <-> outer port RP_IF_BJB_CALID_Index_16_XIX_BMC_HV  # _XIX_diagnosis_infrastructure_BJB_XIX_diagnosis_infrastructure_XIX_BJB_2_XIX_diagnosis_infrastructure_Hybrid_01_XIX_diagnosis_infrastructure_XIX_BMC_HV_XIX_BJB_CALID_Index_16
    delegate diagnosis_infrastructure_Hybrid_01_XIX_diagnosis_infrastructure_XIX_BMC_HV.RP_IF_BJB_CVN_Byte_2_XIX_diagnosis_infrastructure_Hybrid_01_XIX_diagnosis_infrastructure_XIX_BMC_HV <-> outer port RP_IF_BJB_CVN_Byte_2_XIX_BMC_HV  # _XIX_diagnosis_infrastructure_BJB_XIX_diagnosis_infrastructure_XIX_BJB_2_XIX_diagnosis_infrastructure_Hybrid_01_XIX_diagnosis_infrastructure_XIX_BMC_HV_XIX_BJB_CVN_Byte_2
    delegate diagnosis_infrastructure_Hybrid_01_XIX_diagnosis_infrastructure_XIX_BMC_HV.RP_IF_BJB_CALID_Index_01_XIX_diagnosis_infrastructure_Hybrid_01_XIX_diagnosis_infrastructure_XIX_BMC_HV <-> outer port RP_IF_BJB_CALID_Index_01_XIX_BMC_HV  # _XIX_diagnosis_infrastructure_BJB_XIX_diagnosis_infrastructure_XIX_BJB_2_XIX_diagnosis_infrastructure_Hybrid_01_XIX_diagnosis_infrastructure_XIX_BMC_HV_XIX_BJB_CALID_Index_01
    delegate diagnosis_infrastructure_Hybrid_01_XIX_diagnosis_infrastructure_XIX_BMC_HV.RP_IF_BJB_CALID_Index_09_XIX_diagnosis_infrastructure_Hybrid_01_XIX_diagnosis_infrastructure_XIX_BMC_HV <-> outer port RP_IF_BJB_CALID_Index_09_XIX_BMC_HV  # _XIX_diagnosis_infrastructure_BJB_XIX_diagnosis_infrastructure_XIX_BJB_2_XIX_diagnosis_infrastructure_Hybrid_01_XIX_diagnosis_infrastructure_XIX_BMC_HV_XIX_BJB_CALID_Index_09
    delegate diagnosis_infrastructure_Hybrid_01_XIX_diagnosis_infrastructure_XIX_BMC_HV.RP_IF_BJB_CVN_Byte_4_XIX_diagnosis_infrastructure_Hybrid_01_XIX_diagnosis_infrastructure_XIX_BMC_HV <-> outer port RP_IF_BJB_CVN_Byte_4_XIX_BMC_HV  # _XIX_diagnosis_infrastructure_BJB_XIX_diagnosis_infrastructure_XIX_BJB_2_XIX_diagnosis_infrastructure_Hybrid_01_XIX_diagnosis_infrastructure_XIX_BMC_HV_XIX_BJB_CVN_Byte_4
    delegate diagnosis_infrastructure_Hybrid_01_XIX_diagnosis_infrastructure_XIX_BMC_HV.RP_IF_DCDC_NV_CALID_Index_08_XIX_diagnosis_infrastructure_Hybrid_01_XIX_diagnosis_infrastructure_XIX_BMC_HV <-> outer port RP_IF_DCDC_NV_CALID_Index_08_XIX_BMC_HV  # _XIX_diagnosis_infrastructure_DCDC_NV_XIX_diagnosis_infrastructure_XIX_DCDC_HV_XIX_diagnosis_infrastructure_Hybrid_01_XIX_diagnosis_infrastructure_XIX_BMC_HV_XIX_DCDC_NV_CALID_Index_08
    delegate diagnosis_infrastructure_Hybrid_01_XIX_diagnosis_infrastructure_XIX_BMC_HV.RP_IF_DCDC_NV_CALID_Index_05_XIX_diagnosis_infrastructure_Hybrid_01_XIX_diagnosis_infrastructure_XIX_BMC_HV <-> outer port RP_IF_DCDC_NV_CALID_Index_05_XIX_BMC_HV  # _XIX_diagnosis_infrastructure_DCDC_NV_XIX_diagnosis_infrastructure_XIX_DCDC_HV_XIX_diagnosis_infrastructure_Hybrid_01_XIX_diagnosis_infrastructure_XIX_BMC_HV_XIX_DCDC_NV_CALID_Index_05
    delegate diagnosis_infrastructure_Hybrid_01_XIX_diagnosis_infrastructure_XIX_BMC_HV.RP_IF_DCDC_NV_CALID_Index_06_XIX_diagnosis_infrastructure_Hybrid_01_XIX_diagnosis_infrastructure_XIX_BMC_HV <-> outer port RP_IF_DCDC_NV_CALID_Index_06_XIX_BMC_HV  # _XIX_diagnosis_infrastructure_DCDC_NV_XIX_diagnosis_infrastructure_XIX_DCDC_HV_XIX_diagnosis_infrastructure_Hybrid_01_XIX_diagnosis_infrastructure_XIX_BMC_HV_XIX_DCDC_NV_CALID_Index_06
    delegate diagnosis_infrastructure_Hybrid_01_XIX_diagnosis_infrastructure_XIX_BMC_HV.RP_IF_DCDC_NV_CALID_Index_02_XIX_diagnosis_infrastructure_Hybrid_01_XIX_diagnosis_infrastructure_XIX_BMC_HV <-> outer port RP_IF_DCDC_NV_CALID_Index_02_XIX_BMC_HV  # _XIX_diagnosis_infrastructure_DCDC_NV_XIX_diagnosis_infrastructure_XIX_DCDC_HV_XIX_diagnosis_infrastructure_Hybrid_01_XIX_diagnosis_infrastructure_XIX_BMC_HV_XIX_DCDC_NV_CALID_Index_02
    delegate diagnosis_infrastructure_Hybrid_01_XIX_diagnosis_infrastructure_XIX_BMC_HV.RP_IF_DCDC_NV_CALID_Index_04_XIX_diagnosis_infrastructure_Hybrid_01_XIX_diagnosis_infrastructure_XIX_BMC_HV <-> outer port RP_IF_DCDC_NV_CALID_Index_04_XIX_BMC_HV  # _XIX_diagnosis_infrastructure_DCDC_NV_XIX_diagnosis_infrastructure_XIX_DCDC_HV_XIX_diagnosis_infrastructure_Hybrid_01_XIX_diagnosis_infrastructure_XIX_BMC_HV_XIX_DCDC_NV_CALID_Index_04
    delegate diagnosis_infrastructure_Hybrid_01_XIX_diagnosis_infrastructure_XIX_BMC_HV.RP_IF_DCDC_NV_CALID_Index_16_XIX_diagnosis_infrastructure_Hybrid_01_XIX_diagnosis_infrastructure_XIX_BMC_HV <-> outer port RP_IF_DCDC_NV_CALID_Index_16_XIX_BMC_HV  # _XIX_diagnosis_infrastructure_DCDC_NV_XIX_diagnosis_infrastructure_XIX_DCDC_HV_XIX_diagnosis_infrastructure_Hybrid_01_XIX_diagnosis_infrastructure_XIX_BMC_HV_XIX_DCDC_NV_CALID_Index_16
    delegate diagnosis_infrastructure_Hybrid_01_XIX_diagnosis_infrastructure_XIX_BMC_HV.RP_IF_DCDC_NV_CALID_Index_15_XIX_diagnosis_infrastructure_Hybrid_01_XIX_diagnosis_infrastructure_XIX_BMC_HV <-> outer port RP_IF_DCDC_NV_CALID_Index_15_XIX_BMC_HV  # _XIX_diagnosis_infrastructure_DCDC_NV_XIX_diagnosis_infrastructure_XIX_DCDC_HV_XIX_diagnosis_infrastructure_Hybrid_01_XIX_diagnosis_infrastructure_XIX_BMC_HV_XIX_DCDC_NV_CALID_Index_15
    delegate diagnosis_infrastructure_Hybrid_01_XIX_diagnosis_infrastructure_XIX_BMC_HV.RP_IF_DCDC_NV_CALID_Index_01_XIX_diagnosis_infrastructure_Hybrid_01_XIX_diagnosis_infrastructure_XIX_BMC_HV <-> outer port RP_IF_DCDC_NV_CALID_Index_01_XIX_BMC_HV  # _XIX_diagnosis_infrastructure_DCDC_NV_XIX_diagnosis_infrastructure_XIX_DCDC_HV_XIX_diagnosis_infrastructure_Hybrid_01_XIX_diagnosis_infrastructure_XIX_BMC_HV_XIX_DCDC_NV_CALID_Index_01
    delegate diagnosis_infrastructure_Hybrid_01_XIX_diagnosis_infrastructure_XIX_BMC_HV.RP_IF_DCDC_NV_CALID_Index_13_XIX_diagnosis_infrastructure_Hybrid_01_XIX_diagnosis_infrastructure_XIX_BMC_HV <-> outer port RP_IF_DCDC_NV_CALID_Index_13_XIX_BMC_HV  # _XIX_diagnosis_infrastructure_DCDC_NV_XIX_diagnosis_infrastructure_XIX_DCDC_HV_XIX_diagnosis_infrastructure_Hybrid_01_XIX_diagnosis_infrastructure_XIX_BMC_HV_XIX_DCDC_NV_CALID_Index_13
    delegate diagnosis_infrastructure_Hybrid_01_XIX_diagnosis_infrastructure_XIX_BMC_HV.RP_IF_DCDC_NV_CALID_Index_03_XIX_diagnosis_infrastructure_Hybrid_01_XIX_diagnosis_infrastructure_XIX_BMC_HV <-> outer port RP_IF_DCDC_NV_CALID_Index_03_XIX_BMC_HV  # _XIX_diagnosis_infrastructure_DCDC_NV_XIX_diagnosis_infrastructure_XIX_DCDC_HV_XIX_diagnosis_infrastructure_Hybrid_01_XIX_diagnosis_infrastructure_XIX_BMC_HV_XIX_DCDC_NV_CALID_Index_03
    delegate diagnosis_infrastructure_Hybrid_01_XIX_diagnosis_infrastructure_XIX_BMC_HV.RP_IF_DCDC_NV_CVN_VLD_XIX_diagnosis_infrastructure_Hybrid_01_XIX_diagnosis_infrastructure_XIX_BMC_HV <-> outer port RP_IF_DCDC_NV_CVN_VLD_XIX_BMC_HV  # _XIX_diagnosis_infrastructure_DCDC_NV_XIX_diagnosis_infrastructure_XIX_DCDC_HV_XIX_diagnosis_infrastructure_Hybrid_01_XIX_diagnosis_infrastructure_XIX_BMC_HV_XIX_DCDC_NV_CVN_VLD
    delegate diagnosis_infrastructure_Hybrid_01_XIX_diagnosis_infrastructure_XIX_BMC_HV.RP_IF_DCDC_NV_CALID_Index_14_XIX_diagnosis_infrastructure_Hybrid_01_XIX_diagnosis_infrastructure_XIX_BMC_HV <-> outer port RP_IF_DCDC_NV_CALID_Index_14_XIX_BMC_HV  # _XIX_diagnosis_infrastructure_DCDC_NV_XIX_diagnosis_infrastructure_XIX_DCDC_HV_XIX_diagnosis_infrastructure_Hybrid_01_XIX_diagnosis_infrastructure_XIX_BMC_HV_XIX_DCDC_NV_CALID_Index_14
    delegate diagnosis_infrastructure_Hybrid_01_XIX_diagnosis_infrastructure_XIX_BMC_HV.RP_IF_DCDC_NV_CVN_Byte_4_XIX_diagnosis_infrastructure_Hybrid_01_XIX_diagnosis_infrastructure_XIX_BMC_HV <-> outer port RP_IF_DCDC_NV_CVN_Byte_4_XIX_BMC_HV  # _XIX_diagnosis_infrastructure_DCDC_NV_XIX_diagnosis_infrastructure_XIX_DCDC_HV_XIX_diagnosis_infrastructure_Hybrid_01_XIX_diagnosis_infrastructure_XIX_BMC_HV_XIX_DCDC_NV_CVN_Byte_4
    delegate diagnosis_infrastructure_Hybrid_01_XIX_diagnosis_infrastructure_XIX_BMC_HV.RP_IF_DCDC_NV_CALID_Index_07_XIX_diagnosis_infrastructure_Hybrid_01_XIX_diagnosis_infrastructure_XIX_BMC_HV <-> outer port RP_IF_DCDC_NV_CALID_Index_07_XIX_BMC_HV  # _XIX_diagnosis_infrastructure_DCDC_NV_XIX_diagnosis_infrastructure_XIX_DCDC_HV_XIX_diagnosis_infrastructure_Hybrid_01_XIX_diagnosis_infrastructure_XIX_BMC_HV_XIX_DCDC_NV_CALID_Index_07
    delegate diagnosis_infrastructure_Hybrid_01_XIX_diagnosis_infrastructure_XIX_BMC_HV.RP_IF_DCDC_NV_CVN_Byte_2_XIX_diagnosis_infrastructure_Hybrid_01_XIX_diagnosis_infrastructure_XIX_BMC_HV <-> outer port RP_IF_DCDC_NV_CVN_Byte_2_XIX_BMC_HV  # _XIX_diagnosis_infrastructure_DCDC_NV_XIX_diagnosis_infrastructure_XIX_DCDC_HV_XIX_diagnosis_infrastructure_Hybrid_01_XIX_diagnosis_infrastructure_XIX_BMC_HV_XIX_DCDC_NV_CVN_Byte_2
    delegate diagnosis_infrastructure_Hybrid_01_XIX_diagnosis_infrastructure_XIX_BMC_HV.RP_IF_DCDC_NV_CALID_Index_10_XIX_diagnosis_infrastructure_Hybrid_01_XIX_diagnosis_infrastructure_XIX_BMC_HV <-> outer port RP_IF_DCDC_NV_CALID_Index_10_XIX_BMC_HV  # _XIX_diagnosis_infrastructure_DCDC_NV_XIX_diagnosis_infrastructure_XIX_DCDC_HV_XIX_diagnosis_infrastructure_Hybrid_01_XIX_diagnosis_infrastructure_XIX_BMC_HV_XIX_DCDC_NV_CALID_Index_10
    delegate diagnosis_infrastructure_Hybrid_01_XIX_diagnosis_infrastructure_XIX_BMC_HV.RP_IF_DCDC_NV_CALID_Index_11_XIX_diagnosis_infrastructure_Hybrid_01_XIX_diagnosis_infrastructure_XIX_BMC_HV <-> outer port RP_IF_DCDC_NV_CALID_Index_11_XIX_BMC_HV  # _XIX_diagnosis_infrastructure_DCDC_NV_XIX_diagnosis_infrastructure_XIX_DCDC_HV_XIX_diagnosis_infrastructure_Hybrid_01_XIX_diagnosis_infrastructure_XIX_BMC_HV_XIX_DCDC_NV_CALID_Index_11
    delegate diagnosis_infrastructure_Hybrid_01_XIX_diagnosis_infrastructure_XIX_BMC_HV.RP_IF_DCDC_NV_CVN_Byte_1_XIX_diagnosis_infrastructure_Hybrid_01_XIX_diagnosis_infrastructure_XIX_BMC_HV <-> outer port RP_IF_DCDC_NV_CVN_Byte_1_XIX_BMC_HV  # _XIX_diagnosis_infrastructure_DCDC_NV_XIX_diagnosis_infrastructure_XIX_DCDC_HV_XIX_diagnosis_infrastructure_Hybrid_01_XIX_diagnosis_infrastructure_XIX_BMC_HV_XIX_DCDC_NV_CVN_Byte_1
    delegate diagnosis_infrastructure_Hybrid_01_XIX_diagnosis_infrastructure_XIX_BMC_HV.RP_IF_DCDC_NV_CVN_Byte_3_XIX_diagnosis_infrastructure_Hybrid_01_XIX_diagnosis_infrastructure_XIX_BMC_HV <-> outer port RP_IF_DCDC_NV_CVN_Byte_3_XIX_BMC_HV  # _XIX_diagnosis_infrastructure_DCDC_NV_XIX_diagnosis_infrastructure_XIX_DCDC_HV_XIX_diagnosis_infrastructure_Hybrid_01_XIX_diagnosis_infrastructure_XIX_BMC_HV_XIX_DCDC_NV_CVN_Byte_3
    delegate diagnosis_infrastructure_Hybrid_01_XIX_diagnosis_infrastructure_XIX_BMC_HV.RP_IF_DCDC_NV_CALID_Index_09_XIX_diagnosis_infrastructure_Hybrid_01_XIX_diagnosis_infrastructure_XIX_BMC_HV <-> outer port RP_IF_DCDC_NV_CALID_Index_09_XIX_BMC_HV  # _XIX_diagnosis_infrastructure_DCDC_NV_XIX_diagnosis_infrastructure_XIX_DCDC_HV_XIX_diagnosis_infrastructure_Hybrid_01_XIX_diagnosis_infrastructure_XIX_BMC_HV_XIX_DCDC_NV_CALID_Index_09
    delegate diagnosis_infrastructure_Hybrid_01_XIX_diagnosis_infrastructure_XIX_BMC_HV.RP_IF_DCDC_NV_CALID_Index_12_XIX_diagnosis_infrastructure_Hybrid_01_XIX_diagnosis_infrastructure_XIX_BMC_HV <-> outer port RP_IF_DCDC_NV_CALID_Index_12_XIX_BMC_HV  # _XIX_diagnosis_infrastructure_DCDC_NV_XIX_diagnosis_infrastructure_XIX_DCDC_HV_XIX_diagnosis_infrastructure_Hybrid_01_XIX_diagnosis_infrastructure_XIX_BMC_HV_XIX_DCDC_NV_CALID_Index_12
    delegate diagnosis_infrastructure_Hybrid_01_XIX_diagnosis_infrastructure_XIX_BMC_HV.SP_IF_DS_Hybrid_01_ConfDTCChanged_XIX_diagnosis_infrastructure_Hybrid_01_XIX_diagnosis_infrastructure_XIX_BMC_HV <-> outer port SP_IF_DS_Hybrid_01_ConfDTCChanged_XIX_BMC_HV  # _XIX_diagnosis_infrastructure_Hybrid_01_XIX_diagnosis_infrastructure_XIX_BMC_HV_XIX_Kommunikationsserver_HCP5_Generierung_XIX_ComServ_XIX_HCP5_P4_E3SWPAC_XIX_DS_Hybrid_01_ConfDTCChanged
    delegate diagnosis_infrastructure_Hybrid_01_XIX_diagnosis_infrastructure_XIX_BMC_HV.SP_IF_DS_Hybrid_01_DiagAdr_XIX_diagnosis_infrastructure_Hybrid_01_XIX_diagnosis_infrastructure_XIX_BMC_HV <-> outer port SP_IF_DS_Hybrid_01_DiagAdr_XIX_BMC_HV  # _XIX_diagnosis_infrastructure_Hybrid_01_XIX_diagnosis_infrastructure_XIX_BMC_HV_XIX_Kommunikationsserver_HCP5_Generierung_XIX_ComServ_XIX_HCP5_P4_E3SWPAC_XIX_DS_Hybrid_01_DiagAdr
    delegate diagnosis_infrastructure_Hybrid_01_XIX_diagnosis_infrastructure_XIX_BMC_HV.SP_IF_DS_Hybrid_01_IdentValid_XIX_diagnosis_infrastructure_Hybrid_01_XIX_diagnosis_infrastructure_XIX_BMC_HV <-> outer port SP_IF_DS_Hybrid_01_IdentValid_XIX_BMC_HV  # _XIX_diagnosis_infrastructure_Hybrid_01_XIX_diagnosis_infrastructure_XIX_BMC_HV_XIX_Kommunikationsserver_HCP5_Generierung_XIX_ComServ_XIX_HCP5_P4_E3SWPAC_XIX_DS_Hybrid_01_IdentValid
    delegate diagnosis_infrastructure_Hybrid_01_XIX_diagnosis_infrastructure_XIX_BMC_HV.SP_IF_DS_Hybrid_01_MemSel10Changed_XIX_diagnosis_infrastructure_Hybrid_01_XIX_diagnosis_infrastructure_XIX_BMC_HV <-> outer port SP_IF_DS_Hybrid_01_MemSel10Changed_XIX_BMC_HV  # _XIX_diagnosis_infrastructure_Hybrid_01_XIX_diagnosis_infrastructure_XIX_BMC_HV_XIX_Kommunikationsserver_HCP5_Generierung_XIX_ComServ_XIX_HCP5_P4_E3SWPAC_XIX_DS_Hybrid_01_MemSel10Changed
    delegate diagnosis_infrastructure_Hybrid_01_XIX_diagnosis_infrastructure_XIX_BMC_HV.SP_IF_DS_Hybrid_01_MemSelChanged_XIX_diagnosis_infrastructure_Hybrid_01_XIX_diagnosis_infrastructure_XIX_BMC_HV <-> outer port SP_IF_DS_Hybrid_01_MemSelChanged_XIX_BMC_HV  # _XIX_diagnosis_infrastructure_Hybrid_01_XIX_diagnosis_infrastructure_XIX_BMC_HV_XIX_Kommunikationsserver_HCP5_Generierung_XIX_ComServ_XIX_HCP5_P4_E3SWPAC_XIX_DS_Hybrid_01_MemSelChanged
    delegate diagnosis_infrastructure_Hybrid_01_XIX_diagnosis_infrastructure_XIX_BMC_HV.SP_IF_DS_Hybrid_01_StMemChanged_XIX_diagnosis_infrastructure_Hybrid_01_XIX_diagnosis_infrastructure_XIX_BMC_HV <-> outer port SP_IF_DS_Hybrid_01_StMemChanged_XIX_BMC_HV  # _XIX_diagnosis_infrastructure_Hybrid_01_XIX_diagnosis_infrastructure_XIX_BMC_HV_XIX_Kommunikationsserver_HCP5_Generierung_XIX_ComServ_XIX_HCP5_P4_E3SWPAC_XIX_DS_Hybrid_01_StMemChanged
    delegate diagnosis_infrastructure_Hybrid_01_XIX_diagnosis_infrastructure_XIX_BMC_HV.SP_IF_DS_Hybrid_01_TestFailedChanged_XIX_diagnosis_infrastructure_Hybrid_01_XIX_diagnosis_infrastructure_XIX_BMC_HV <-> outer port SP_IF_DS_Hybrid_01_TestFailedChanged_XIX_BMC_HV  # _XIX_diagnosis_infrastructure_Hybrid_01_XIX_diagnosis_infrastructure_XIX_BMC_HV_XIX_Kommunikationsserver_HCP5_Generierung_XIX_ComServ_XIX_HCP5_P4_E3SWPAC_XIX_DS_Hybrid_01_TestFailedChanged
    delegate diagnosis_infrastructure_Hybrid_01_XIX_diagnosis_infrastructure_XIX_BMC_HV.SP_IF_DS_Hybrid_01_WIRChanged_XIX_diagnosis_infrastructure_Hybrid_01_XIX_diagnosis_infrastructure_XIX_BMC_HV <-> outer port SP_IF_DS_Hybrid_01_WIRChanged_XIX_BMC_HV  # _XIX_diagnosis_infrastructure_Hybrid_01_XIX_diagnosis_infrastructure_XIX_BMC_HV_XIX_Kommunikationsserver_HCP5_Generierung_XIX_ComServ_XIX_HCP5_P4_E3SWPAC_XIX_DS_Hybrid_01_WIRChanged
    delegate diagnosis_infrastructure_Hybrid_01_XIX_diagnosis_infrastructure_XIX_BMC_HV.SP_IF_Hybrid_01_Indc_StChk_XIX_diagnosis_infrastructure_Hybrid_01_XIX_diagnosis_infrastructure_XIX_BMC_HV <-> outer port SP_IF_Hybrid_01_Indc_StChk_XIX_BMC_HV  # _XIX_diagnosis_infrastructure_Hybrid_01_XIX_diagnosis_infrastructure_XIX_BMC_HV_XIX_OBM_Inducement_Master_XIX_Fahrerinformation_OBM_XIX_VKM_XIX_Hybrid_01_Indc_StChk
    delegate diagnosis_infrastructure_Hybrid_01_XIX_diagnosis_infrastructure_XIX_BMC_HV.SP_IF_Hybrid_01_Indc_StFail_XIX_diagnosis_infrastructure_Hybrid_01_XIX_diagnosis_infrastructure_XIX_BMC_HV <-> outer port SP_IF_Hybrid_01_Indc_StFail_XIX_BMC_HV  # _XIX_diagnosis_infrastructure_Hybrid_01_XIX_diagnosis_infrastructure_XIX_BMC_HV_XIX_OBM_Inducement_Master_XIX_Fahrerinformation_OBM_XIX_VKM_XIX_Hybrid_01_Indc_StFail
    delegate diagnosis_infrastructure_Hybrid_01_XIX_diagnosis_infrastructure_XIX_BMC_HV.SP_IF_Hybrid_01_KD_Fehler_XIX_diagnosis_infrastructure_Hybrid_01_XIX_diagnosis_infrastructure_XIX_BMC_HV <-> outer port SP_IF_Hybrid_01_KD_Fehler_XIX_BMC_HV  # _XIX_diagnosis_infrastructure_Hybrid_01_XIX_diagnosis_infrastructure_XIX_BMC_HV_XIX_diagnosis_infrastructure_Gateway_XIX_diagnosis_infrastructure_XIX_HCP5_P1_Gateway_XIX_Hybrid_01_KD_Fehler
    delegate diagnosis_infrastructure_Hybrid_01_XIX_diagnosis_infrastructure_XIX_BMC_HV.SP_IF_Hybrid_01_OBD_Lampe_Anf_XIX_diagnosis_infrastructure_Hybrid_01_XIX_diagnosis_infrastructure_XIX_BMC_HV <-> outer port SP_IF_Hybrid_01_OBD_Lampe_Anf_XIX_BMC_HV  # _XIX_diagnosis_infrastructure_Hybrid_01_XIX_diagnosis_infrastructure_XIX_BMC_HV_XIX_MIL_Master_XIX_OBD_XIX_HCP1_XIX_Hybrid_01_OBD_Lampe_Anf
    delegate diagnosis_infrastructure_Hybrid_01_XIX_diagnosis_infrastructure_XIX_BMC_HV.SP_IF_Hybrid_01_SNI_10_XIX_diagnosis_infrastructure_Hybrid_01_XIX_diagnosis_infrastructure_XIX_BMC_HV <-> outer port SP_IF_Hybrid_01_SNI_10_XIX_BMC_HV  # _XIX_diagnosis_infrastructure_Hybrid_01_XIX_diagnosis_infrastructure_XIX_BMC_HV_XIX_diagnosis_infrastructure_Gateway_XIX_diagnosis_infrastructure_XIX_HCP5_P1_Gateway_XIX_Hybrid_01_SNI_10
    delegate diagnosis_infrastructure_Hybrid_01_XIX_diagnosis_infrastructure_XIX_BMC_HV.SP_IF_KN_Hybrid_01_DiagPfad_V12_XIX_diagnosis_infrastructure_Hybrid_01_XIX_diagnosis_infrastructure_XIX_BMC_HV <-> outer port SP_IF_KN_Hybrid_01_DiagPfad_V12_XIX_BMC_HV  # _XIX_diagnosis_infrastructure_Hybrid_01_XIX_diagnosis_infrastructure_XIX_BMC_HV_XIX_diagnosis_infrastructure_Gateway_XIX_diagnosis_infrastructure_XIX_HCP5_P1_Gateway_XIX_KN_Hybrid_01_DiagPfad_V12
    delegate diagnosis_infrastructure_Hybrid_01_XIX_diagnosis_infrastructure_XIX_BMC_HV.SP_IF_OBDProtocol_Hybrid_01_XIX_diagnosis_infrastructure_Hybrid_01_XIX_diagnosis_infrastructure_XIX_BMC_HV <-> outer port SP_IF_OBDProtocol_Hybrid_01_XIX_BMC_HV  # _XIX_diagnosis_infrastructure_Hybrid_01_XIX_diagnosis_infrastructure_XIX_BMC_HV_XIX_MIL_Master_XIX_OBD_XIX_HCP1_XIX_OBDProtocol_Hybrid_01
    delegate HochvoltBatterieManagement_XIX_SoC_XIX_BMC_HV.RP_IF_SI_T_Mode_XIX_HochvoltBatterieManagement_XIX_SoC_XIX_BMC_HV <-> outer port RP_IF_SI_T_Mode_XIX_BMC_HV  # _XIX_diagnosis_infrastructure_SGW04_XIX_diagnosis_infrastructure_XIX_HCP5_P2_OBD_Safety_XIX_HochvoltBatterieManagement_XIX_SoC_XIX_BMC_HV_XIX_SI_T_Mode
    delegate Infrastructure_Hybrid_01_XIX_network_infrastructure_XIX_BMC_HV.RP_IF_SI_NWDF_XIX_Infrastructure_Hybrid_01_XIX_network_infrastructure_XIX_BMC_HV <-> outer port RP_IF_SI_NWDF_XIX_BMC_HV  # _XIX_diagnosis_infrastructure_SGW04_XIX_diagnosis_infrastructure_XIX_HCP5_P2_OBD_Safety_XIX_Infrastructure_Hybrid_01_XIX_network_infrastructure_XIX_BMC_HV_XIX_SI_NWDF
    delegate Infrastructure_Hybrid_01_XIX_network_infrastructure_XIX_BMC_HV.RP_IF_SI_NWDF_30_XIX_Infrastructure_Hybrid_01_XIX_network_infrastructure_XIX_BMC_HV <-> outer port RP_IF_SI_NWDF_30_XIX_BMC_HV  # _XIX_diagnosis_infrastructure_SGW04_XIX_diagnosis_infrastructure_XIX_HCP5_P2_OBD_Safety_XIX_Infrastructure_Hybrid_01_XIX_network_infrastructure_XIX_BMC_HV_XIX_SI_NWDF_30
    delegate diagnosis_infrastructure_Hybrid_01_XIX_diagnosis_infrastructure_XIX_BMC_HV.RP_IF_SI_P_Mode_XIX_diagnosis_infrastructure_Hybrid_01_XIX_diagnosis_infrastructure_XIX_BMC_HV <-> outer port RP_IF_SI_P_Mode_XIX_BMC_HV  # _XIX_diagnosis_infrastructure_SGW04_XIX_diagnosis_infrastructure_XIX_HCP5_P2_OBD_Safety_XIX_diagnosis_infrastructure_Hybrid_01_XIX_diagnosis_infrastructure_XIX_BMC_HV_XIX_SI_P_Mode
    delegate diagnosis_infrastructure_Hybrid_01_XIX_diagnosis_infrastructure_XIX_BMC_HV.RP_IF_SI_P_Mode_gueltig_XIX_diagnosis_infrastructure_Hybrid_01_XIX_diagnosis_infrastructure_XIX_BMC_HV <-> outer port RP_IF_SI_P_Mode_gueltig_XIX_BMC_HV  # _XIX_diagnosis_infrastructure_SGW04_XIX_diagnosis_infrastructure_XIX_HCP5_P2_OBD_Safety_XIX_diagnosis_infrastructure_Hybrid_01_XIX_diagnosis_infrastructure_XIX_BMC_HV_XIX_SI_P_Mode_gueltig
    delegate diagnosis_infrastructure_Hybrid_01_XIX_diagnosis_infrastructure_XIX_BMC_HV.RP_IF_UI2Sens01_CALID_Index_03_XIX_diagnosis_infrastructure_Hybrid_01_XIX_diagnosis_infrastructure_XIX_BMC_HV <-> outer port RP_IF_UI2Sens01_CALID_Index_03_XIX_BMC_HV  # _XIX_diagnosis_infrastructure_UI2Sens01_XIX_diagnosis_infrastructure_XIX_UI2S_01_XIX_diagnosis_infrastructure_Hybrid_01_XIX_diagnosis_infrastructure_XIX_BMC_HV_XIX_UI2Sens01_CALID_Index_03
    delegate diagnosis_infrastructure_Hybrid_01_XIX_diagnosis_infrastructure_XIX_BMC_HV.RP_IF_UI2Sens01_CVN_Byte_4_XIX_diagnosis_infrastructure_Hybrid_01_XIX_diagnosis_infrastructure_XIX_BMC_HV <-> outer port RP_IF_UI2Sens01_CVN_Byte_4_XIX_BMC_HV  # _XIX_diagnosis_infrastructure_UI2Sens01_XIX_diagnosis_infrastructure_XIX_UI2S_01_XIX_diagnosis_infrastructure_Hybrid_01_XIX_diagnosis_infrastructure_XIX_BMC_HV_XIX_UI2Sens01_CVN_Byte_4
    delegate diagnosis_infrastructure_Hybrid_01_XIX_diagnosis_infrastructure_XIX_BMC_HV.RP_IF_UI2Sens01_CALID_Index_01_XIX_diagnosis_infrastructure_Hybrid_01_XIX_diagnosis_infrastructure_XIX_BMC_HV <-> outer port RP_IF_UI2Sens01_CALID_Index_01_XIX_BMC_HV  # _XIX_diagnosis_infrastructure_UI2Sens01_XIX_diagnosis_infrastructure_XIX_UI2S_01_XIX_diagnosis_infrastructure_Hybrid_01_XIX_diagnosis_infrastructure_XIX_BMC_HV_XIX_UI2Sens01_CALID_Index_01
    delegate diagnosis_infrastructure_Hybrid_01_XIX_diagnosis_infrastructure_XIX_BMC_HV.RP_IF_UI2Sens01_CALID_Index_07_XIX_diagnosis_infrastructure_Hybrid_01_XIX_diagnosis_infrastructure_XIX_BMC_HV <-> outer port RP_IF_UI2Sens01_CALID_Index_07_XIX_BMC_HV  # _XIX_diagnosis_infrastructure_UI2Sens01_XIX_diagnosis_infrastructure_XIX_UI2S_01_XIX_diagnosis_infrastructure_Hybrid_01_XIX_diagnosis_infrastructure_XIX_BMC_HV_XIX_UI2Sens01_CALID_Index_07
    delegate diagnosis_infrastructure_Hybrid_01_XIX_diagnosis_infrastructure_XIX_BMC_HV.RP_IF_UI2Sens01_CALID_Index_04_XIX_diagnosis_infrastructure_Hybrid_01_XIX_diagnosis_infrastructure_XIX_BMC_HV <-> outer port RP_IF_UI2Sens01_CALID_Index_04_XIX_BMC_HV  # _XIX_diagnosis_infrastructure_UI2Sens01_XIX_diagnosis_infrastructure_XIX_UI2S_01_XIX_diagnosis_infrastructure_Hybrid_01_XIX_diagnosis_infrastructure_XIX_BMC_HV_XIX_UI2Sens01_CALID_Index_04
    delegate diagnosis_infrastructure_Hybrid_01_XIX_diagnosis_infrastructure_XIX_BMC_HV.RP_IF_UI2Sens01_CALID_Index_15_XIX_diagnosis_infrastructure_Hybrid_01_XIX_diagnosis_infrastructure_XIX_BMC_HV <-> outer port RP_IF_UI2Sens01_CALID_Index_15_XIX_BMC_HV  # _XIX_diagnosis_infrastructure_UI2Sens01_XIX_diagnosis_infrastructure_XIX_UI2S_01_XIX_diagnosis_infrastructure_Hybrid_01_XIX_diagnosis_infrastructure_XIX_BMC_HV_XIX_UI2Sens01_CALID_Index_15
    delegate diagnosis_infrastructure_Hybrid_01_XIX_diagnosis_infrastructure_XIX_BMC_HV.RP_IF_UI2Sens01_CALID_Index_16_XIX_diagnosis_infrastructure_Hybrid_01_XIX_diagnosis_infrastructure_XIX_BMC_HV <-> outer port RP_IF_UI2Sens01_CALID_Index_16_XIX_BMC_HV  # _XIX_diagnosis_infrastructure_UI2Sens01_XIX_diagnosis_infrastructure_XIX_UI2S_01_XIX_diagnosis_infrastructure_Hybrid_01_XIX_diagnosis_infrastructure_XIX_BMC_HV_XIX_UI2Sens01_CALID_Index_16
    delegate diagnosis_infrastructure_Hybrid_01_XIX_diagnosis_infrastructure_XIX_BMC_HV.RP_IF_UI2Sens01_CALID_Index_11_XIX_diagnosis_infrastructure_Hybrid_01_XIX_diagnosis_infrastructure_XIX_BMC_HV <-> outer port RP_IF_UI2Sens01_CALID_Index_11_XIX_BMC_HV  # _XIX_diagnosis_infrastructure_UI2Sens01_XIX_diagnosis_infrastructure_XIX_UI2S_01_XIX_diagnosis_infrastructure_Hybrid_01_XIX_diagnosis_infrastructure_XIX_BMC_HV_XIX_UI2Sens01_CALID_Index_11
    delegate diagnosis_infrastructure_Hybrid_01_XIX_diagnosis_infrastructure_XIX_BMC_HV.RP_IF_UI2Sens01_CVN_Byte_3_XIX_diagnosis_infrastructure_Hybrid_01_XIX_diagnosis_infrastructure_XIX_BMC_HV <-> outer port RP_IF_UI2Sens01_CVN_Byte_3_XIX_BMC_HV  # _XIX_diagnosis_infrastructure_UI2Sens01_XIX_diagnosis_infrastructure_XIX_UI2S_01_XIX_diagnosis_infrastructure_Hybrid_01_XIX_diagnosis_infrastructure_XIX_BMC_HV_XIX_UI2Sens01_CVN_Byte_3
    delegate diagnosis_infrastructure_Hybrid_01_XIX_diagnosis_infrastructure_XIX_BMC_HV.RP_IF_UI2Sens01_ErrMem_State_XIX_diagnosis_infrastructure_Hybrid_01_XIX_diagnosis_infrastructure_XIX_BMC_HV <-> outer port RP_IF_UI2Sens01_ErrMem_State_XIX_BMC_HV  # _XIX_diagnosis_infrastructure_UI2Sens01_XIX_diagnosis_infrastructure_XIX_UI2S_01_XIX_diagnosis_infrastructure_Hybrid_01_XIX_diagnosis_infrastructure_XIX_BMC_HV_XIX_UI2Sens01_ErrMem_State
    delegate diagnosis_infrastructure_Hybrid_01_XIX_diagnosis_infrastructure_XIX_BMC_HV.RP_IF_UI2Sens01_CALID_Index_02_XIX_diagnosis_infrastructure_Hybrid_01_XIX_diagnosis_infrastructure_XIX_BMC_HV <-> outer port RP_IF_UI2Sens01_CALID_Index_02_XIX_BMC_HV  # _XIX_diagnosis_infrastructure_UI2Sens01_XIX_diagnosis_infrastructure_XIX_UI2S_01_XIX_diagnosis_infrastructure_Hybrid_01_XIX_diagnosis_infrastructure_XIX_BMC_HV_XIX_UI2Sens01_CALID_Index_02
    delegate diagnosis_infrastructure_Hybrid_01_XIX_diagnosis_infrastructure_XIX_BMC_HV.RP_IF_UI2Sens01_CALID_Index_05_XIX_diagnosis_infrastructure_Hybrid_01_XIX_diagnosis_infrastructure_XIX_BMC_HV <-> outer port RP_IF_UI2Sens01_CALID_Index_05_XIX_BMC_HV  # _XIX_diagnosis_infrastructure_UI2Sens01_XIX_diagnosis_infrastructure_XIX_UI2S_01_XIX_diagnosis_infrastructure_Hybrid_01_XIX_diagnosis_infrastructure_XIX_BMC_HV_XIX_UI2Sens01_CALID_Index_05
    delegate diagnosis_infrastructure_Hybrid_01_XIX_diagnosis_infrastructure_XIX_BMC_HV.RP_IF_UI2Sens01_CALID_Index_10_XIX_diagnosis_infrastructure_Hybrid_01_XIX_diagnosis_infrastructure_XIX_BMC_HV <-> outer port RP_IF_UI2Sens01_CALID_Index_10_XIX_BMC_HV  # _XIX_diagnosis_infrastructure_UI2Sens01_XIX_diagnosis_infrastructure_XIX_UI2S_01_XIX_diagnosis_infrastructure_Hybrid_01_XIX_diagnosis_infrastructure_XIX_BMC_HV_XIX_UI2Sens01_CALID_Index_10
    delegate diagnosis_infrastructure_Hybrid_01_XIX_diagnosis_infrastructure_XIX_BMC_HV.RP_IF_UI2Sens01_CALID_Index_09_XIX_diagnosis_infrastructure_Hybrid_01_XIX_diagnosis_infrastructure_XIX_BMC_HV <-> outer port RP_IF_UI2Sens01_CALID_Index_09_XIX_BMC_HV  # _XIX_diagnosis_infrastructure_UI2Sens01_XIX_diagnosis_infrastructure_XIX_UI2S_01_XIX_diagnosis_infrastructure_Hybrid_01_XIX_diagnosis_infrastructure_XIX_BMC_HV_XIX_UI2Sens01_CALID_Index_09
    delegate diagnosis_infrastructure_Hybrid_01_XIX_diagnosis_infrastructure_XIX_BMC_HV.RP_IF_UI2Sens01_CVN_Byte_1_XIX_diagnosis_infrastructure_Hybrid_01_XIX_diagnosis_infrastructure_XIX_BMC_HV <-> outer port RP_IF_UI2Sens01_CVN_Byte_1_XIX_BMC_HV  # _XIX_diagnosis_infrastructure_UI2Sens01_XIX_diagnosis_infrastructure_XIX_UI2S_01_XIX_diagnosis_infrastructure_Hybrid_01_XIX_diagnosis_infrastructure_XIX_BMC_HV_XIX_UI2Sens01_CVN_Byte_1
    delegate diagnosis_infrastructure_Hybrid_01_XIX_diagnosis_infrastructure_XIX_BMC_HV.RP_IF_UI2Sens01_CALID_Index_14_XIX_diagnosis_infrastructure_Hybrid_01_XIX_diagnosis_infrastructure_XIX_BMC_HV <-> outer port RP_IF_UI2Sens01_CALID_Index_14_XIX_BMC_HV  # _XIX_diagnosis_infrastructure_UI2Sens01_XIX_diagnosis_infrastructure_XIX_UI2S_01_XIX_diagnosis_infrastructure_Hybrid_01_XIX_diagnosis_infrastructure_XIX_BMC_HV_XIX_UI2Sens01_CALID_Index_14
    delegate diagnosis_infrastructure_Hybrid_01_XIX_diagnosis_infrastructure_XIX_BMC_HV.RP_IF_UI2Sens01_CVN_Byte_2_XIX_diagnosis_infrastructure_Hybrid_01_XIX_diagnosis_infrastructure_XIX_BMC_HV <-> outer port RP_IF_UI2Sens01_CVN_Byte_2_XIX_BMC_HV  # _XIX_diagnosis_infrastructure_UI2Sens01_XIX_diagnosis_infrastructure_XIX_UI2S_01_XIX_diagnosis_infrastructure_Hybrid_01_XIX_diagnosis_infrastructure_XIX_BMC_HV_XIX_UI2Sens01_CVN_Byte_2
    delegate diagnosis_infrastructure_Hybrid_01_XIX_diagnosis_infrastructure_XIX_BMC_HV.RP_IF_UI2Sens01_CALID_Index_12_XIX_diagnosis_infrastructure_Hybrid_01_XIX_diagnosis_infrastructure_XIX_BMC_HV <-> outer port RP_IF_UI2Sens01_CALID_Index_12_XIX_BMC_HV  # _XIX_diagnosis_infrastructure_UI2Sens01_XIX_diagnosis_infrastructure_XIX_UI2S_01_XIX_diagnosis_infrastructure_Hybrid_01_XIX_diagnosis_infrastructure_XIX_BMC_HV_XIX_UI2Sens01_CALID_Index_12
    delegate diagnosis_infrastructure_Hybrid_01_XIX_diagnosis_infrastructure_XIX_BMC_HV.RP_IF_UI2Sens01_CVN_VLD_XIX_diagnosis_infrastructure_Hybrid_01_XIX_diagnosis_infrastructure_XIX_BMC_HV <-> outer port RP_IF_UI2Sens01_CVN_VLD_XIX_BMC_HV  # _XIX_diagnosis_infrastructure_UI2Sens01_XIX_diagnosis_infrastructure_XIX_UI2S_01_XIX_diagnosis_infrastructure_Hybrid_01_XIX_diagnosis_infrastructure_XIX_BMC_HV_XIX_UI2Sens01_CVN_VLD
    delegate diagnosis_infrastructure_Hybrid_01_XIX_diagnosis_infrastructure_XIX_BMC_HV.RP_IF_UI2Sens01_CALID_Index_08_XIX_diagnosis_infrastructure_Hybrid_01_XIX_diagnosis_infrastructure_XIX_BMC_HV <-> outer port RP_IF_UI2Sens01_CALID_Index_08_XIX_BMC_HV  # _XIX_diagnosis_infrastructure_UI2Sens01_XIX_diagnosis_infrastructure_XIX_UI2S_01_XIX_diagnosis_infrastructure_Hybrid_01_XIX_diagnosis_infrastructure_XIX_BMC_HV_XIX_UI2Sens01_CALID_Index_08
    delegate diagnosis_infrastructure_Hybrid_01_XIX_diagnosis_infrastructure_XIX_BMC_HV.RP_IF_UI2Sens01_CALID_Index_06_XIX_diagnosis_infrastructure_Hybrid_01_XIX_diagnosis_infrastructure_XIX_BMC_HV <-> outer port RP_IF_UI2Sens01_CALID_Index_06_XIX_BMC_HV  # _XIX_diagnosis_infrastructure_UI2Sens01_XIX_diagnosis_infrastructure_XIX_UI2S_01_XIX_diagnosis_infrastructure_Hybrid_01_XIX_diagnosis_infrastructure_XIX_BMC_HV_XIX_UI2Sens01_CALID_Index_06
    delegate diagnosis_infrastructure_Hybrid_01_XIX_diagnosis_infrastructure_XIX_BMC_HV.RP_IF_UI2Sens01_CALID_Index_13_XIX_diagnosis_infrastructure_Hybrid_01_XIX_diagnosis_infrastructure_XIX_BMC_HV <-> outer port RP_IF_UI2Sens01_CALID_Index_13_XIX_BMC_HV  # _XIX_diagnosis_infrastructure_UI2Sens01_XIX_diagnosis_infrastructure_XIX_UI2S_01_XIX_diagnosis_infrastructure_Hybrid_01_XIX_diagnosis_infrastructure_XIX_BMC_HV_XIX_UI2Sens01_CALID_Index_13
    delegate diagnosis_infrastructure_Hybrid_01_XIX_diagnosis_infrastructure_XIX_BMC_HV.RP_IF_UI2Sens02_CALID_Index_15_XIX_diagnosis_infrastructure_Hybrid_01_XIX_diagnosis_infrastructure_XIX_BMC_HV <-> outer port RP_IF_UI2Sens02_CALID_Index_15_XIX_BMC_HV  # _XIX_diagnosis_infrastructure_UI2Sens02_XIX_diagnosis_infrastructure_XIX_UI2S_02_XIX_diagnosis_infrastructure_Hybrid_01_XIX_diagnosis_infrastructure_XIX_BMC_HV_XIX_UI2Sens02_CALID_Index_15
    delegate diagnosis_infrastructure_Hybrid_01_XIX_diagnosis_infrastructure_XIX_BMC_HV.RP_IF_UI2Sens02_CVN_Byte_1_XIX_diagnosis_infrastructure_Hybrid_01_XIX_diagnosis_infrastructure_XIX_BMC_HV <-> outer port RP_IF_UI2Sens02_CVN_Byte_1_XIX_BMC_HV  # _XIX_diagnosis_infrastructure_UI2Sens02_XIX_diagnosis_infrastructure_XIX_UI2S_02_XIX_diagnosis_infrastructure_Hybrid_01_XIX_diagnosis_infrastructure_XIX_BMC_HV_XIX_UI2Sens02_CVN_Byte_1
    delegate diagnosis_infrastructure_Hybrid_01_XIX_diagnosis_infrastructure_XIX_BMC_HV.RP_IF_UI2Sens02_CVN_Byte_2_XIX_diagnosis_infrastructure_Hybrid_01_XIX_diagnosis_infrastructure_XIX_BMC_HV <-> outer port RP_IF_UI2Sens02_CVN_Byte_2_XIX_BMC_HV  # _XIX_diagnosis_infrastructure_UI2Sens02_XIX_diagnosis_infrastructure_XIX_UI2S_02_XIX_diagnosis_infrastructure_Hybrid_01_XIX_diagnosis_infrastructure_XIX_BMC_HV_XIX_UI2Sens02_CVN_Byte_2
    delegate diagnosis_infrastructure_Hybrid_01_XIX_diagnosis_infrastructure_XIX_BMC_HV.RP_IF_UI2Sens02_CALID_Index_02_XIX_diagnosis_infrastructure_Hybrid_01_XIX_diagnosis_infrastructure_XIX_BMC_HV <-> outer port RP_IF_UI2Sens02_CALID_Index_02_XIX_BMC_HV  # _XIX_diagnosis_infrastructure_UI2Sens02_XIX_diagnosis_infrastructure_XIX_UI2S_02_XIX_diagnosis_infrastructure_Hybrid_01_XIX_diagnosis_infrastructure_XIX_BMC_HV_XIX_UI2Sens02_CALID_Index_02
    delegate diagnosis_infrastructure_Hybrid_01_XIX_diagnosis_infrastructure_XIX_BMC_HV.RP_IF_UI2Sens02_CALID_Index_11_XIX_diagnosis_infrastructure_Hybrid_01_XIX_diagnosis_infrastructure_XIX_BMC_HV <-> outer port RP_IF_UI2Sens02_CALID_Index_11_XIX_BMC_HV  # _XIX_diagnosis_infrastructure_UI2Sens02_XIX_diagnosis_infrastructure_XIX_UI2S_02_XIX_diagnosis_infrastructure_Hybrid_01_XIX_diagnosis_infrastructure_XIX_BMC_HV_XIX_UI2Sens02_CALID_Index_11
    delegate diagnosis_infrastructure_Hybrid_01_XIX_diagnosis_infrastructure_XIX_BMC_HV.RP_IF_UI2Sens02_ErrMem_State_XIX_diagnosis_infrastructure_Hybrid_01_XIX_diagnosis_infrastructure_XIX_BMC_HV <-> outer port RP_IF_UI2Sens02_ErrMem_State_XIX_BMC_HV  # _XIX_diagnosis_infrastructure_UI2Sens02_XIX_diagnosis_infrastructure_XIX_UI2S_02_XIX_diagnosis_infrastructure_Hybrid_01_XIX_diagnosis_infrastructure_XIX_BMC_HV_XIX_UI2Sens02_ErrMem_State
    delegate diagnosis_infrastructure_Hybrid_01_XIX_diagnosis_infrastructure_XIX_BMC_HV.RP_IF_UI2Sens02_CALID_Index_01_XIX_diagnosis_infrastructure_Hybrid_01_XIX_diagnosis_infrastructure_XIX_BMC_HV <-> outer port RP_IF_UI2Sens02_CALID_Index_01_XIX_BMC_HV  # _XIX_diagnosis_infrastructure_UI2Sens02_XIX_diagnosis_infrastructure_XIX_UI2S_02_XIX_diagnosis_infrastructure_Hybrid_01_XIX_diagnosis_infrastructure_XIX_BMC_HV_XIX_UI2Sens02_CALID_Index_01
    delegate diagnosis_infrastructure_Hybrid_01_XIX_diagnosis_infrastructure_XIX_BMC_HV.RP_IF_UI2Sens02_CALID_Index_10_XIX_diagnosis_infrastructure_Hybrid_01_XIX_diagnosis_infrastructure_XIX_BMC_HV <-> outer port RP_IF_UI2Sens02_CALID_Index_10_XIX_BMC_HV  # _XIX_diagnosis_infrastructure_UI2Sens02_XIX_diagnosis_infrastructure_XIX_UI2S_02_XIX_diagnosis_infrastructure_Hybrid_01_XIX_diagnosis_infrastructure_XIX_BMC_HV_XIX_UI2Sens02_CALID_Index_10
    delegate diagnosis_infrastructure_Hybrid_01_XIX_diagnosis_infrastructure_XIX_BMC_HV.RP_IF_UI2Sens02_CALID_Index_13_XIX_diagnosis_infrastructure_Hybrid_01_XIX_diagnosis_infrastructure_XIX_BMC_HV <-> outer port RP_IF_UI2Sens02_CALID_Index_13_XIX_BMC_HV  # _XIX_diagnosis_infrastructure_UI2Sens02_XIX_diagnosis_infrastructure_XIX_UI2S_02_XIX_diagnosis_infrastructure_Hybrid_01_XIX_diagnosis_infrastructure_XIX_BMC_HV_XIX_UI2Sens02_CALID_Index_13
    delegate diagnosis_infrastructure_Hybrid_01_XIX_diagnosis_infrastructure_XIX_BMC_HV.RP_IF_UI2Sens02_CALID_Index_03_XIX_diagnosis_infrastructure_Hybrid_01_XIX_diagnosis_infrastructure_XIX_BMC_HV <-> outer port RP_IF_UI2Sens02_CALID_Index_03_XIX_BMC_HV  # _XIX_diagnosis_infrastructure_UI2Sens02_XIX_diagnosis_infrastructure_XIX_UI2S_02_XIX_diagnosis_infrastructure_Hybrid_01_XIX_diagnosis_infrastructure_XIX_BMC_HV_XIX_UI2Sens02_CALID_Index_03
    delegate diagnosis_infrastructure_Hybrid_01_XIX_diagnosis_infrastructure_XIX_BMC_HV.RP_IF_UI2Sens02_CALID_Index_06_XIX_diagnosis_infrastructure_Hybrid_01_XIX_diagnosis_infrastructure_XIX_BMC_HV <-> outer port RP_IF_UI2Sens02_CALID_Index_06_XIX_BMC_HV  # _XIX_diagnosis_infrastructure_UI2Sens02_XIX_diagnosis_infrastructure_XIX_UI2S_02_XIX_diagnosis_infrastructure_Hybrid_01_XIX_diagnosis_infrastructure_XIX_BMC_HV_XIX_UI2Sens02_CALID_Index_06
    delegate diagnosis_infrastructure_Hybrid_01_XIX_diagnosis_infrastructure_XIX_BMC_HV.RP_IF_UI2Sens02_CALID_Index_04_XIX_diagnosis_infrastructure_Hybrid_01_XIX_diagnosis_infrastructure_XIX_BMC_HV <-> outer port RP_IF_UI2Sens02_CALID_Index_04_XIX_BMC_HV  # _XIX_diagnosis_infrastructure_UI2Sens02_XIX_diagnosis_infrastructure_XIX_UI2S_02_XIX_diagnosis_infrastructure_Hybrid_01_XIX_diagnosis_infrastructure_XIX_BMC_HV_XIX_UI2Sens02_CALID_Index_04
    delegate diagnosis_infrastructure_Hybrid_01_XIX_diagnosis_infrastructure_XIX_BMC_HV.RP_IF_UI2Sens02_CALID_Index_08_XIX_diagnosis_infrastructure_Hybrid_01_XIX_diagnosis_infrastructure_XIX_BMC_HV <-> outer port RP_IF_UI2Sens02_CALID_Index_08_XIX_BMC_HV  # _XIX_diagnosis_infrastructure_UI2Sens02_XIX_diagnosis_infrastructure_XIX_UI2S_02_XIX_diagnosis_infrastructure_Hybrid_01_XIX_diagnosis_infrastructure_XIX_BMC_HV_XIX_UI2Sens02_CALID_Index_08
    delegate diagnosis_infrastructure_Hybrid_01_XIX_diagnosis_infrastructure_XIX_BMC_HV.RP_IF_UI2Sens02_CALID_Index_12_XIX_diagnosis_infrastructure_Hybrid_01_XIX_diagnosis_infrastructure_XIX_BMC_HV <-> outer port RP_IF_UI2Sens02_CALID_Index_12_XIX_BMC_HV  # _XIX_diagnosis_infrastructure_UI2Sens02_XIX_diagnosis_infrastructure_XIX_UI2S_02_XIX_diagnosis_infrastructure_Hybrid_01_XIX_diagnosis_infrastructure_XIX_BMC_HV_XIX_UI2Sens02_CALID_Index_12
    delegate diagnosis_infrastructure_Hybrid_01_XIX_diagnosis_infrastructure_XIX_BMC_HV.RP_IF_UI2Sens02_CALID_Index_05_XIX_diagnosis_infrastructure_Hybrid_01_XIX_diagnosis_infrastructure_XIX_BMC_HV <-> outer port RP_IF_UI2Sens02_CALID_Index_05_XIX_BMC_HV  # _XIX_diagnosis_infrastructure_UI2Sens02_XIX_diagnosis_infrastructure_XIX_UI2S_02_XIX_diagnosis_infrastructure_Hybrid_01_XIX_diagnosis_infrastructure_XIX_BMC_HV_XIX_UI2Sens02_CALID_Index_05
    delegate diagnosis_infrastructure_Hybrid_01_XIX_diagnosis_infrastructure_XIX_BMC_HV.RP_IF_UI2Sens02_CVN_Byte_3_XIX_diagnosis_infrastructure_Hybrid_01_XIX_diagnosis_infrastructure_XIX_BMC_HV <-> outer port RP_IF_UI2Sens02_CVN_Byte_3_XIX_BMC_HV  # _XIX_diagnosis_infrastructure_UI2Sens02_XIX_diagnosis_infrastructure_XIX_UI2S_02_XIX_diagnosis_infrastructure_Hybrid_01_XIX_diagnosis_infrastructure_XIX_BMC_HV_XIX_UI2Sens02_CVN_Byte_3
    delegate diagnosis_infrastructure_Hybrid_01_XIX_diagnosis_infrastructure_XIX_BMC_HV.RP_IF_UI2Sens02_CALID_Index_09_XIX_diagnosis_infrastructure_Hybrid_01_XIX_diagnosis_infrastructure_XIX_BMC_HV <-> outer port RP_IF_UI2Sens02_CALID_Index_09_XIX_BMC_HV  # _XIX_diagnosis_infrastructure_UI2Sens02_XIX_diagnosis_infrastructure_XIX_UI2S_02_XIX_diagnosis_infrastructure_Hybrid_01_XIX_diagnosis_infrastructure_XIX_BMC_HV_XIX_UI2Sens02_CALID_Index_09
    delegate diagnosis_infrastructure_Hybrid_01_XIX_diagnosis_infrastructure_XIX_BMC_HV.RP_IF_UI2Sens02_CVN_VLD_XIX_diagnosis_infrastructure_Hybrid_01_XIX_diagnosis_infrastructure_XIX_BMC_HV <-> outer port RP_IF_UI2Sens02_CVN_VLD_XIX_BMC_HV  # _XIX_diagnosis_infrastructure_UI2Sens02_XIX_diagnosis_infrastructure_XIX_UI2S_02_XIX_diagnosis_infrastructure_Hybrid_01_XIX_diagnosis_infrastructure_XIX_BMC_HV_XIX_UI2Sens02_CVN_VLD
    delegate diagnosis_infrastructure_Hybrid_01_XIX_diagnosis_infrastructure_XIX_BMC_HV.RP_IF_UI2Sens02_CALID_Index_07_XIX_diagnosis_infrastructure_Hybrid_01_XIX_diagnosis_infrastructure_XIX_BMC_HV <-> outer port RP_IF_UI2Sens02_CALID_Index_07_XIX_BMC_HV  # _XIX_diagnosis_infrastructure_UI2Sens02_XIX_diagnosis_infrastructure_XIX_UI2S_02_XIX_diagnosis_infrastructure_Hybrid_01_XIX_diagnosis_infrastructure_XIX_BMC_HV_XIX_UI2Sens02_CALID_Index_07
    delegate diagnosis_infrastructure_Hybrid_01_XIX_diagnosis_infrastructure_XIX_BMC_HV.RP_IF_UI2Sens02_CALID_Index_16_XIX_diagnosis_infrastructure_Hybrid_01_XIX_diagnosis_infrastructure_XIX_BMC_HV <-> outer port RP_IF_UI2Sens02_CALID_Index_16_XIX_BMC_HV  # _XIX_diagnosis_infrastructure_UI2Sens02_XIX_diagnosis_infrastructure_XIX_UI2S_02_XIX_diagnosis_infrastructure_Hybrid_01_XIX_diagnosis_infrastructure_XIX_BMC_HV_XIX_UI2Sens02_CALID_Index_16
    delegate diagnosis_infrastructure_Hybrid_01_XIX_diagnosis_infrastructure_XIX_BMC_HV.RP_IF_UI2Sens02_CALID_Index_14_XIX_diagnosis_infrastructure_Hybrid_01_XIX_diagnosis_infrastructure_XIX_BMC_HV <-> outer port RP_IF_UI2Sens02_CALID_Index_14_XIX_BMC_HV  # _XIX_diagnosis_infrastructure_UI2Sens02_XIX_diagnosis_infrastructure_XIX_UI2S_02_XIX_diagnosis_infrastructure_Hybrid_01_XIX_diagnosis_infrastructure_XIX_BMC_HV_XIX_UI2Sens02_CALID_Index_14
    delegate diagnosis_infrastructure_Hybrid_01_XIX_diagnosis_infrastructure_XIX_BMC_HV.RP_IF_UI2Sens02_CVN_Byte_4_XIX_diagnosis_infrastructure_Hybrid_01_XIX_diagnosis_infrastructure_XIX_BMC_HV <-> outer port RP_IF_UI2Sens02_CVN_Byte_4_XIX_BMC_HV  # _XIX_diagnosis_infrastructure_UI2Sens02_XIX_diagnosis_infrastructure_XIX_UI2S_02_XIX_diagnosis_infrastructure_Hybrid_01_XIX_diagnosis_infrastructure_XIX_BMC_HV_XIX_UI2Sens02_CVN_Byte_4
